VERSION ""

NS_ :

BS_:

BU_: Turbocharger OnBoardDataLogger OffBoardDiagnosticTool2 OffBoardDiagnosticTool1 FileServer ParkingBrakeController SeatControl2 FanDriveController SteeringColumnUnit CommunicationUnitRadio CommunicationUnitSatellite CommunicationUnitCellular PropulsionBatteryCharger ChassisController2 ChassisController1 EngineValveControl AuxiliaryHeater2 AuxiliaryHeater1 ClutchUnit RampControl InformationSystem1 SuspensionSystemController2 OilSensor VehicleDynamicStability ExhaustEmissionController TransmissionDisplay2 TransmissionDisplay1 ClimateControl2 WaterPumpController RearAxleSteeringController LightingOperatorControl SeatController1 IgnitionController2 IgnitionController1 TirePressureController CabController2 CabController1 PneumaticSystemController SuspensionSystemController1 HydraulicPumpController EnduranceBrakingSystem RetarderExhaustEngine2 OnBoardDiagnosticUnit HeadwayController RetarderExhaustEngine1 CabDisplay1 ManagementComputer VirtualTerminal OffVehicleGateway PowerTakeOffFront HitchControl AuxiliaryValveControl BodyController TractorTrailerBridge1 StarterSystem ElectricalSystem VehicleSecurity VehicleNavigation AerodynamicControl ElectricalChargingSystem ClimateControl1 TripRecorder InstrumentCluster SuspensionDriveAxle2 SuspensionDriveAxle1 SuspensionSteerAxle SteeringController FuelSystem CruiseControl RetarderDriveline RetarderEngine BrakesDriveAxle2 BrakesDriveAxle1 BrakesSystemController BrakesSteerAxle AxleDrive2 AxleDrive1 AxleSteering PowerTakeOff ShiftConsoleSecondary ShiftConsolePrimary Transmission2 Transmission1 Engine2 Engine1

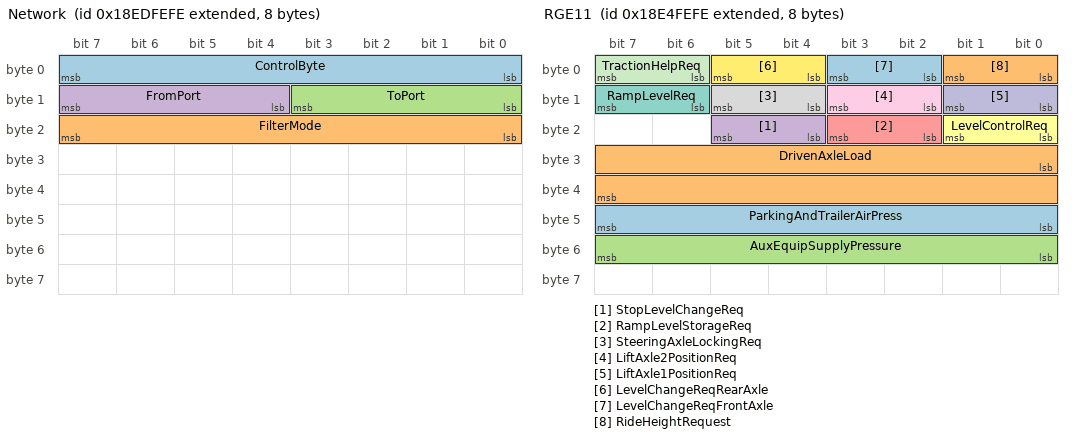
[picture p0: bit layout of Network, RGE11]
BO_ 2565734142 Network: 8 Vector__XXX
 SG_ ControlByte : 0|8@1+ (1,0) [0|255] "" Vector__XXX
 SG_ FilterMode : 16|8@1+ (1,0) [0|255] "" Vector__XXX
 SG_ ToPort : 8|4@1+ (1,0) [0|15] "" Vector__XXX
 SG_ FromPort : 12|4@1+ (1,0) [0|15] "" Vector__XXX

BO_ 2565144318 RGE11: 8 Vector__XXX
 SG_ ParkingAndTrailerAirPress : 40|8@1+ (8,0) [0|2000] "kPa" Vector__XXX
 SG_ DrivenAxleLoad : 24|16@1+ (2,0) [0|128510] "kg" Vector__XXX
 SG_ AuxEquipSupplyPressure : 48|8@1+ (8,0) [0|2000] "kPa" Vector__XXX
 SG_ StopLevelChangeReq : 20|2@1+ (1,0) [0|3] "" Vector__XXX
 SG_ RampLevelStorageReq : 18|2@1+ (1,0) [0|3] "" Vector__XXX
 SG_ LevelControlReq : 16|2@1+ (1,0) [0|3] "" Vector__XXX
 SG_ RampLevelReq : 14|2@1+ (1,0) [0|3] "" Vector__XXX
 SG_ SteeringAxleLockingReq : 12|2@1+ (1,0) [0|3] "" Vector__XXX
 SG_ LiftAxle2PositionReq : 10|2@1+ (1,0) [0|3] "" Vector__XXX
 SG_ LiftAxle1PositionReq : 8|2@1+ (1,0) [0|3] "" Vector__XXX
 SG_ TractionHelpReq : 6|2@1+ (1,0) [0|3] "" Vector__XXX
 SG_ LevelChangeReqRearAxle : 4|2@1+ (1,0) [0|3] "" Vector__XXX
 SG_ LevelChangeReqFrontAxle : 2|2@1+ (1,0) [0|3] "" Vector__XXX
 SG_ RideHeightRequest : 0|2@1+ (1,0) [0|3] "" Vector__XXX

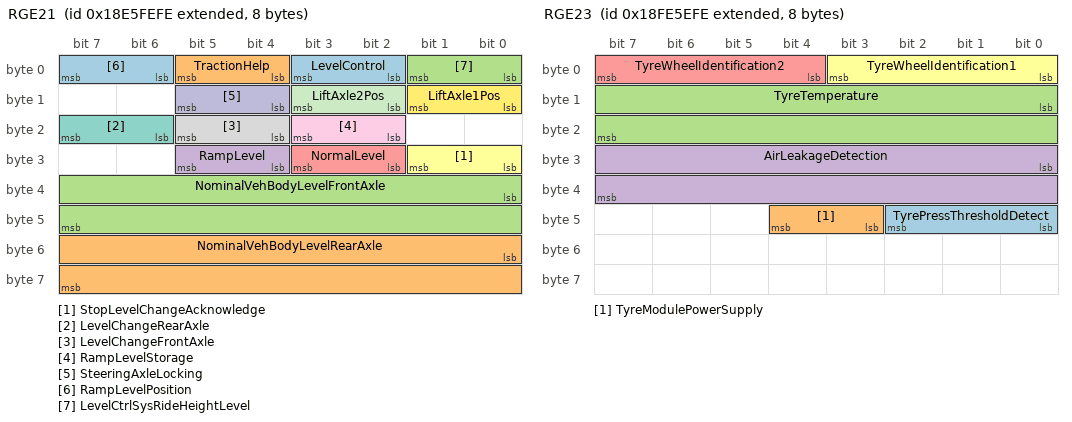
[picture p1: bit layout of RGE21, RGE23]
BO_ 2565209854 RGE21: 8 Vector__XXX
 SG_ LevelControl : 2|2@1+ (1,0) [0|1] "" Vector__XXX
 SG_ NominalVehBodyLevelRearAxle : 48|16@1+ (1,0) [0|64255] "mm" Vector__XXX
 SG_ NominalVehBodyLevelFrontAxle : 32|16@1+ (1,0) [0|64255] "mm" Vector__XXX
 SG_ RampLevel : 28|2@1+ (1,0) [0|1] "" Vector__XXX
 SG_ NormalLevel : 26|2@1+ (1,0) [0|3] "" Vector__XXX
 SG_ StopLevelChangeAcknowledge : 24|2@1+ (1,0) [0|1] "" Vector__XXX
 SG_ LevelChangeRearAxle : 22|2@1+ (1,0) [0|1] "" Vector__XXX
 SG_ LevelChangeFrontAxle : 20|2@1+ (1,0) [0|1] "" Vector__XXX
 SG_ RampLevelStorage : 18|2@1+ (1,0) [0|1] "" Vector__XXX
 SG_ SteeringAxleLocking : 12|2@1+ (1,0) [0|3] "" Vector__XXX
 SG_ LiftAxle2Pos : 10|2@1+ (1,0) [0|3] "" Vector__XXX
 SG_ LiftAxle1Pos : 8|2@1+ (1,0) [0|3] "" Vector__XXX
 SG_ RampLevelPosition : 6|2@1+ (1,0) [0|3] "" Vector__XXX
 SG_ TractionHelp : 4|2@1+ (1,0) [0|1] "" Vector__XXX
 SG_ LevelCtrlSysRideHeightLevel : 0|2@1+ (1,0) [0|1] "" Vector__XXX

BO_ 2566806782 RGE22: 8 Vector__XXX
 SG_ RelVehBodyLevelRearAxle : 16|16@1+ (1,0) [0|64255] "mm" Vector__XXX
 SG_ RelVehBodyLevelFrontAxle : 0|16@1+ (1,-32000) [-32000|32255] "mm" Vector__XXX

BO_ 2566807294 RGE23: 8 Vector__XXX
 SG_ TyrePressThresholdDetect : 40|3@1+ (1,0) [0|7] "" Vector__XXX
 SG_ TyreModulePowerSupply : 43|2@1+ (1,0) [0|1] "" Vector__XXX
 SG_ TyreTemperature : 8|16@1+ (0.03125,-273) [-273|1735] "°C" Vector__XXX
 SG_ AirLeakageDetection : 24|16@1+ (0.1,0) [0|6425.5] "Pa/s" Vector__XXX
 SG_ TyreWheelIdentification2 : 4|4@1+ (1,0) [0|15] "" Vector__XXX
 SG_ TyreWheelIdentification1 : 0|4@1+ (1,0) [0|15] "" Vector__XXX

BO_ 2566764798 DM26: 8 Vector__XXX
 SG_ NMHCConvertingCatalystCompleted : 60|1@1+ (1,0) [0|1] "" Vector__XXX
 SG_ NMHCConvertingCatalystEnabled : 44|1@1+ (1,0) [0|1] "" Vector__XXX
 SG_ NOxConvertingCatalystAdsorberCom : 59|1@1+ (1,0) [0|1] "" Vector__XXX
 SG_ NOxConvertingCatalystAdsorberEna : 43|1@1+ (1,0) [0|1] "" Vector__XXX
 SG_ DieselParticulateFilterCompleted : 58|1@1+ (1,0) [0|1] "" Vector__XXX
 SG_ DieselParticulateFilterEnabled : 42|1@1+ (1,0) [0|1] "" Vector__XXX
 SG_ BoostPressureControlSystemComple : 57|1@1+ (1,0) [0|1] "" Vector__XXX
 SG_ BoostPressureControlSystemEnable : 41|1@1- (1,0) [0|0] "" Vector__XXX
 SG_ MisfireMonitoringComplete : 28|1@1+ (1,0) [0|1] "" Vector__XXX
 SG_ MisfireMonitoringEnabled : 24|1@1+ (1,0) [0|0] "" Vector__XXX
 SG_ FuelSystemMonitoringEnabled : 25|1@1+ (1,0) [0|1] "" Vector__XXX
 SG_ ComprehensiveComptMonComplete : 30|1@1+ (1,0) [0|1] "" Vector__XXX
 SG_ ComprehensiveCompMonEnabled : 26|1@1+ (1,0) [0|1] "" Vector__XXX
 SG_ SecondAirSystemMonComplete : 51|1@1+ (1,0) [0|1] "" Vector__XXX
 SG_ SecondAirSystemMonEnabled : 35|1@1+ (1,0) [0|1] "" Vector__XXX
 SG_ OxygenSensorMonComplete : 53|1@1+ (1,0) [0|1] "" Vector__XXX
 SG_ OxygenSensorMonEnabled : 37|1@1+ (1,0) [0|1] "" Vector__XXX
 SG_ OxygenSensorHeaterMonComplete : 54|1@1+ (1,0) [0|1] "" Vector__XXX
 SG_ OxygenSensorHeaterMonEnabled : 38|1@1+ (1,0) [0|1] "" Vector__XXX
 SG_ HeatedCatalystMonComplete : 49|1@1+ (1,0) [0|1] "" Vector__XXX
 SG_ HeatedCatalystMonEnabled : 33|1@1+ (1,0) [0|1] "" Vector__XXX
 SG_ EvaporativeSystemMonComplete : 50|1@1+ (1,0) [0|1] "" Vector__XXX
 SG_ EvaporativeSystemMonEnabled : 34|1@1+ (1,0) [0|1] "" Vector__XXX
 SG_ EGRSystemMonitoringComplete : 55|1@1+ (1,0) [0|1] "" Vector__XXX
 SG_ EGRSystemMonitoringEnabled : 39|1@1+ (1,0) [0|1] "" Vector__XXX
 SG_ ColdStartAidSystemMonComplete : 56|1@1+ (1,0) [0|1] "" Vector__XXX
 SG_ ColdStartAidSystemMonEnabled : 40|1@1+ (1,0) [0|1] "" Vector__XXX
 SG_ CatalystMonComplete : 48|1@1+ (1,0) [0|1] "" Vector__XXX
 SG_ CatalystMonEnabled : 32|1@1+ (1,0) [0|1] "" Vector__XXX
 SG_ ACSystemRefrigerantMonComplete : 52|1@1+ (1,0) [0|1] "" Vector__XXX
 SG_ ACSystemRefrigerantMonEnabled : 36|1@1+ (1,0) [0|1] "" Vector__XXX
 SG_ FuelSystemMonitoringComplete : 29|1@1+ (1,0) [0|1] "" Vector__XXX
 SG_ NumOfWarmUpsSinceDTCsCleared : 16|8@1+ (1,0) [0|250] "" Vector__XXX
 SG_ TimeSinceEngineStart : 0|16@1+ (1,0) [0|64255] "sec" Vector__XXX

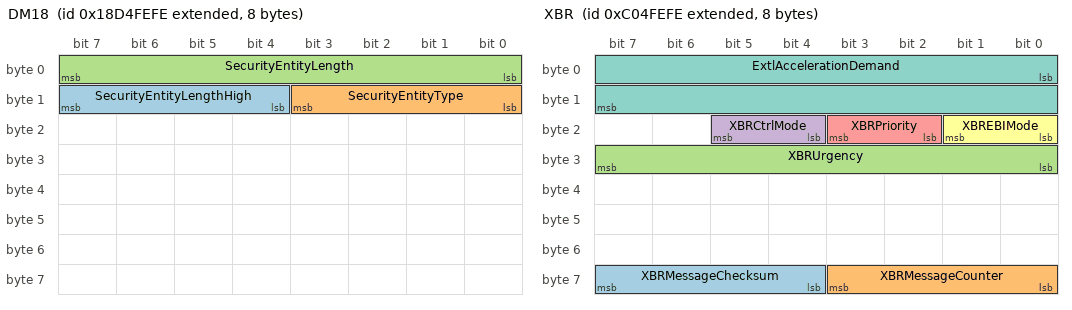
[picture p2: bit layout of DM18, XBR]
BO_ 2564095742 DM18: 8 Vector__XXX
 SG_ SecurityEntityLengthHigh : 12|4@1+ (1,0) [0|255] "Byte" Vector__XXX
 SG_ SecurityEntityType : 8|4@1+ (1,0) [0|15] "" Vector__XXX
 SG_ SecurityEntityLength : 0|8@1+ (1,0) [0|1785] "Byte" Vector__XXX

BO_ 2349137662 XBR: 8 Vector__XXX
 SG_ XBRMessageChecksum : 60|4@1+ (1,0) [0|15] "" Vector__XXX
 SG_ XBRMessageCounter : 56|4@1+ (1,0) [0|15] "" Vector__XXX
 SG_ XBRUrgency : 24|8@1+ (1,0) [0|100] "%" Vector__XXX
 SG_ XBRCtrlMode : 20|2@1+ (1,0) [0|3] "" Vector__XXX
 SG_ XBRPriority : 18|2@1+ (1,0) [0|3] "" Vector__XXX
 SG_ XBREBIMode : 16|2@1+ (1,0) [0|3] "" Vector__XXX
 SG_ ExtlAccelerationDemand : 0|16@1+ (1,-15.687) [-15.687|15.687] "m/s²" Vector__XXX

BO_ 2566848510 WFI: 8 Vector__XXX
 SG_ WaterInFuelIndicator : 0|2@1+ (1,0) [0|3] "" Vector__XXX

BO_ 2566843134 VW: 8 Vector__XXX
 SG_ AxleLocation M : 0|8@1+ (1,0) [0|255] "" Vector__XXX
 SG_ CargoWeight_30 m48 : 40|16@1+ (2,0) [0|128510] "kg" Vector__XXX
 SG_ CargoWeight_20 m32 : 40|16@1+ (2,0) [0|128510] "kg" Vector__XXX
 SG_ CargoWeight_10 m16 : 40|16@1+ (2,0) [0|128510] "kg" Vector__XXX
 SG_ CargoWeight_00 m0 : 40|16@1+ (2,0) [0|128510] "kg" Vector__XXX
 SG_ TrailerWeight_30 m48 : 24|16@1+ (2,0) [0|128510] "kg" Vector__XXX
 SG_ TrailerWeight_20 m32 : 24|16@1+ (2,0) [0|128510] "kg" Vector__XXX
 SG_ TrailerWeight_10 m16 : 24|16@1+ (2,0) [0|128510] "kg" Vector__XXX
 SG_ TrailerWeight_00 m0 : 24|16@1+ (2,0) [0|128510] "kg" Vector__XXX
 SG_ AxleWeight_30 m48 : 8|16@1+ (0.5,0) [0|32127.5] "kg" Vector__XXX
 SG_ AxleWeight_20 m32 : 8|16@1+ (0.5,0) [0|32127.5] "kg" Vector__XXX
 SG_ AxleWeight_10 m16 : 8|16@1+ (0.5,0) [0|32127.5] "kg" Vector__XXX
 SG_ AxleWeight_00 m0 : 8|16@1+ (0.5,0) [0|32127.5] "kg" Vector__XXX

BO_ 2566804222 VEP3: 8 Vector__XXX
 SG_ NetBatteryCurrent : 16|16@1+ (0.05,-1600) [-1600|1612.75] "A" Vector__XXX
 SG_ AltCurrent : 0|16@1+ (0.05,-1600) [-1600|1612.75] "A" Vector__XXX

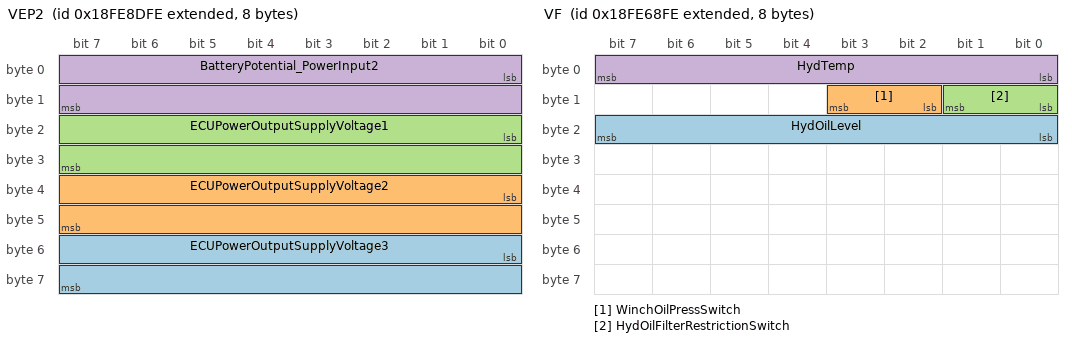
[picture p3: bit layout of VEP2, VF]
BO_ 2566819326 VEP2: 8 Vector__XXX
 SG_ ECUPowerOutputSupplyVoltage3 : 48|16@1+ (0.05,0) [0|3212.75] "V" Vector__XXX
 SG_ ECUPowerOutputSupplyVoltage2 : 32|16@1+ (0.05,0) [0|3212.75] "V" Vector__XXX
 SG_ ECUPowerOutputSupplyVoltage1 : 16|16@1+ (0.05,0) [0|3212.75] "V" Vector__XXX
 SG_ BatteryPotential_PowerInput2 : 0|16@1+ (0.05,0) [0|3212.75] "V" Vector__XXX

BO_ 2566845438 VP: 8 Vector__XXX
 SG_ Longitude : 32|32@1- (1E-007,0) [-180|180] "deg" Vector__XXX
 SG_ Latitude : 0|32@1- (1E-007,0) [-90|90] "deg" Vector__XXX

BO_ 2566843646 VI: 8 Vector__XXX
 SG_ VehicleIdentificationNumber : 0|8@1+ (1.02,0) [0|255] "per byte" Vector__XXX

BO_ 2566842366 VH: 8 Vector__XXX
 SG_ TotalPowerTakeoffHours : 32|32@1+ (0.05,0) [0|210554060.75] "hr" Vector__XXX
 SG_ TotalVehicleHours : 0|32@1+ (0.05,0) [0|210554060.75] "hr" Vector__XXX

BO_ 2566809854 VF: 8 Vector__XXX
 SG_ HydOilLevel : 16|8@1+ (0.4,0) [0|100] "%" Vector__XXX
 SG_ WinchOilPressSwitch : 10|2@1+ (1,0) [0|3] "" Vector__XXX
 SG_ HydOilFilterRestrictionSwitch : 8|2@1+ (1,0) [0|3] "" Vector__XXX
 SG_ HydTemp : 0|8@1+ (1,-40) [-40|210] "deg C" Vector__XXX

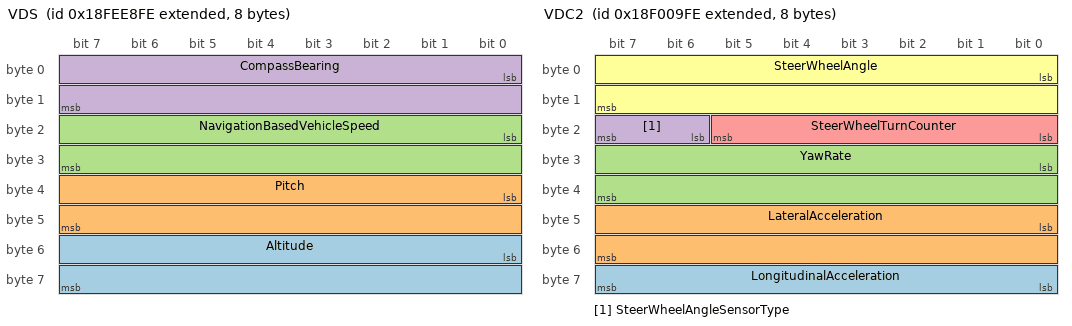
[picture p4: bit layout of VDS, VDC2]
BO_ 2566842622 VDS: 8 Vector__XXX
 SG_ Altitude : 48|16@1+ (0.125,-2500) [-2500|5531.875] "m" Vector__XXX
 SG_ Pitch : 32|16@1+ (0.0078124659559567,-200) [-200|301.99] "deg" Vector__XXX
 SG_ NavigationBasedVehicleSpeed : 16|16@1+ (0.0039062485409696,0) [0|250.996] "km/h" Vector__XXX
 SG_ CompassBearing : 0|16@1+ (0.0078124659559567,0) [0|501.99] "deg" Vector__XXX

BO_ 2566832638 VDHR: 8 Vector__XXX
 SG_ HighResolutionTripDistance : 32|32@1+ (0.0049999999821898,0) [0|21055406] "km" Vector__XXX
 SG_ HghRsolutionTotalVehicleDistance : 0|32@1+ (0.0049999999821898,0) [0|21055406] "km" Vector__XXX

BO_ 2565868030 VDC2: 8 Vector__XXX
 SG_ LongitudinalAcceleration : 56|8@1+ (0.1,-12.5) [-12.5|12.5] "m/s²" Vector__XXX
 SG_ LateralAcceleration : 40|16@1+ (0.00048827328612559,-15.687) [-15.687|15.687] "m/s²" Vector__XXX
 SG_ YawRate : 24|16@1+ (0.00012201385106217,-3.92) [-3.92|3.92] "rad/s" Vector__XXX
 SG_ SteerWheelAngleSensorType : 22|2@1+ (1,0) [0|3] "" Vector__XXX
 SG_ SteerWheelTurnCounter : 16|6@1+ (1,-32) [-32|29] "turns" Vector__XXX
 SG_ SteerWheelAngle : 0|16@1+ (0.00097654657225119,-31.374) [-31.374|31.374] "rad" Vector__XXX

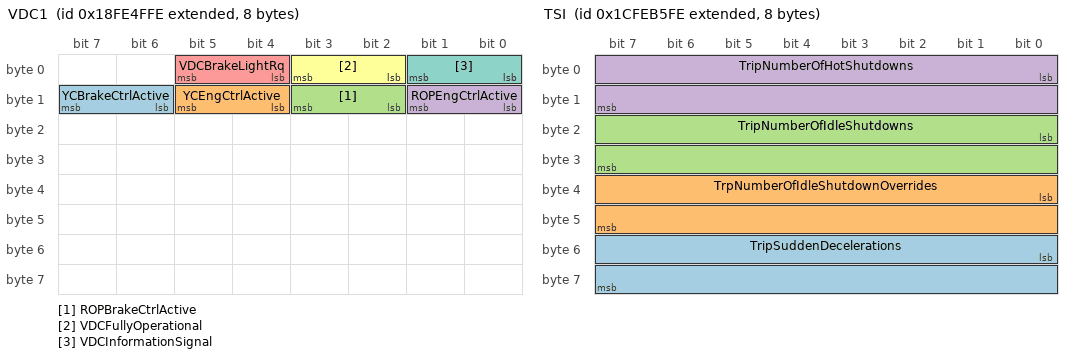
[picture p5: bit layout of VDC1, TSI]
BO_ 2566803454 VDC1: 8 Vector__XXX
 SG_ YCBrakeCtrlActive : 14|2@1+ (1,0) [0|3] "" Vector__XXX
 SG_ YCEngCtrlActive : 12|2@1+ (1,0) [0|3] "" Vector__XXX
 SG_ ROPBrakeCtrlActive : 10|2@1+ (1,0) [0|3] "" Vector__XXX
 SG_ ROPEngCtrlActive : 8|2@1+ (1,0) [0|3] "" Vector__XXX
 SG_ VDCBrakeLightRq : 4|2@1+ (1,0) [0|3] "" Vector__XXX
 SG_ VDCFullyOperational : 2|2@1+ (1,0) [0|3] "" Vector__XXX
 SG_ VDCInformationSignal : 0|2@1+ (1,0) [0|3] "" Vector__XXX

BO_ 2566840574 VD: 8 Vector__XXX
 SG_ TotalVehicleDistance : 32|32@1+ (0.12500000000594,0) [0|526385151.9] "km" Vector__XXX
 SG_ TripDistance : 0|32@1+ (0.12500000000594,0) [0|526385151.9] "km" Vector__XXX

BO_ 2633938686 TVI: 8 Vector__XXX
 SG_ TripCruiseDistance : 16|32@1+ (0.12500000000594,0) [0|526385151.9] "km" Vector__XXX
 SG_ TripMaxVehicleSpeed : 0|16@1+ (0.0039062485409696,0) [0|250.996] "km/h" Vector__XXX

BO_ 2633937150 TTI2: 20 Vector__XXX
 SG_ TripAirCompressorOnTime : 128|32@1+ (0.05,0) [0|210554060.75] "hr" Vector__XXX
 SG_ TripIdleTime : 96|32@1+ (0.05,0) [0|210554060.75] "hr" Vector__XXX
 SG_ TripEngRunningTime : 64|32@1+ (0.05,0) [0|210554060.75] "hr" Vector__XXX
 SG_ TripCruiseTime : 0|32@1+ (0.05,0) [0|210554060.75] "hr" Vector__XXX
 SG_ TripPTOGovernorTime : 32|32@1+ (0.05,0) [0|210554060.75] "hr" Vector__XXX

BO_ 2633938174 TTI1: 16 Vector__XXX
 SG_ TripTimeInDerateByEng : 96|32@1+ (0.05,0) [0|210554060.75] "hr" Vector__XXX
 SG_ TripTimeInGearDown : 64|32@1+ (0.05,0) [0|210554060.75] "hr" Vector__XXX
 SG_ TripTimeInTopGear : 32|32@1+ (0.05,0) [0|210554060.75] "hr" Vector__XXX
 SG_ TripTimeInVSL : 0|32@1+ (0.05,0) [0|210554060.75] "hr" Vector__XXX

BO_ 2633938430 TSI: 8 Vector__XXX
 SG_ TripSuddenDecelerations : 48|16@1+ (1,0) [0|64255] "counts" Vector__XXX
 SG_ TrpNumberOfIdleShutdownOverrides : 32|16@1+ (1,0) [0|64255] "counts" Vector__XXX
 SG_ TripNumberOfIdleShutdowns : 16|16@1+ (1,0) [0|64255] "counts" Vector__XXX
 SG_ TripNumberOfHotShutdowns : 0|16@1+ (1,0) [0|64255] "counts" Vector__XXX

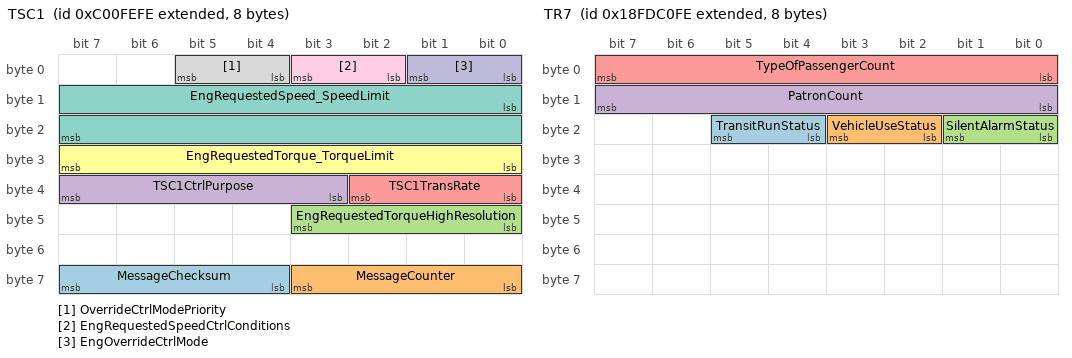
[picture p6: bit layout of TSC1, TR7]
BO_ 2348875518 TSC1: 8 Vector__XXX
 SG_ MessageChecksum : 60|4@1+ (1,0) [0|15] "" Vector__XXX
 SG_ MessageCounter : 56|4@1+ (1,0) [0|15] "" Vector__XXX
 SG_ EngRequestedTorqueHighResolution : 40|4@1+ (1,0) [0|0.875] "%" Vector__XXX
 SG_ TSC1CtrlPurpose : 35|5@1+ (1,0) [0|31] "" Vector__XXX
 SG_ TSC1TransRate : 32|3@1+ (1,0) [0|7] "" Vector__XXX
 SG_ EngRequestedTorque_TorqueLimit : 24|8@1+ (1,-125) [-125|125] "%" Vector__XXX
 SG_ EngRequestedSpeed_SpeedLimit : 8|16@1+ (0.125,0) [0|0] "rpm" Vector__XXX
 SG_ OverrideCtrlModePriority : 4|2@1+ (1,0) [0|3] "" Vector__XXX
 SG_ EngRequestedSpeedCtrlConditions : 2|2@1+ (1,0) [0|3] "" Vector__XXX
 SG_ EngOverrideCtrlMode : 0|2@1+ (1,0) [0|3] "" Vector__XXX

BO_ 2566766846 TR7: 8 Vector__XXX
 SG_ TransitRunStatus : 20|2@1+ (1,0) [0|3] "" Vector__XXX
 SG_ VehicleUseStatus : 18|2@1+ (1,0) [0|3] "" Vector__XXX
 SG_ SilentAlarmStatus : 16|2@1+ (1,0) [0|3] "" Vector__XXX
 SG_ PatronCount : 8|8@1+ (1,0) [0|250] "" Vector__XXX
 SG_ TypeOfPassengerCount : 0|8@1+ (1.02,0) [0|255] "" Vector__XXX

BO_ 2566765310 TR6: 8 Vector__XXX
 SG_ FareboxAlarmIdentifier : 8|7@1+ (1,0) [0|127] "" Vector__XXX
 SG_ FareboxEmergencyStatus : 0|2@1+ (1,0) [0|3] "" Vector__XXX

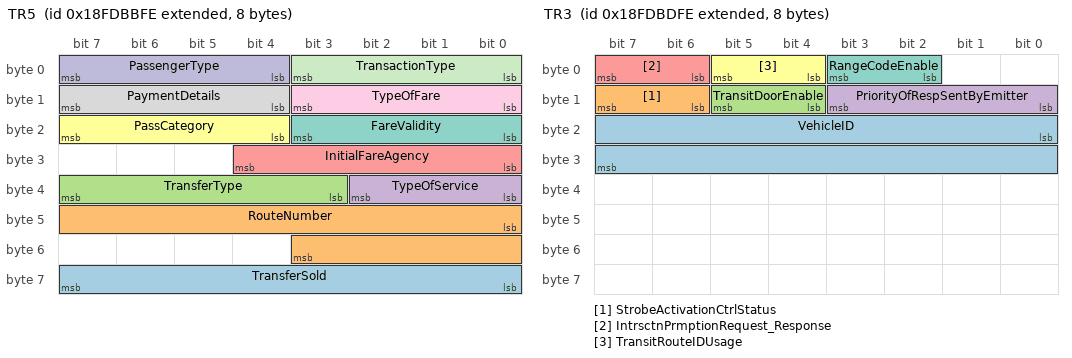
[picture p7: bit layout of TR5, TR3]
BO_ 2566765566 TR5: 8 Vector__XXX
 SG_ TransferSold : 56|8@1+ (1.02,0) [0|255] "" Vector__XXX
 SG_ RouteNumber : 40|12@1+ (1,0) [0|4095] "" Vector__XXX
 SG_ TransferType : 35|5@1+ (1,0) [0|31] "" Vector__XXX
 SG_ TypeOfService : 32|3@1+ (1,0) [0|7] "" Vector__XXX
 SG_ InitialFareAgency : 24|5@1+ (1,0) [0|31] "" Vector__XXX
 SG_ PassCategory : 20|4@1+ (1,0) [0|15] "" Vector__XXX
 SG_ FareValidity : 16|4@1+ (1,0) [0|15] "" Vector__XXX
 SG_ PaymentDetails : 12|4@1+ (1,0) [0|15] "" Vector__XXX
 SG_ TypeOfFare : 8|4@1+ (1,0) [0|15] "" Vector__XXX
 SG_ PassengerType : 4|4@1+ (1,0) [0|15] "" Vector__XXX
 SG_ TransactionType : 0|4@1+ (1,0) [0|15] "" Vector__XXX

BO_ 2566765822 TR4: 15 Vector__XXX
 SG_ DriversFareboxSecurityCode : 104|16@1+ (1.0199206287448,0) [0|65535] "counts" Vector__XXX
 SG_ AssignedBlock : 88|16@1+ (1.0199206287448,0) [0|65535] "counts" Vector__XXX
 SG_ AssignedRun : 72|16@1+ (1.0199206287448,0) [0|65535] "counts" Vector__XXX
 SG_ AssignedRoute : 56|16@1+ (1.0199206287448,0) [0|65535] "counts" Vector__XXX
 SG_ PatternNumber : 40|16@1+ (1.0199206287448,0) [0|65535] "counts" Vector__XXX
 SG_ TripNumber : 24|16@1+ (1.0199206287448,0) [0|65535] "counts" Vector__XXX
 SG_ FarePresets : 16|8@1+ (1.02,0) [0|255] "" Vector__XXX
 SG_ TripDirection : 8|4@1+ (1,0) [0|15] "" Vector__XXX
 SG_ TripStatus : 2|3@1+ (1,0) [0|0] "" Vector__XXX
 SG_ FareboxServiceStatus : 0|2@1+ (1,0) [0|3] "" Vector__XXX

BO_ 2566766078 TR3: 8 Vector__XXX
 SG_ VehicleID : 16|16@1+ (1.0199206287448,0) [0|65535] "counts" Vector__XXX
 SG_ StrobeActivationCtrlStatus : 14|2@1+ (1,0) [0|3] "" Vector__XXX
 SG_ TransitDoorEnable : 12|2@1+ (1,0) [0|3] "" Vector__XXX
 SG_ PriorityOfRespSentByEmitter : 8|4@1+ (1,0) [0|15] "" Vector__XXX
 SG_ IntrsctnPrmptionRequest_Response : 6|2@1+ (1,0) [0|3] "" Vector__XXX
 SG_ TransitRouteIDUsage : 4|2@1+ (1,0) [0|3] "" Vector__XXX
 SG_ RangeCodeEnable : 2|2@1+ (1,0) [0|3] "" Vector__XXX

BO_ 2566766590 TR2: 8 Vector__XXX
 SG_ NmbrOfBytsInThMlpstIdntification : 0|8@1+ (1,0) [0|250] "" Vector__XXX

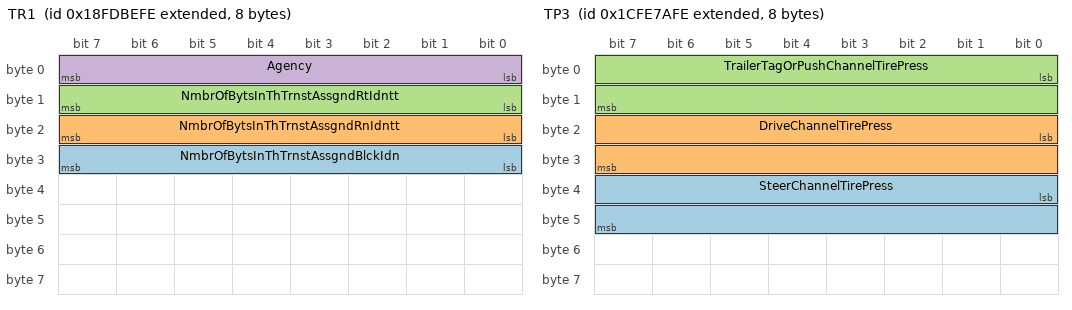
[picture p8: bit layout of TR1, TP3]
BO_ 2566766334 TR1: 8 Vector__XXX
 SG_ NmbrOfBytsInThTrnstAssgndBlckIdn : 24|8@1+ (1,0) [0|250] "" Vector__XXX
 SG_ NmbrOfBytsInThTrnstAssgndRnIdntt : 16|8@1+ (1,0) [0|250] "" Vector__XXX
 SG_ NmbrOfBytsInThTrnstAssgndRtIdntt : 8|8@1+ (1,0) [0|250] "" Vector__XXX
 SG_ Agency : 0|8@1+ (1.02,0) [0|255] "" Vector__XXX

BO_ 2561605374 TPRS: 8 Vector__XXX
 SG_ ReferenceTirePressSetting_33 m51 : 8|8@1+ (8,0) [0|2000] "kPa" Vector__XXX
 SG_ ReferenceTirePressSetting_32 m50 : 8|8@1+ (8,0) [0|2000] "kPa" Vector__XXX
 SG_ ReferenceTirePressSetting_31 m49 : 8|8@1+ (8,0) [0|2000] "kPa" Vector__XXX
 SG_ ReferenceTirePressSetting_30 m48 : 8|8@1+ (8,0) [0|2000] "kPa" Vector__XXX
 SG_ ReferenceTirePressSetting_23 m35 : 8|8@1+ (8,0) [0|2000] "kPa" Vector__XXX
 SG_ ReferenceTirePressSetting_22 m34 : 8|8@1+ (8,0) [0|2000] "kPa" Vector__XXX
 SG_ ReferenceTirePressSetting_21 m33 : 8|8@1+ (8,0) [0|2000] "kPa" Vector__XXX
 SG_ ReferenceTirePressSetting_20 m32 : 8|8@1+ (8,0) [0|2000] "kPa" Vector__XXX
 SG_ ReferenceTirePressSetting_13 m19 : 8|8@1+ (8,0) [0|2000] "kPa" Vector__XXX
 SG_ ReferenceTirePressSetting_12 m18 : 8|8@1+ (8,0) [0|2000] "kPa" Vector__XXX
 SG_ ReferenceTirePressSetting_11 m17 : 8|8@1+ (8,0) [0|2000] "kPa" Vector__XXX
 SG_ ReferenceTirePressSetting_10 m16 : 8|8@1+ (8,0) [0|2000] "kPa" Vector__XXX
 SG_ ReferenceTirePressSetting_01 m1 : 8|8@1+ (8,0) [0|2000] "kPa" Vector__XXX
 SG_ ReferenceTirePressSetting_00 m0 : 8|8@1+ (8,0) [0|2000] "kPa" Vector__XXX
 SG_ TireLocation M : 0|8@1+ (1,0) [0|255] "" Vector__XXX

BO_ 2566765054 TPRI: 8 Vector__XXX
 SG_ ReferenceTirePress_33 m51 : 8|8@1+ (8,0) [0|2000] "kPa" Vector__XXX
 SG_ ReferenceTirePress_32 m50 : 8|8@1+ (8,0) [0|2000] "kPa" Vector__XXX
 SG_ ReferenceTirePress_31 m49 : 8|8@1+ (8,0) [0|2000] "kPa" Vector__XXX
 SG_ ReferenceTirePress_30 m48 : 8|8@1+ (8,0) [0|2000] "kPa" Vector__XXX
 SG_ ReferenceTirePress_23 m35 : 8|8@1+ (8,0) [0|2000] "kPa" Vector__XXX
 SG_ ReferenceTirePress_22 m34 : 8|8@1+ (8,0) [0|2000] "kPa" Vector__XXX
 SG_ ReferenceTirePress_21 m33 : 8|8@1+ (8,0) [0|2000] "kPa" Vector__XXX
 SG_ ReferenceTirePress_20 m32 : 8|8@1+ (8,0) [0|2000] "kPa" Vector__XXX
 SG_ ReferenceTirePress_13 m19 : 8|8@1+ (8,0) [0|2000] "kPa" Vector__XXX
 SG_ ReferenceTirePress_12 m18 : 8|8@1+ (8,0) [0|2000] "kPa" Vector__XXX
 SG_ ReferenceTirePress_11 m17 : 8|8@1+ (8,0) [0|2000] "kPa" Vector__XXX
 SG_ ReferenceTirePress_10 m16 : 8|8@1+ (8,0) [0|2000] "kPa" Vector__XXX
 SG_ ReferenceTirePress_01 m1 : 8|8@1+ (8,0) [0|2000] "kPa" Vector__XXX
 SG_ ReferenceTirePress_00 m0 : 8|8@1+ (8,0) [0|2000] "kPa" Vector__XXX
 SG_ TireLocation M : 0|8@1+ (1,0) [0|255] "" Vector__XXX

BO_ 2633923326 TP3: 8 Vector__XXX
 SG_ SteerChannelTirePress : 32|16@1+ (0.5,0) [0|32127.5] "kPa" Vector__XXX
 SG_ DriveChannelTirePress : 16|16@1+ (0.5,0) [0|32127.5] "kPa" Vector__XXX
 SG_ TrailerTagOrPushChannelTirePress : 0|16@1+ (0.5,0) [0|32127.5] "kPa" Vector__XXX

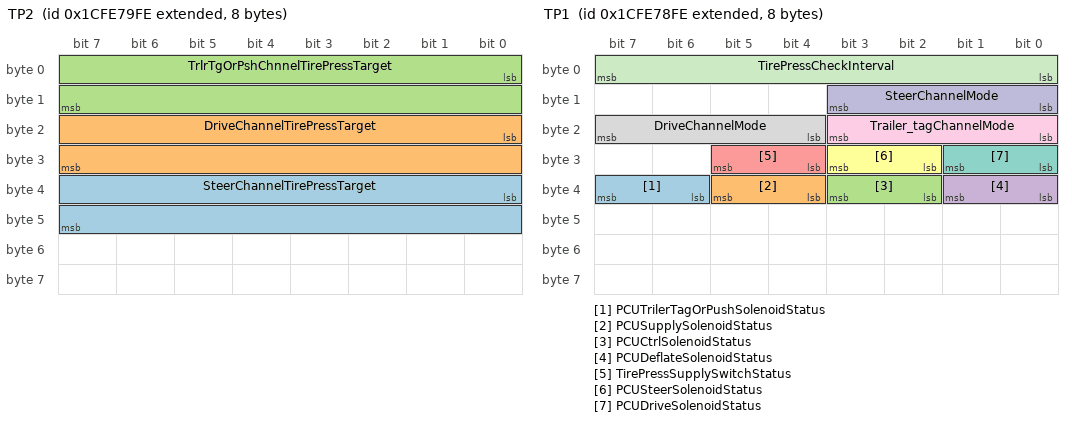
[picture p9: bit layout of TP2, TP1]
BO_ 2633923070 TP2: 8 Vector__XXX
 SG_ SteerChannelTirePressTarget : 32|16@1+ (0.5,0) [0|32127.5] "kPa" Vector__XXX
 SG_ DriveChannelTirePressTarget : 16|16@1+ (0.5,0) [0|32127.5] "kPa" Vector__XXX
 SG_ TrlrTgOrPshChnnelTirePressTarget : 0|16@1+ (0.5,0) [0|32127.5] "kPa" Vector__XXX

BO_ 2633922814 TP1: 8 Vector__XXX
 SG_ PCUTrilerTagOrPushSolenoidStatus : 38|2@1+ (1,0) [0|3] "" Vector__XXX
 SG_ PCUSupplySolenoidStatus : 36|2@1+ (1,0) [0|3] "" Vector__XXX
 SG_ PCUCtrlSolenoidStatus : 34|2@1+ (1,0) [0|3] "" Vector__XXX
 SG_ PCUDeflateSolenoidStatus : 32|2@1+ (1,0) [0|3] "" Vector__XXX
 SG_ TirePressSupplySwitchStatus : 28|2@1+ (1,0) [0|3] "" Vector__XXX
 SG_ PCUSteerSolenoidStatus : 26|2@1+ (1,0) [0|3] "" Vector__XXX
 SG_ PCUDriveSolenoidStatus : 24|2@1+ (1,0) [0|3] "" Vector__XXX
 SG_ DriveChannelMode : 20|4@1+ (1,0) [0|15] "" Vector__XXX
 SG_ Trailer_tagChannelMode : 16|4@1+ (1,0) [0|15] "" Vector__XXX
 SG_ SteerChannelMode : 8|4@1+ (1,0) [0|15] "" Vector__XXX
 SG_ TirePressCheckInterval : 0|8@1+ (1,0) [0|250] "mins" Vector__XXX

BO_ 2566845694 TIRE: 8 Vector__XXX
 SG_ TirePressThresholdDetection_13 m19 : 61|3@1+ (1,0) [0|7] "" Vector__XXX
 SG_ TirePressThresholdDetection_12 m18 : 61|3@1+ (1,0) [0|7] "" Vector__XXX
 SG_ TirePressThresholdDetection_11 m17 : 61|3@1+ (1,0) [0|7] "" Vector__XXX
 SG_ TirePressThresholdDetection_10 m16 : 61|3@1+ (1,0) [0|7] "" Vector__XXX
 SG_ TirePressThresholdDetection_01 m1 : 61|3@1+ (1,0) [0|7] "" Vector__XXX
 SG_ TirePress_33 m51 : 8|8@1+ (4,0) [0|1000] "kPa" Vector__XXX
 SG_ TirePress_32 m50 : 8|8@1+ (4,0) [0|1000] "kPa" Vector__XXX
 SG_ TirePress_31 m49 : 8|8@1+ (4,0) [0|1000] "kPa" Vector__XXX
 SG_ TirePress_30 m48 : 8|8@1+ (4,0) [0|1000] "kPa" Vector__XXX
 SG_ TirePress_23 m35 : 8|8@1+ (4,0) [0|1000] "kPa" Vector__XXX
 SG_ TirePress_22 m34 : 8|8@1+ (4,0) [0|1000] "kPa" Vector__XXX
 SG_ TirePress_21 m33 : 8|8@1+ (4,0) [0|1000] "kPa" Vector__XXX
 SG_ TirePress_20 m32 : 8|8@1+ (4,0) [0|1000] "kPa" Vector__XXX
 SG_ TirePress_13 m19 : 8|8@1+ (4,0) [0|1000] "kPa" Vector__XXX
 SG_ TirePress_12 m18 : 8|8@1+ (4,0) [0|1000] "kPa" Vector__XXX
 SG_ TirePress_11 m17 : 8|8@1+ (4,0) [0|1000] "kPa" Vector__XXX
 SG_ TirePress_10 m16 : 8|8@1+ (4,0) [0|1000] "kPa" Vector__XXX
 SG_ TireAirLeakageRate_33 m51 : 40|16@1+ (0.1,0) [0|6425.5] "Pa/s" Vector__XXX
 SG_ TireAirLeakageRate_32 m50 : 40|16@1+ (0.1,0) [0|6425.5] "Pa/s" Vector__XXX
 SG_ TireAirLeakageRate_31 m49 : 40|16@1+ (0.1,0) [0|6425.5] "Pa/s" Vector__XXX
 SG_ TireAirLeakageRate_30 m48 : 40|16@1+ (0.1,0) [0|6425.5] "Pa/s" Vector__XXX
 SG_ TireAirLeakageRate_23 m35 : 40|16@1+ (0.1,0) [0|6425.5] "Pa/s" Vector__XXX
 SG_ TireAirLeakageRate_22 m34 : 40|16@1+ (0.1,0) [0|6425.5] "Pa/s" Vector__XXX
 SG_ TireAirLeakageRate_21 m33 : 40|16@1+ (0.1,0) [0|6425.5] "Pa/s" Vector__XXX
 SG_ TireAirLeakageRate_20 m32 : 40|16@1+ (0.1,0) [0|6425.5] "Pa/s" Vector__XXX
 SG_ TireAirLeakageRate_13 m19 : 40|16@1+ (0.1,0) [0|6425.5] "Pa/s" Vector__XXX
 SG_ TireAirLeakageRate_12 m18 : 40|16@1+ (0.1,0) [0|6425.5] "Pa/s" Vector__XXX
 SG_ TireAirLeakageRate_11 m17 : 40|16@1+ (0.1,0) [0|6425.5] "Pa/s" Vector__XXX
 SG_ TireAirLeakageRate_10 m16 : 40|16@1+ (0.1,0) [0|6425.5] "Pa/s" Vector__XXX
 SG_ TireAirLeakageRate_01 m1 : 40|16@1+ (0.1,0) [0|6425.5] "Pa/s" Vector__XXX
 SG_ TireAirLeakageRate_00 m0 : 40|16@1+ (0.1,0) [0|6425.5] "Pa/s" Vector__XXX
 SG_ CTIWheelSensorStatus_33 m51 : 32|2@1+ (1,0) [0|3] "" Vector__XXX
 SG_ CTIWheelSensorStatus_32 m50 : 32|2@1+ (1,0) [0|3] "" Vector__XXX
 SG_ CTIWheelSensorStatus_31 m49 : 32|2@1+ (1,0) [0|3] "" Vector__XXX
 SG_ CTIWheelSensorStatus_30 m48 : 32|2@1+ (1,0) [0|3] "" Vector__XXX
 SG_ CTIWheelSensorStatus_23 m35 : 32|2@1+ (1,0) [0|3] "" Vector__XXX
 SG_ CTIWheelSensorStatus_22 m34 : 32|2@1+ (1,0) [0|3] "" Vector__XXX
 SG_ CTIWheelSensorStatus_21 m33 : 32|2@1+ (1,0) [0|3] "" Vector__XXX
 SG_ CTIWheelSensorStatus_20 m32 : 32|2@1+ (1,0) [0|3] "" Vector__XXX
 SG_ CTIWheelSensorStatus_13 m19 : 32|2@1+ (1,0) [0|3] "" Vector__XXX
 SG_ CTIWheelSensorStatus_12 m18 : 32|2@1+ (1,0) [0|3] "" Vector__XXX
 SG_ CTIWheelSensorStatus_11 m17 : 32|2@1+ (1,0) [0|3] "" Vector__XXX
 SG_ CTIWheelSensorStatus_10 m16 : 32|2@1+ (1,0) [0|3] "" Vector__XXX
 SG_ CTIWheelSensorStatus_01 m1 : 32|2@1+ (1,0) [0|3] "" Vector__XXX
 SG_ CTIWheelEndElectricalFault_33 m51 : 36|2@1+ (1,0) [0|3] "" Vector__XXX
 SG_ CTIWheelEndElectricalFault_32 m50 : 36|2@1+ (1,0) [0|3] "" Vector__XXX
 SG_ CTIWheelEndElectricalFault_31 m49 : 36|2@1+ (1,0) [0|3] "" Vector__XXX
 SG_ CTIWheelEndElectricalFault_30 m48 : 36|2@1+ (1,0) [0|3] "" Vector__XXX
 SG_ CTIWheelEndElectricalFault_23 m35 : 36|2@1+ (1,0) [0|3] "" Vector__XXX
 SG_ CTIWheelEndElectricalFault_22 m34 : 36|2@1+ (1,0) [0|3] "" Vector__XXX
 SG_ CTIWheelEndElectricalFault_21 m33 : 36|2@1+ (1,0) [0|3] "" Vector__XXX
 SG_ CTIWheelEndElectricalFault_20 m32 : 36|2@1+ (1,0) [0|3] "" Vector__XXX
 SG_ CTIWheelEndElectricalFault_13 m19 : 36|2@1+ (1,0) [0|3] "" Vector__XXX
 SG_ CTIWheelEndElectricalFault_12 m18 : 36|2@1+ (1,0) [0|3] "" Vector__XXX
 SG_ CTIWheelEndElectricalFault_11 m17 : 36|2@1+ (1,0) [0|3] "" Vector__XXX
 SG_ CTIWheelEndElectricalFault_10 m16 : 36|2@1+ (1,0) [0|3] "" Vector__XXX
 SG_ CTIWheelEndElectricalFault_01 m1 : 36|2@1+ (1,0) [0|3] "" Vector__XXX
 SG_ CTITireStatus_33 m51 : 34|2@1+ (1,0) [0|3] "" Vector__XXX
 SG_ CTITireStatus_32 m50 : 34|2@1+ (1,0) [0|3] "" Vector__XXX
 SG_ CTITireStatus_31 m49 : 34|2@1+ (1,0) [0|3] "" Vector__XXX
 SG_ CTITireStatus_30 m48 : 34|2@1+ (1,0) [0|3] "" Vector__XXX
 SG_ CTITireStatus_23 m35 : 34|2@1+ (1,0) [0|3] "" Vector__XXX
 SG_ CTITireStatus_22 m34 : 34|2@1+ (1,0) [0|3] "" Vector__XXX
 SG_ CTITireStatus_21 m33 : 34|2@1+ (1,0) [0|3] "" Vector__XXX
 SG_ CTITireStatus_20 m32 : 34|2@1+ (1,0) [0|3] "" Vector__XXX
 SG_ CTITireStatus_13 m19 : 34|2@1+ (1,0) [0|3] "" Vector__XXX
 SG_ CTITireStatus_12 m18 : 34|2@1+ (1,0) [0|3] "" Vector__XXX
 SG_ CTITireStatus_11 m17 : 34|2@1+ (1,0) [0|3] "" Vector__XXX
 SG_ CTITireStatus_10 m16 : 34|2@1+ (1,0) [0|3] "" Vector__XXX
 SG_ CTITireStatus_01 m1 : 34|2@1+ (1,0) [0|3] "" Vector__XXX
 SG_ TireTemp_11 m17 : 16|16@1+ (0.03125,-273) [-273|1735] "°C" Vector__XXX
 SG_ TireTemp_33 m51 : 16|16@1+ (0.03125,-273) [-273|1735] "°C" Vector__XXX
 SG_ TireTemp_32 m50 : 16|16@1+ (0.03125,-273) [-273|1735] "°C" Vector__XXX
 SG_ TireTemp_31 m49 : 16|16@1+ (0.03125,-273) [-273|1735] "°C" Vector__XXX
 SG_ TireTemp_30 m48 : 16|16@1+ (0.03125,-273) [-273|1735] "°C" Vector__XXX
 SG_ TireTemp_23 m35 : 16|16@1+ (0.03125,-273) [-273|1735] "°C" Vector__XXX
 SG_ TireTemp_22 m34 : 16|16@1+ (0.03125,-273) [-273|1735] "°C" Vector__XXX
 SG_ TireTemp_21 m33 : 16|16@1+ (0.03125,-273) [-273|1735] "°C" Vector__XXX
 SG_ TireTemp_20 m32 : 16|16@1+ (0.03125,-273) [-273|1735] "°C" Vector__XXX
 SG_ TireTemp_13 m19 : 16|16@1+ (0.03125,-273) [-273|1735] "°C" Vector__XXX
 SG_ TireTemp_12 m18 : 16|16@1+ (0.03125,-273) [-273|1735] "°C" Vector__XXX
 SG_ TireTemp_10 m16 : 16|16@1+ (0.03125,-273) [-273|1735] "°C" Vector__XXX
 SG_ TireTemp_01 m1 : 16|16@1+ (0.03125,-273) [-273|1735] "°C" Vector__XXX
 SG_ TireTemp_00 m0 : 16|16@1+ (0.03125,-273) [-273|1735] "°C" Vector__XXX
 SG_ TirePressThresholdDetection_33 m51 : 61|3@1+ (1,0) [0|7] "" Vector__XXX
 SG_ TirePressThresholdDetection_32 m50 : 61|3@1+ (1,0) [0|7] "" Vector__XXX
 SG_ TirePressThresholdDetection_31 m49 : 61|3@1+ (1,0) [0|7] "" Vector__XXX
 SG_ TirePressThresholdDetection_30 m48 : 61|3@1+ (1,0) [0|7] "" Vector__XXX
 SG_ TirePressThresholdDetection_23 m35 : 61|3@1+ (1,0) [0|7] "" Vector__XXX
 SG_ TirePressThresholdDetection_22 m34 : 61|3@1+ (1,0) [0|7] "" Vector__XXX
 SG_ TirePressThresholdDetection_21 m33 : 61|3@1+ (1,0) [0|7] "" Vector__XXX
 SG_ TirePressThresholdDetection_20 m32 : 61|3@1+ (1,0) [0|7] "" Vector__XXX
 SG_ TirePressThresholdDetection_00 m0 : 61|3@1+ (1,0) [0|7] "" Vector__XXX
 SG_ TirePress_01 m1 : 8|8@1+ (4,0) [0|1000] "kPa" Vector__XXX
 SG_ TirePress_00 m0 : 8|8@1+ (4,0) [0|1000] "kPa" Vector__XXX
 SG_ CTIWheelSensorStatus_00 m0 : 32|2@1+ (1,0) [0|3] "" Vector__XXX
 SG_ CTIWheelEndElectricalFault_00 m0 : 36|2@1+ (1,0) [0|3] "" Vector__XXX
 SG_ CTITireStatus_00 m0 : 34|2@1+ (1,0) [0|3] "" Vector__XXX
 SG_ TireLocation M : 0|8@1+ (1,0) [0|255] "" Vector__XXX

BO_ 2633939966 TFI: 16 Vector__XXX
 SG_ TripFanOnTimeDueToAManualSwitch : 64|32@1+ (0.05,0) [0|210554060.75] "hr" Vector__XXX
 SG_ TripFanOnTime : 0|32@1+ (0.05,0) [0|210554060.75] "hr" Vector__XXX
 SG_ TripFanOnTimeDueToTheA_CSystem : 96|32@1+ (0.05,0) [0|210554060.75] "hr" Vector__XXX
 SG_ TripFanOnTimeDueToTheEngSystem : 32|32@1+ (0.05,0) [0|210554060.75] "hr" Vector__XXX

BO_ 2633939710 TDI: 12 Vector__XXX
 SG_ TripDistanceInTopGear : 64|32@1+ (0.12500000000594,0) [0|526385151.9] "km" Vector__XXX
 SG_ TripGearDownDistance : 32|32@1+ (0.12500000000594,0) [0|526385151.9] "km" Vector__XXX
 SG_ TripDistanceOnVSL : 0|32@1+ (0.12500000000594,0) [0|526385151.9] "km" Vector__XXX

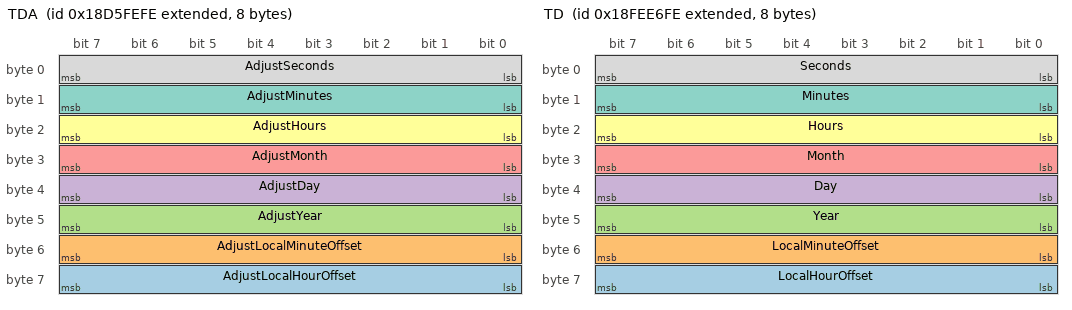
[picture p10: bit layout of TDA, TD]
BO_ 2564161278 TDA: 8 Vector__XXX
 SG_ AdjustLocalHourOffset : 56|8@1+ (1,-125) [-125|125] "hr" Vector__XXX
 SG_ AdjustLocalMinuteOffset : 48|8@1+ (1,-125) [-125|125] "mins" Vector__XXX
 SG_ AdjustYear : 40|8@1+ (1,1985) [1985|2235] "years" Vector__XXX
 SG_ AdjustDay : 32|8@1+ (0.25,0) [0|62.5] "days" Vector__XXX
 SG_ AdjustMonth : 24|8@1+ (1,0) [0|250] "months" Vector__XXX
 SG_ AdjustHours : 16|8@1+ (1,0) [0|250] "hr" Vector__XXX
 SG_ AdjustMinutes : 8|8@1+ (1,0) [0|250] "mins" Vector__XXX
 SG_ AdjustSeconds : 0|8@1+ (0.25,0) [0|62.5] "s" Vector__XXX

BO_ 2566842110 TD: 8 Vector__XXX
 SG_ LocalHourOffset : 56|8@1+ (1,-125) [-125|125] "hr" Vector__XXX
 SG_ LocalMinuteOffset : 48|8@1+ (1,-125) [-125|125] "mins" Vector__XXX
 SG_ Year : 40|8@1+ (1,1985) [1985|2235] "years" Vector__XXX
 SG_ Day : 32|8@1+ (0.25,0) [0|62.5] "days" Vector__XXX
 SG_ Month : 24|8@1+ (1,0) [0|250] "months" Vector__XXX
 SG_ Hours : 16|8@1+ (1,0) [0|250] "hr" Vector__XXX
 SG_ Minutes : 8|8@1+ (1,0) [0|250] "mins" Vector__XXX
 SG_ Seconds : 0|8@1+ (0.25,0) [0|62.5] "s" Vector__XXX

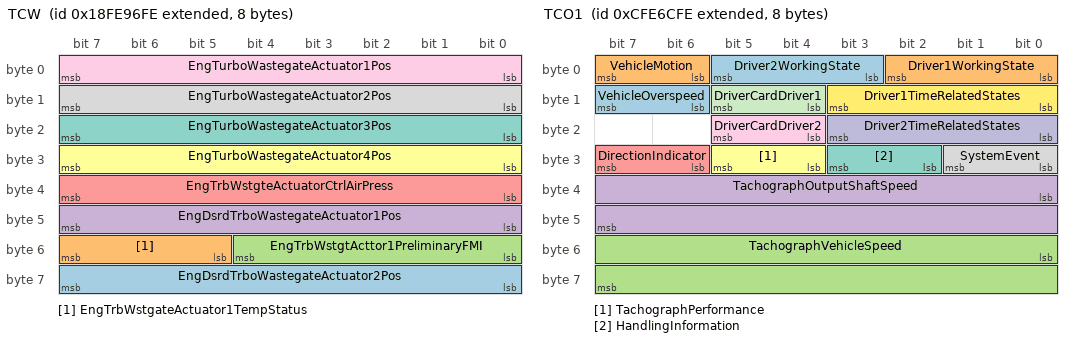
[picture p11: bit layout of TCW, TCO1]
BO_ 2566821630 TCW: 8 Vector__XXX
 SG_ EngDsrdTrboWastegateActuator2Pos : 56|8@1+ (1,0) [0|100] "%" Vector__XXX
 SG_ EngTrbWstgateActuator1TempStatus : 53|3@1+ (1,0) [0|7] "" Vector__XXX
 SG_ EngTrbWstgtActtor1PreliminaryFMI : 48|5@1+ (1,0) [0|31] "" Vector__XXX
 SG_ EngDsrdTrboWastegateActuator1Pos : 40|8@1+ (1,0) [0|100] "%" Vector__XXX
 SG_ EngTrbWstgteActuatorCtrlAirPress : 32|8@1+ (4,0) [0|1000] "kPa" Vector__XXX
 SG_ EngTurboWastegateActuator4Pos : 24|8@1+ (0.4,0) [0|100] "%" Vector__XXX
 SG_ EngTurboWastegateActuator3Pos : 16|8@1+ (0.4,0) [0|100] "%" Vector__XXX
 SG_ EngTurboWastegateActuator2Pos : 8|8@1+ (0.4,0) [0|100] "%" Vector__XXX
 SG_ EngTurboWastegateActuator1Pos : 0|8@1+ (0.4,0) [0|100] "%" Vector__XXX

BO_ 2365484286 TCO1: 8 Vector__XXX
 SG_ VehicleOverspeed : 14|2@1+ (1,0) [0|3] "" Vector__XXX
 SG_ VehicleMotion : 6|2@1+ (1,0) [0|3] "" Vector__XXX
 SG_ TachographVehicleSpeed : 48|16@1+ (0.0039062485409696,0) [0|250.996] "km/h" Vector__XXX
 SG_ TachographOutputShaftSpeed : 32|16@1+ (0.125,0) [0|8031.875] "rpm" Vector__XXX
 SG_ DirectionIndicator : 30|2@1+ (1,0) [0|3] "" Vector__XXX
 SG_ TachographPerformance : 28|2@1+ (1,0) [0|3] "" Vector__XXX
 SG_ HandlingInformation : 26|2@1+ (1,0) [0|3] "" Vector__XXX
 SG_ SystemEvent : 24|2@1+ (1,0) [0|3] "" Vector__XXX
 SG_ DriverCardDriver2 : 20|2@1+ (1,0) [0|3] "" Vector__XXX
 SG_ Driver2TimeRelatedStates : 16|4@1+ (1,0) [0|15] "" Vector__XXX
 SG_ DriverCardDriver1 : 12|2@1+ (1,0) [0|3] "" Vector__XXX
 SG_ Driver1TimeRelatedStates : 8|4@1+ (1,0) [0|15] "" Vector__XXX
 SG_ Driver2WorkingState : 3|3@1+ (1,0) [0|7] "" Vector__XXX
 SG_ Driver1WorkingState : 0|3@1+ (1,0) [0|7] "" Vector__XXX

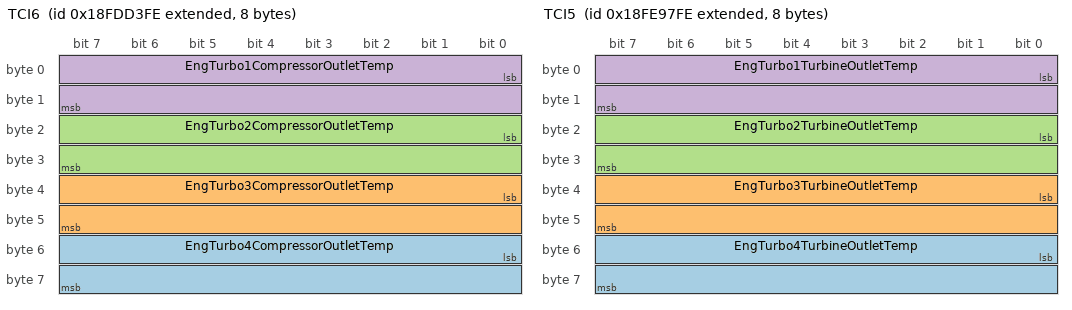
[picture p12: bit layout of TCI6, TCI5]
BO_ 2566771710 TCI6: 8 Vector__XXX
 SG_ EngTurbo4CompressorOutletTemp : 48|16@1+ (0.03125,-273) [-273|1734.96875] "deg C" Vector__XXX
 SG_ EngTurbo3CompressorOutletTemp : 32|16@1+ (0.03125,-273) [-273|1734.96875] "deg C" Vector__XXX
 SG_ EngTurbo2CompressorOutletTemp : 16|16@1+ (0.03125,-273) [-273|1734.96875] "deg C" Vector__XXX
 SG_ EngTurbo1CompressorOutletTemp : 0|16@1+ (0.03125,-273) [-273|1734.96875] "deg C" Vector__XXX

BO_ 2566821886 TCI5: 8 Vector__XXX
 SG_ EngTurbo4TurbineOutletTemp : 48|16@1+ (0.03125,-273) [-273|1734.96875] "deg C" Vector__XXX
 SG_ EngTurbo3TurbineOutletTemp : 32|16@1+ (0.03125,-273) [-273|1734.96875] "deg C" Vector__XXX
 SG_ EngTurbo2TurbineOutletTemp : 16|16@1+ (0.03125,-273) [-273|1734.96875] "deg C" Vector__XXX
 SG_ EngTurbo1TurbineOutletTemp : 0|16@1+ (0.03125,-273) [-273|1734.96875] "deg C" Vector__XXX

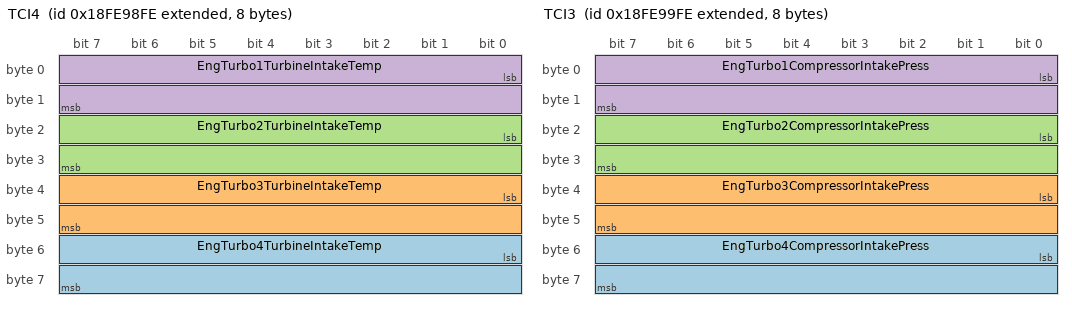
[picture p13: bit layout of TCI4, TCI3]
BO_ 2566822142 TCI4: 8 Vector__XXX
 SG_ EngTurbo4TurbineIntakeTemp : 48|16@1+ (0.03125,-273) [-273|1734.96875] "deg C" Vector__XXX
 SG_ EngTurbo3TurbineIntakeTemp : 32|16@1+ (0.03125,-273) [-273|1734.96875] "deg C" Vector__XXX
 SG_ EngTurbo2TurbineIntakeTemp : 16|16@1+ (0.03125,-273) [-273|1734.96875] "deg C" Vector__XXX
 SG_ EngTurbo1TurbineIntakeTemp : 0|16@1+ (0.03125,-273) [-273|1734.96875] "deg C" Vector__XXX

BO_ 2566822398 TCI3: 8 Vector__XXX
 SG_ EngTurbo4CompressorIntakePress : 48|16@1+ (0.0078124659559567,-250) [-250|251.99] "kPa" Vector__XXX
 SG_ EngTurbo3CompressorIntakePress : 32|16@1+ (0.0078124659559567,-250) [-250|251.99] "kPa" Vector__XXX
 SG_ EngTurbo2CompressorIntakePress : 16|16@1+ (0.0078124659559567,-250) [-250|251.99] "kPa" Vector__XXX
 SG_ EngTurbo1CompressorIntakePress : 0|16@1+ (0.0078124659559567,-250) [-250|251.99] "kPa" Vector__XXX

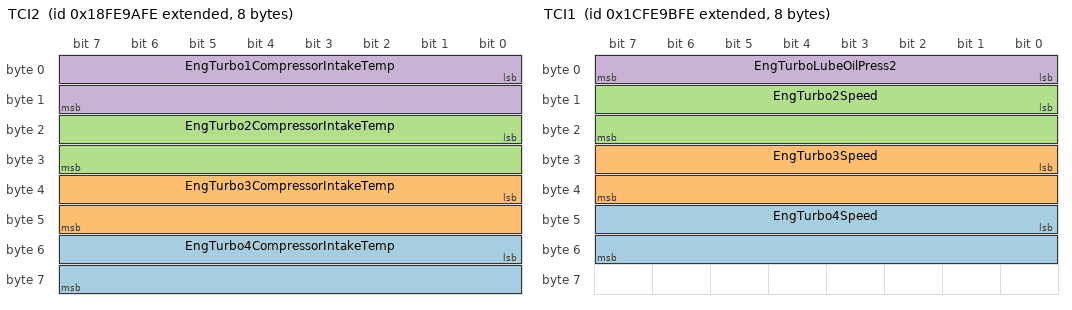
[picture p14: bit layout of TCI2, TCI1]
BO_ 2566822654 TCI2: 8 Vector__XXX
 SG_ EngTurbo4CompressorIntakeTemp : 48|16@1+ (0.03125,-273) [-273|1734.96875] "deg C" Vector__XXX
 SG_ EngTurbo3CompressorIntakeTemp : 32|16@1+ (0.03125,-273) [-273|1734.96875] "deg C" Vector__XXX
 SG_ EngTurbo2CompressorIntakeTemp : 16|16@1+ (0.03125,-273) [-273|1734.96875] "deg C" Vector__XXX
 SG_ EngTurbo1CompressorIntakeTemp : 0|16@1+ (0.03125,-273) [-273|1734.96875] "deg C" Vector__XXX

BO_ 2633931774 TCI1: 8 Vector__XXX
 SG_ EngTurbo4Speed : 40|16@1+ (4,0) [0|257020] "rpm" Vector__XXX
 SG_ EngTurbo3Speed : 24|16@1+ (4,0) [0|257020] "rpm" Vector__XXX
 SG_ EngTurbo2Speed : 8|16@1+ (4,0) [0|257020] "rpm" Vector__XXX
 SG_ EngTurboLubeOilPress2 : 0|8@1+ (4,0) [0|1000] "kPa" Vector__XXX

BO_ 2566802430 TCFG2: 8 Vector__XXX
 SG_ TransTorqueLimit : 0|16@1+ (1,0) [0|64255] "Nm" Vector__XXX

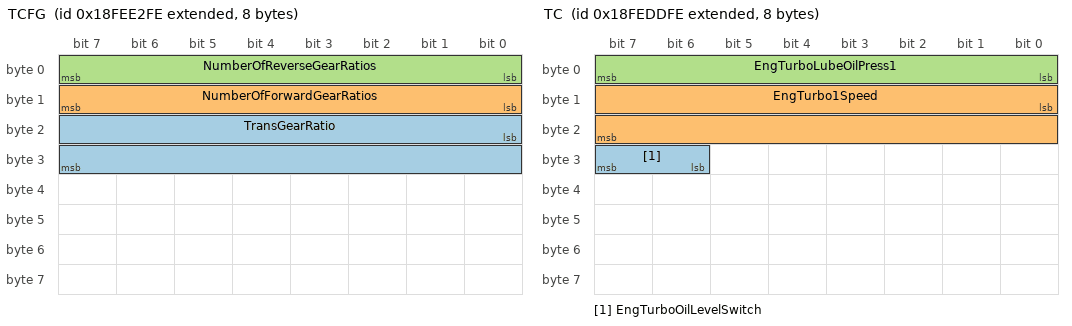
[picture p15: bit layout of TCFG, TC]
BO_ 2566841086 TCFG: 8 Vector__XXX
 SG_ TransGearRatio : 16|16@1+ (0.001,0) [0|64.255] "" Vector__XXX
 SG_ NumberOfForwardGearRatios : 8|8@1+ (1,0) [0|250] "" Vector__XXX
 SG_ NumberOfReverseGearRatios : 0|8@1+ (1,0) [0|250] "" Vector__XXX

BO_ 2348941054 TC1: 8 Vector__XXX
 SG_ TransMode8 : 62|2@1+ (1,0) [0|3] "" Vector__XXX
 SG_ TransMode7 : 60|2@1+ (1,0) [0|3] "" Vector__XXX
 SG_ TransMode6 : 58|2@1+ (1,0) [0|3] "" Vector__XXX
 SG_ TransMode5 : 56|2@1+ (1,0) [0|3] "" Vector__XXX
 SG_ TrnsShftSlectorDisplayModeSwitch : 54|2@1+ (1,0) [0|3] "" Vector__XXX
 SG_ TransRequestedLaunchGear : 50|4@1+ (1,0) [0|15] "" Vector__XXX
 SG_ TransMode4 : 46|2@1+ (1,0) [0|3] "" Vector__XXX
 SG_ TransMode3 : 44|2@1+ (1,0) [0|3] "" Vector__XXX
 SG_ TransMode2 : 42|2@1+ (1,0) [0|3] "" Vector__XXX
 SG_ TransMode1 : 40|2@1+ (1,0) [0|3] "" Vector__XXX
 SG_ DisengageDiffLockRqCentralRear : 36|2@1+ (1,0) [0|3] "" Vector__XXX
 SG_ DisengageDiffLockRqCentralFront : 34|2@1+ (1,0) [0|3] "" Vector__XXX
 SG_ DisengageDiffLockRqCentral : 32|2@1+ (1,0) [0|3] "" Vector__XXX
 SG_ DisengageDiffLockRqRearAxle2 : 30|2@1+ (1,0) [0|3] "" Vector__XXX
 SG_ DisengageDiffLockRqRearAxle1 : 28|2@1+ (1,0) [0|3] "" Vector__XXX
 SG_ DisengageDiffLockRqFrontAxle2 : 26|2@1+ (1,0) [0|3] "" Vector__XXX
 SG_ DisengageDiffLockRqFrontAxle1 : 24|2@1+ (1,0) [0|3] "" Vector__XXX
 SG_ TransRequestedGear : 16|8@1+ (1,-125) [-125|125] "" Vector__XXX
 SG_ RequestedPercentClutchSlip : 8|8@1+ (1,0) [0|100] "%" Vector__XXX
 SG_ TransReverseGearShiftInhibitRq : 6|2@1+ (1,0) [0|3] "" Vector__XXX
 SG_ DisengageDrivelineRq : 4|2@1+ (1,0) [0|3] "" Vector__XXX
 SG_ TrnsTrqeConverterLockupDisableRq : 2|2@1+ (1,0) [0|3] "" Vector__XXX
 SG_ TransGearShiftInhibitRq : 0|2@1+ (1,0) [0|3] "" Vector__XXX

BO_ 2566839806 TC: 8 Vector__XXX
 SG_ EngTurboOilLevelSwitch : 30|2@1+ (1,0) [0|3] "" Vector__XXX
 SG_ EngTurbo1Speed : 8|16@1+ (4,0) [0|257020] "rpm" Vector__XXX
 SG_ EngTurboLubeOilPress1 : 0|8@1+ (4,0) [0|1000] "kPa" Vector__XXX

BO_ 2633911806 TAVG: 8 Vector__XXX
 SG_ EngTotalAverageFuelEconomy : 16|16@1+ (0.0019531553964672,0) [0|125.5] "km/L" Vector__XXX
 SG_ EngTotalAverageFuelRate : 0|16@1+ (0.05,0) [0|3212.75] "L/h" Vector__XXX

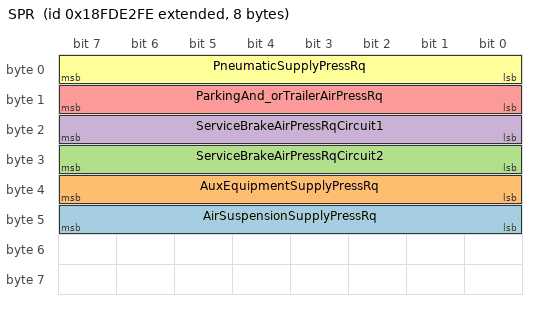
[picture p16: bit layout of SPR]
BO_ 2566775550 SPR: 8 Vector__XXX
 SG_ AirSuspensionSupplyPressRq : 40|8@1+ (1,0) [0|2000] "kPa" Vector__XXX
 SG_ AuxEquipmentSupplyPressRq : 32|8@1+ (1,0) [0|2000] "kPa" Vector__XXX
 SG_ ServiceBrakeAirPressRqCircuit2 : 24|8@1+ (1,0) [0|2000] "kPa" Vector__XXX
 SG_ ServiceBrakeAirPressRqCircuit1 : 16|8@1+ (1,0) [0|2000] "kPa" Vector__XXX
 SG_ ParkingAnd_orTrailerAirPressRq : 8|8@1+ (1,0) [0|2000] "kPa" Vector__XXX
 SG_ PneumaticSupplyPressRq : 0|8@1+ (1,0) [0|2000] "kPa" Vector__XXX

BO_ 2566819838 SP2: 8 Vector__XXX
 SG_ EngExtlShutdownAirSupplyPress : 0|16@1+ (0.5,0) [0|32127.5] "kPa" Vector__XXX

BO_ 2566839038 SOFT: 8 Vector__XXX
 SG_ NmbrOfSftwreIdentificationFields : 0|8@1+ (1,0) [0|250] "steps" Vector__XXX
 SG_ SoftwareIdentification : 8|8@1+ (1.02,0) [0|255] "per byte" Vector__XXX

BO_ 2566841598 SHUTDN: 8 Vector__XXX
 SG_ PTOShutdownHasShutdownEng : 58|2@1+ (1,0) [0|3] "" Vector__XXX
 SG_ EngAirShutoffStatus : 56|2@1+ (1,0) [0|3] "" Vector__XXX
 SG_ EngOverspeedTest : 54|2@1+ (1,0) [0|3] "" Vector__XXX
 SG_ EngAirShutoffCmdStatus : 52|2@1+ (1,0) [0|3] "" Vector__XXX
 SG_ EngAlarmOutputCmdStatus : 50|2@1+ (1,0) [0|3] "" Vector__XXX
 SG_ EngAlarmAcknowledge : 48|2@1+ (1,0) [0|3] "" Vector__XXX
 SG_ EngProtectionSystemConfig : 46|2@1+ (1,0) [0|3] "" Vector__XXX
 SG_ EngProtectionSystemTimerState : 38|2@1+ (1,0) [0|3] "" Vector__XXX
 SG_ EngProtectionSystemTimerOverride : 36|2@1+ (1,0) [0|3] "" Vector__XXX
 SG_ EngPrtctnSystmApprachingShutdown : 34|2@1+ (1,0) [0|3] "" Vector__XXX
 SG_ EngPrtectionSystemHasShutdownEng : 32|2@1+ (1,0) [0|3] "" Vector__XXX
 SG_ EngWaitToStartLamp : 24|2@1+ (1,0) [0|3] "" Vector__XXX
 SG_ RefrigerantHighPressSwitch : 20|2@1+ (1,0) [0|3] "" Vector__XXX
 SG_ RefrigerantLowPressSwitch : 18|2@1+ (1,0) [0|3] "" Vector__XXX
 SG_ A_CHighPressFanSwitch : 16|2@1+ (1,0) [0|3] "" Vector__XXX
 SG_ EngIdleShutdownTimerFunction : 14|2@1+ (1,0) [0|3] "" Vector__XXX
 SG_ EngIdleShutdownTimerState : 6|2@1+ (1,0) [0|3] "" Vector__XXX
 SG_ EngIdleShutdownTimerOverride : 4|2@1+ (1,0) [0|3] "" Vector__XXX
 SG_ EngIdleShutdownDriverAlertMode : 2|2@1+ (1,0) [0|3] "" Vector__XXX
 SG_ EngIdleShutdownHasShutdownEng : 0|2@1+ (1,0) [0|3] "" Vector__XXX

CM_ BO_ 2565734142 "Used to access network interconnection ECU parametrics and database";
CM_ SG_ 2565734142 FilterMode "Filter mode for Network PG";
CM_ SG_ 2565734142 ToPort "Destination port for network PG";
CM_ SG_ 2565734142 FromPort "Source port for Network PG";
CM_ BO_ 2565144318 "ISO 11992: Towing vehicle message, running gear equipment #1/1

RGE11 replaces GFM 12 in ISO 11992:1998 part 3";
CM_ SG_ 2565144318 ParkingAndTrailerAirPress "The pneumatic pressure in the circuit or reservoir for the parking brake and the trailer supply.";
CM_ SG_ 2565144318 DrivenAxleLoad "Actual static vertical load on driven axle of the commercial vehicle. In case of more than one driven axle the value of the axle with the highest vertical load is transmitted.";
CM_ SG_ 2565144318 AuxEquipSupplyPressure "The pneumatic pressure in the auxiliary circuit.";
CM_ SG_ 2565144318 StopLevelChangeReq "Command signal to stop immediately any change of the actual body height level.";
CM_ SG_ 2565144318 RampLevelStorageReq "Command signal to store the actual body height level as new programmed and memorised ramp levels 1 or 2 in the ECU";
CM_ SG_ 2565144318 LevelControlReq "Command signal to enable or disable the automatic level control.";
CM_ SG_ 2565144318 RampLevelReq "Command signal to control the body height to a level programmed and memorised in the ECU.";
CM_ SG_ 2565144318 SteeringAxleLockingReq "Command signal to lock the steering axle.";
CM_ SG_ 2565144318 LiftAxle2PositionReq "Command signal to control the lift axle position / tag axle load condition.";
CM_ SG_ 2565144318 LiftAxle1PositionReq "Command signal to control the lift axle position / tag axle load condition.";
CM_ SG_ 2565144318 TractionHelpReq "Command signal to control the lift axle position / tag axle load condition to transfer more load on the driven axle of the commercial vehicle.";
CM_ SG_ 2565144318 LevelChangeReqRearAxle "Command signal to control the body height [up (lifting)/down (lowering)] for the rear axle.";
CM_ SG_ 2565144318 LevelChangeReqFrontAxle "Command signal to control the body height [up (lifting)/down (lowering)] for the front axle.";
CM_ SG_ 2565144318 RideHeightRequest "Command signal to activate a normal ride body height. The normal levels 1 and 2 are trailer specific body heights.";
CM_ BO_ 2565209854 "ISO 11992: Towed vehicle message, running gear equipment #2/1

RGE21 replaces GFM 22 in ISO 11992:1998 part 3";
CM_ SG_ 2565209854 LevelControl "Signal which indicates that the automatic level control is enabled or disabled.";
CM_ SG_ 2565209854 NominalVehBodyLevelRearAxle "Actual nominal vehicle body height.";
CM_ SG_ 2565209854 NominalVehBodyLevelFrontAxle "Actual nominal vehicle body height.";
CM_ SG_ 2565209854 RampLevel "Signal which indicates the level of the body height as an anser to 'ramp level request'.";
CM_ SG_ 2565209854 NormalLevel "Signal which indicates the normal levels of the vehicle independently of a specific request.";
CM_ SG_ 2565209854 StopLevelChangeAcknowledge "Signal which indicates the stop of any level change due to a 'stop request'.";
CM_ SG_ 2565209854 LevelChangeRearAxle "Signal which indicates the level change of the body height at the rear axle due to any external requests.";
CM_ SG_ 2565209854 LevelChangeFrontAxle "Signal which indicates the level change of the body height at the front axle due to any external requests.";
CM_ SG_ 2565209854 RampLevelStorage "Signal which indicates the storage of a new ramp level in the ECU.";
CM_ SG_ 2565209854 SteeringAxleLocking "Signal which indicates the actual steering axle locking status.";
CM_ SG_ 2565209854 LiftAxle2Pos "Signal which indicates the position / load condition of lift axle / tag axle #2. Numbering of lift/tag axles starts at front axle.";
CM_ SG_ 2565209854 LiftAxle1Pos "Signal which indicates the position / load condition of lift axle / tag axle #1. Numbering of lift/tag axles starts at front axle.";
CM_ SG_ 2565209854 RampLevelPosition "Signal which indicates the ramp level positions of the vehicle independently of a specific request.";
CM_ SG_ 2565209854 TractionHelp "Signal which indicates that a load transfer is active.";
CM_ SG_ 2565209854 LevelCtrlSysRideHeightLevel "Signal which indicates the body height position of the vehicle as an answer to 'ride height request'.";
CM_ BO_ 2566806782 "ISO 11992: Towed vehicle message, running gear equipment #2/2";
CM_ SG_ 2566806782 RelVehBodyLevelRearAxle "Actual relative vehicle body height.";
CM_ SG_ 2566806782 RelVehBodyLevelFrontAxle "Actual relative vehicle body height.";
CM_ BO_ 2566807294 "ISO 11992: Towed vehicle message, running gear equipment #2/3";
CM_ SG_ 2566807294 TyrePressThresholdDetect "Signal indicating the pressure level of the tyre.";
CM_ SG_ 2566807294 TyreModulePowerSupply "Signal indicating the power supply of the tyre module is sufficient to achieve the specified performance of the module.";
CM_ SG_ 2566807294 TyreTemperature "The temperature measured by the tyre module.";
CM_ SG_ 2566807294 AirLeakageDetection "The pressure loss of a tyre.";
CM_ SG_ 2566807294 TyreWheelIdentification2 "First part of the identification number of the tyre or whee (number of axles).";
CM_ SG_ 2566807294 TyreWheelIdentification1 "First part of the identification number of the tyre or whee (position on each axle).";
CM_ BO_ 2566764798 "Diagnostic readiness 3";
CM_ BO_ 2564095742 "Data security";
CM_ BO_ 2349137662 "Used for brake control by an external device. The receiver is the brake system controlling the axle and/or wheel brakes.";
CM_ SG_ 2349137662 XBRMessageChecksum "The XBR message checksum is used to verify the signal path from the demanding device to the brake controller on";
CM_ SG_ 2349137662 XBRMessageCounter "The XBR message counter is to verify the signal path from the demanding device to the brake controller on electronic";
CM_ SG_ 2349137662 XBRUrgency "The idea of the urgency value is to adjust the endurance brake integration behavior in the EBS system according to the";
CM_ SG_ 2349137662 XBRCtrlMode "The XBR Control Mode is used as an input to the brake system and defines how the external acceleration demand has to";
CM_ SG_ 2349137662 XBRPriority "The XBR Priority is used as an input to the brake system to manage the priority of overlapping external and internal";
CM_ SG_ 2349137662 XBREBIMode "The XBR EBI (Endurance Brake Integration) Mode is used as an input for the brake system to prescribe the use of";
CM_ SG_ 2349137662 ExtlAccelerationDemand "Parameter provided to the brake system from external sources. This is the acceleration which the brake system is";
CM_ BO_ 2566848510 "Water in Fuel Indicator";
CM_ SG_ 2566848510 WaterInFuelIndicator "Signal which indicates the presence of water in the fuel.";
CM_ BO_ 2566843134 "Vehicle Weight";
CM_ SG_ 2566843134 AxleLocation "To identify to which of several similar devices (such as tires or fuel tanks) the information applies.";
CM_ SG_ 2566843134 CargoWeight_30 "The mass of freight carried.";
CM_ SG_ 2566843134 CargoWeight_20 "The mass of freight carried.";
CM_ SG_ 2566843134 CargoWeight_10 "The mass of freight carried.";
CM_ SG_ 2566843134 CargoWeight_00 "The mass of freight carried.";
CM_ SG_ 2566843134 TrailerWeight_30 "Total mass of freight-carrying vehicle designed to be pulled by truck, including the weight of the contents.";
CM_ SG_ 2566843134 TrailerWeight_20 "Total mass of freight-carrying vehicle designed to be pulled by truck, including the weight of the contents.";
CM_ SG_ 2566843134 TrailerWeight_10 "Total mass of freight-carrying vehicle designed to be pulled by truck, including the weight of the contents.";
CM_ SG_ 2566843134 TrailerWeight_00 "Total mass of freight-carrying vehicle designed to be pulled by truck, including the weight of the contents.";
CM_ SG_ 2566843134 AxleWeight_30 "Total mass imposed by the tires on the road surface at the specified axle.";
CM_ SG_ 2566843134 AxleWeight_20 "Total mass imposed by the tires on the road surface at the specified axle.";
CM_ SG_ 2566843134 AxleWeight_10 "Total mass imposed by the tires on the road surface at the specified axle.";
CM_ SG_ 2566843134 AxleWeight_00 "Total mass imposed by the tires on the road surface at the specified axle.";
CM_ BO_ 2566804222 "This contains high resolution/range parameters reported from the alternator or power generation components.";
CM_ SG_ 2566804222 NetBatteryCurrent "Net flow of electrical current into/out-of the battery or batteries. This parameter is the high range and resolution of SPN";
CM_ SG_ 2566804222 AltCurrent "This parameter indicates the amount of electrical current output from the alternator of the main vehicle. Alternator Current";
CM_ BO_ 2566819326 "Voltage data for the main vehicle Power Distribution system.";
CM_ SG_ 2566819326 ECUPowerOutputSupplyVoltage3 "The third power output from an ECM.";
CM_ SG_ 2566819326 ECUPowerOutputSupplyVoltage2 "The second power output from an ECM.";
CM_ SG_ 2566819326 ECUPowerOutputSupplyVoltage1 "The first power output from an ECM";
CM_ SG_ 2566819326 BatteryPotential_PowerInput2 "This parameter measures the second source of battery potential as measured at the input of the ECM/actuator etc.";
CM_ BO_ 2566843646 "Vehicle Identification";
CM_ SG_ 2566843646 VehicleIdentificationNumber "Vehicle Identification Number (VIN) as assigned by the vehicle manufacturer.";
CM_ SG_ 2566842366 TotalPowerTakeoffHours "Accumulated time of operation of power takeoff device.";
CM_ SG_ 2566842366 TotalVehicleHours "Accumulated time of operation of vehicle.";
CM_ BO_ 2566809854 "Tr";
CM_ SG_ 2566809854 HydOilLevel "This parameter indicates the level of the hydraulic fluid in tank as a ratio of current volume to total tank volume. This";
CM_ SG_ 2566809854 WinchOilPressSwitch "State of switch used to determine if Winch Oil Pressure is above desired minimum";
CM_ SG_ 2566809854 HydOilFilterRestrictionSwitch "This switch indicates whether hydraulic oil filter is clogged. This is not the transmission oil filter restriction switch, which is";
CM_ SG_ 2566809854 HydTemp "Temperature of hydraulic fluid.";
CM_ SG_ 2566842622 Altitude "Altitude of the vehicle referenced to sea level at standard atmospheric pressure and temperature.";
CM_ SG_ 2566842622 Pitch "Pitch of the vehicle as calculated by the navigation device(s).";
CM_ SG_ 2566842622 NavigationBasedVehicleSpeed "Speed of the vehicle as calculated from a device such as a Global Positioning System (GPS).";
CM_ SG_ 2566842622 CompassBearing "Present compass bearing of vehicle.";
CM_ BO_ 2566832638 "High Resolution Vehicle Distance";
CM_ SG_ 2566832638 HighResolutionTripDistance "Distance traveled during all or part of a journey.";
CM_ SG_ 2566832638 HghRsolutionTotalVehicleDistance "Accumulated distance traveled by the vehicle during its operation.";
CM_ BO_ 2565868030 "Contains information which relates to the vehicle's movement.";
CM_ SG_ 2565868030 LongitudinalAcceleration "Indicates the longitudinal acceleration of the vehicle. A positive longitudinal acceleration signal results when the vehicle";
CM_ SG_ 2565868030 LateralAcceleration "Indicates a lateral acceleration of the vehicle. A positive lateral acceleration signal results when the vehicle is accelerated";
CM_ SG_ 2565868030 YawRate "Indicates the rotation about the vertical axis. A positive yaw rate signal results when the vehicle turns counter-clockwise.";
CM_ SG_ 2565868030 SteerWheelAngleSensorType "Indicates whether the steering wheel angle sensor is capable of absolute measuring of the number of steering wheel";
CM_ SG_ 2565868030 SteerWheelTurnCounter "Indicates number of steering wheel turns, absolute position or relative position at ignition on. Positive values indicate left";
CM_ SG_ 2565868030 SteerWheelAngle "The main operator`s steering wheel angle (on the steering column, not the actual wheel angle). The vehicle being steered";
CM_ BO_ 2566803454 "Contains information which relates to the VDC system status.";
CM_ SG_ 2566803454 YCBrakeCtrlActive "State signal which indicates that Yaw Control (YC) has activated brake control. Active means that YC actually controls";
CM_ SG_ 2566803454 YCEngCtrlActive "State Signal which indicates that the Yaw Control (YC) has commanded engine control to be active. Within the physical";
CM_ SG_ 2566803454 ROPBrakeCtrlActive "State signal which indicates that Roll over Prevention (ROP) has activated brake control. Active means that ROP actually";
CM_ SG_ 2566803454 ROPEngCtrlActive "State Signal which indicates that the Roll Over Prevention (ROP) has commanded engine control to be active. Within the";
CM_ SG_ 2566803454 VDCBrakeLightRq "Indicates whether VDC requests to turn the vehicle brake lights on";
CM_ SG_ 2566803454 VDCFullyOperational "Signal that indicates whether VDC is fully operational or whether its functionality is reduced by a permanent or temporary";
CM_ SG_ 2566803454 VDCInformationSignal "This parameter commands the VDC information signal, for example a dash lamp.";
CM_ SG_ 2566840574 TotalVehicleDistance "Accumulated distance traveled by vehicle during its operation.";
CM_ SG_ 2566840574 TripDistance "Distance traveled during all or part of a journey.";
CM_ SG_ 2633938686 TripCruiseDistance "Total distance that the engine has operated in the cruise hold state, excluding time in accelerator override, since the last";
CM_ SG_ 2633938686 TripMaxVehicleSpeed "Maximum vehicle speed achieved while the engine speed is greater than zero and the accelerator pedal position (APS) is";
CM_ SG_ 2633937150 TripAirCompressorOnTime "Total time that the air compressor is on and compressing air since the last trip reset.";
CM_ SG_ 2633937150 TripIdleTime "Total time accumulated while the engine speed is greater than zero, both the PTO and remote PTO governors are";
CM_ SG_ 2633937150 TripEngRunningTime "Total time accumulated while the engine speed is greater than zero since the last trip reset. Note that time with the";
CM_ SG_ 2633937150 TripCruiseTime "Total time accumulated while the engine is in the cruise hold state, excluding time in accelerator override, since the last";
CM_ SG_ 2633937150 TripPTOGovernorTime "Total time accumulated while the engine is in the PTO or remote PTO governor hold state since the last trip reset.";
CM_ SG_ 2633938174 TripTimeInDerateByEng "Total time accumulated when the engine final fueling has been derated due to an engine protection algorithm, since the";
CM_ SG_ 2633938174 TripTimeInGearDown "Total time accumulated when the vehicle has operated in one gear down from the top gear for a calibrated minimum time,";
CM_ SG_ 2633938174 TripTimeInTopGear "Total time accumulated when the vehicle has operated in top gear for a calibrated minimum time, since the last trip reset.";
CM_ SG_ 2633938174 TripTimeInVSL "Total time accumulated when the engine has operated on the vehicle speed limiter (VSL) while not in the cruise hold";
CM_ SG_ 2633938430 TripSuddenDecelerations "Total number of decelerations whenever the vehicle deceleration is more than XYZ km/h/sec (where XYZ is a calibratible";
CM_ SG_ 2633938430 TrpNumberOfIdleShutdownOverrides "Total number of times an operator disables idle shutdown to prevent an engine shutdown, since the last trip reset.";
CM_ SG_ 2633938430 TripNumberOfIdleShutdowns "Total number of times the engine has been shutdown due to idling too long (at normal idle or fast idle) since the last trip";
CM_ SG_ 2633938430 TripNumberOfHotShutdowns "Total number of hot shutdowns since the last trip reset. A hot shutdown is based on operation at high load or high engine";
CM_ BO_ 2348875518 "NOTE - Retarder may be disabled by commanding a torque limit of 0%. Use of the limit mode allows the use of the";
CM_ SG_ 2348875518 MessageChecksum "The message checksum is used to verify the signal path from the transmitting device to the receiving device.";
CM_ SG_ 2348875518 MessageCounter "The message counter is used to detect situations where the transmitting ECU malfunction repeats the same frame all the";
CM_ SG_ 2348875518 EngRequestedTorqueHighResolution "This parameter displays an additional torque in percent of the reference engine torque.";
CM_ SG_ 2348875518 TSC1CtrlPurpose "State signal which indicates which control mode the sending device is using to generate the TSC1 command. Note that";
CM_ SG_ 2348875518 TSC1TransRate "This parameter indicates the transmission rate at which the sending device will transmit the TSC1 message. The engine";
CM_ SG_ 2348875518 EngRequestedTorque_TorqueLimit "Parameter provided to the engine or retarder in the torque/speed control message for controlling or limiting the output";
CM_ SG_ 2348875518 EngRequestedSpeed_SpeedLimit "Parameter provided to the engine from external sources in the torque/speed control message. This is the engine speed";
CM_ SG_ 2348875518 OverrideCtrlModePriority "This field is used as an input to the engine or retarder to determine the priority of the Override Control Mode received in";
CM_ SG_ 2348875518 EngRequestedSpeedCtrlConditions "This mode tells the engine control system the governor characteristics that are desired during speed control. The four";
CM_ SG_ 2348875518 EngOverrideCtrlMode "The override control mode defines which sort of command is used:";
CM_ BO_ 2566766846 "Used to notify the transit link devices of real-time boarding and exiting passengers or to indicate the total number of";
CM_ SG_ 2566766846 TransitRunStatus "Status of the run switch for the vehicle.";
CM_ SG_ 2566766846 VehicleUseStatus "Used to indicate the proper or unauthorized use of the vehicle. The administrative control device or any device issuing the";
CM_ SG_ 2566766846 SilentAlarmStatus "Used to report silent alarm push button status.";
CM_ SG_ 2566766846 PatronCount "Count of the number of passengers on a transit vehicle. If the type of passenger count (SPN 3043) is 0, the patron count";
CM_ SG_ 2566766846 TypeOfPassengerCount "Used to notify transit link devices of the type of passenger counting system used in the vehicle. Some passenger";
CM_ BO_ 2566765310 "Used to report alarms of the fare collection unit.";
CM_ SG_ 2566765310 FareboxAlarmIdentifier "Indicates the nature of the farebox alarm condition.";
CM_ SG_ 2566765310 FareboxEmergencyStatus "Indicates if a farebox emergency condition exists.";
CM_ BO_ 2566765566 "Used to report stop level point of sale detail.";
CM_ SG_ 2566765566 TransferSold "Indicates that a transfer was sold or issued on this transaction including its type and/or restrictions. The final definitions of";
CM_ SG_ 2566765566 RouteNumber "The route number issuing the transfer.";
CM_ SG_ 2566765566 TransferType "The kind of transfer used";
CM_ SG_ 2566765566 TypeOfService "The type of service provided";
CM_ SG_ 2566765566 InitialFareAgency "Identifies where the initial fare is paid";
CM_ SG_ 2566765566 PassCategory "Agency defined value indicating the category of the passenger associated with this fare";
CM_ SG_ 2566765566 FareValidity "Agency defined value indicating validity of this fare";
CM_ SG_ 2566765566 PaymentDetails "Payment details.";
CM_ SG_ 2566765566 TypeOfFare "Type of Fare";
CM_ SG_ 2566765566 PassengerType "Enumerated value representing the type/class of passenger, as defined by the agency.";
CM_ SG_ 2566765566 TransactionType "Enumerated value representing the type of transaction completed";
CM_ BO_ 2566765822 "Used to identify service, assignments, and fare preset detail of the fare collection unit.";
CM_ SG_ 2566765822 DriversFareboxSecurityCode "Security code for the farebox, numerical only.";
CM_ SG_ 2566765822 AssignedBlock "The agency defined block number for this trip";
CM_ SG_ 2566765822 AssignedRun "The agency defined run number for this trip";
CM_ SG_ 2566765822 AssignedRoute "The identity number assigned to this route.";
CM_ SG_ 2566765822 PatternNumber "The agency defined pattern number for this trip";
CM_ SG_ 2566765822 TripNumber "The identity number assigned to this trip.";
CM_ SG_ 2566765822 FarePresets "Fare Presets";
CM_ SG_ 2566765822 TripDirection "The general direction of travel for this trip.";
CM_ SG_ 2566765822 TripStatus "Trip Status";
CM_ SG_ 2566765822 FareboxServiceStatus "Indicates if the farebox is in or out of service.";
CM_ BO_ 2566766078 "Status and configuration of the device used for intersection preemption.";
CM_ SG_ 2566766078 VehicleID "Numerical designation of the vehicle. 65535 is used to represent the vehicle ID is not available.";
CM_ SG_ 2566766078 StrobeActivationCtrlStatus "Strobe activation control status";
CM_ SG_ 2566766078 TransitDoorEnable "Transit door enable";
CM_ SG_ 2566766078 PriorityOfRespSentByEmitter "Priority of response sent by emitter";
CM_ SG_ 2566766078 IntrsctnPrmptionRequest_Response "Status of the intersection signal preemption";
CM_ SG_ 2566766078 TransitRouteIDUsage "Transit route ID usage";
CM_ SG_ 2566766078 RangeCodeEnable "Range code enable";
CM_ BO_ 2566766590 "Identification of a transit route milepost";
CM_ SG_ 2566766590 NmbrOfBytsInThMlpstIdntification "Number of bytes in the Milepost Identification. This parameter identifies the length, in bytes, of the data in SPN 590";
CM_ BO_ 2566766334 "The current route assigned to this transit vehicle. The transit route information may be entered into different devices by";
CM_ SG_ 2566766334 NmbrOfBytsInThTrnstAssgndBlckIdn "Number of bytes in the Transit Assigned Block Identity. This parameter identifies the length, in bytes, of the data in SPN";
CM_ SG_ 2566766334 NmbrOfBytsInThTrnstAssgndRnIdntt "Number of bytes in the Transit Assigned Run Identity. This parameter identifies the length, in bytes, of the data in SPN";
CM_ SG_ 2566766334 NmbrOfBytsInThTrnstAssgndRtIdntt "Number of bytes in the Transit Assigned Route Identity. This parameter identifies the length, in bytes, of the data in SPN";
CM_ SG_ 2566766334 Agency "The identity of the agency involved in this transaction";
CM_ BO_ 2561605374 "Tire Pressure Reference Setting";
CM_ SG_ 2561605374 TireLocation "Identifies which tire is associated with the parametric data in this PGN.";
CM_ BO_ 2566765054 "Tire Pressure Reference Information";
CM_ SG_ 2566765054 TireLocation "Identifies which tire is associated with the parametric data in this PGN.";
CM_ SG_ 2633923326 SteerChannelTirePress "The latest gage pressure reading of the steer group of tires, as opposed to the pressure in each tire.";
CM_ SG_ 2633923326 DriveChannelTirePress "The latest gage pressure reading of the drive group of tires, as opposed to the pressure in each tire.";
CM_ SG_ 2633923326 TrailerTagOrPushChannelTirePress "The latest gage pressure reading of the trailer, tag, or push group of tires, as opposed to the pressure in each tire.";
CM_ SG_ 2633923070 SteerChannelTirePressTarget "The tire pressure control system’s target gage pressure for the steer group of tires.";
CM_ SG_ 2633923070 DriveChannelTirePressTarget "The tire pressure control system’s target gage pressure for the drive group of tires.";
CM_ SG_ 2633923070 TrlrTgOrPshChnnelTirePressTarget "The tire pressure control system’s target gage pressure for the trailer, tag, or push group of tires.";
CM_ SG_ 2633922814 PCUTrilerTagOrPushSolenoidStatus "Current state of the trailer, tag, or push solenoid used to implement a tire pressure control system in its pneumatic control";
CM_ SG_ 2633922814 PCUSupplySolenoidStatus "Current state of the supply solenoid used to implement a tire pressure control system in its pneumatic control unit (PCU).";
CM_ SG_ 2633922814 PCUCtrlSolenoidStatus "Current state of the control solenoid used to implement a tire pressure control system in its pneumatic control unit (PCU).";
CM_ SG_ 2633922814 PCUDeflateSolenoidStatus "Current state of the deflate solenoid used to implement a tire pressure control system in its pneumatic control unit (PCU).";
CM_ SG_ 2633922814 TirePressSupplySwitchStatus "Current state of an open/closed type switch used to determine if adequate pressure exists for system implementation.";
CM_ SG_ 2633922814 PCUSteerSolenoidStatus "Current state of the steer solenoid used to implement a tire pressure control system in its pneumatic control unit (PCU).";
CM_ SG_ 2633922814 PCUDriveSolenoidStatus "Current state of the drive solenoid used to implement a tire pressure control system in its pneumatic control unit (PCU).";
CM_ SG_ 2633922814 DriveChannelMode "Indicates the functional mode of trailer/tag channel of the tire pressure control system.";
CM_ SG_ 2633922814 Trailer_tagChannelMode "Indicates the functional mode of trailer/tag channel of the tire pressure control system.";
CM_ SG_ 2633922814 SteerChannelMode "Indicates the functional mode of steer channel of the tire pressure control system.";
CM_ SG_ 2633922814 TirePressCheckInterval "The interval at which the system will check the tire pressures (e.g., 5, 10, 15 min.).";
CM_ BO_ 2566845694 "Tire Condition";
CM_ SG_ 2566845694 TirePressThresholdDetection_13 "Signal indicating the pressure level of the tire.";
CM_ SG_ 2566845694 TirePressThresholdDetection_12 "Signal indicating the pressure level of the tire.";
CM_ SG_ 2566845694 TirePressThresholdDetection_11 "Signal indicating the pressure level of the tire.";
CM_ SG_ 2566845694 TirePressThresholdDetection_10 "Signal indicating the pressure level of the tire.";
CM_ SG_ 2566845694 TirePressThresholdDetection_01 "Signal indicating the pressure level of the tire.";
CM_ SG_ 2566845694 TirePress_33 "Pressure at which air is contained in cavity formed by tire and rim.";
CM_ SG_ 2566845694 TirePress_32 "Pressure at which air is contained in cavity formed by tire and rim.";
CM_ SG_ 2566845694 TirePress_31 "Pressure at which air is contained in cavity formed by tire and rim.";
CM_ SG_ 2566845694 TirePress_30 "Pressure at which air is contained in cavity formed by tire and rim.";
CM_ SG_ 2566845694 TirePress_23 "Pressure at which air is contained in cavity formed by tire and rim.";
CM_ SG_ 2566845694 TirePress_22 "Pressure at which air is contained in cavity formed by tire and rim.";
CM_ SG_ 2566845694 TirePress_21 "Pressure at which air is contained in cavity formed by tire and rim.";
CM_ SG_ 2566845694 TirePress_20 "Pressure at which air is contained in cavity formed by tire and rim.";
CM_ SG_ 2566845694 TirePress_13 "Pressure at which air is contained in cavity formed by tire and rim.";
CM_ SG_ 2566845694 TirePress_12 "Pressure at which air is contained in cavity formed by tire and rim.";
CM_ SG_ 2566845694 TirePress_11 "Pressure at which air is contained in cavity formed by tire and rim.";
CM_ SG_ 2566845694 TirePress_10 "Pressure at which air is contained in cavity formed by tire and rim.";
CM_ SG_ 2566845694 TireAirLeakageRate_33 "The pressure loss rate of a tire.";
CM_ SG_ 2566845694 TireAirLeakageRate_32 "The pressure loss rate of a tire.";
CM_ SG_ 2566845694 TireAirLeakageRate_31 "The pressure loss rate of a tire.";
CM_ SG_ 2566845694 TireAirLeakageRate_30 "The pressure loss rate of a tire.";
CM_ SG_ 2566845694 TireAirLeakageRate_23 "The pressure loss rate of a tire.";
CM_ SG_ 2566845694 TireAirLeakageRate_22 "The pressure loss rate of a tire.";
CM_ SG_ 2566845694 TireAirLeakageRate_21 "The pressure loss rate of a tire.";
CM_ SG_ 2566845694 TireAirLeakageRate_20 "The pressure loss rate of a tire.";
CM_ SG_ 2566845694 TireAirLeakageRate_13 "The pressure loss rate of a tire.";
CM_ SG_ 2566845694 TireAirLeakageRate_12 "The pressure loss rate of a tire.";
CM_ SG_ 2566845694 TireAirLeakageRate_11 "The pressure loss rate of a tire.";
CM_ SG_ 2566845694 TireAirLeakageRate_10 "The pressure loss rate of a tire.";
CM_ SG_ 2566845694 TireAirLeakageRate_01 "The pressure loss rate of a tire.";
CM_ SG_ 2566845694 TireAirLeakageRate_00 "The pressure loss rate of a tire.";
CM_ SG_ 2566845694 CTIWheelSensorStatus_33 "Indicates whether the wheel is being monitored by the CTI controller.";
CM_ SG_ 2566845694 CTIWheelSensorStatus_32 "Indicates whether the wheel is being monitored by the CTI controller.";
CM_ SG_ 2566845694 CTIWheelSensorStatus_31 "Indicates whether the wheel is being monitored by the CTI controller.";
CM_ SG_ 2566845694 CTIWheelSensorStatus_30 "Indicates whether the wheel is being monitored by the CTI controller.";
CM_ SG_ 2566845694 CTIWheelSensorStatus_23 "Indicates whether the wheel is being monitored by the CTI controller.";
CM_ SG_ 2566845694 CTIWheelSensorStatus_22 "Indicates whether the wheel is being monitored by the CTI controller.";
CM_ SG_ 2566845694 CTIWheelSensorStatus_21 "Indicates whether the wheel is being monitored by the CTI controller.";
CM_ SG_ 2566845694 CTIWheelSensorStatus_20 "Indicates whether the wheel is being monitored by the CTI controller.";
CM_ SG_ 2566845694 CTIWheelSensorStatus_13 "Indicates whether the wheel is being monitored by the CTI controller.";
CM_ SG_ 2566845694 CTIWheelSensorStatus_12 "Indicates whether the wheel is being monitored by the CTI controller.";
CM_ SG_ 2566845694 CTIWheelSensorStatus_11 "Indicates whether the wheel is being monitored by the CTI controller.";
CM_ SG_ 2566845694 CTIWheelSensorStatus_10 "Indicates whether the wheel is being monitored by the CTI controller.";
CM_ SG_ 2566845694 CTIWheelSensorStatus_01 "Indicates whether the wheel is being monitored by the CTI controller.";
CM_ SG_ 2566845694 CTIWheelEndElectricalFault_33 "Indicates the status of electrical fault on CTI wheel interface.";
CM_ SG_ 2566845694 CTIWheelEndElectricalFault_32 "Indicates the status of electrical fault on CTI wheel interface.";
CM_ SG_ 2566845694 CTIWheelEndElectricalFault_31 "Indicates the status of electrical fault on CTI wheel interface.";
CM_ SG_ 2566845694 CTIWheelEndElectricalFault_30 "Indicates the status of electrical fault on CTI wheel interface.";
CM_ SG_ 2566845694 CTIWheelEndElectricalFault_23 "Indicates the status of electrical fault on CTI wheel interface.";
CM_ SG_ 2566845694 CTIWheelEndElectricalFault_22 "Indicates the status of electrical fault on CTI wheel interface.";
CM_ SG_ 2566845694 CTIWheelEndElectricalFault_21 "Indicates the status of electrical fault on CTI wheel interface.";
CM_ SG_ 2566845694 CTIWheelEndElectricalFault_20 "Indicates the status of electrical fault on CTI wheel interface.";
CM_ SG_ 2566845694 CTIWheelEndElectricalFault_13 "Indicates the status of electrical fault on CTI wheel interface.";
CM_ SG_ 2566845694 CTIWheelEndElectricalFault_12 "Indicates the status of electrical fault on CTI wheel interface.";
CM_ SG_ 2566845694 CTIWheelEndElectricalFault_11 "Indicates the status of electrical fault on CTI wheel interface.";
CM_ SG_ 2566845694 CTIWheelEndElectricalFault_10 "Indicates the status of electrical fault on CTI wheel interface.";
CM_ SG_ 2566845694 CTIWheelEndElectricalFault_01 "Indicates the status of electrical fault on CTI wheel interface.";
CM_ SG_ 2566845694 CTITireStatus_33 "Indicates the status of the tire.";
CM_ SG_ 2566845694 CTITireStatus_32 "Indicates the status of the tire.";
CM_ SG_ 2566845694 CTITireStatus_31 "Indicates the status of the tire.";
CM_ SG_ 2566845694 CTITireStatus_30 "Indicates the status of the tire.";
CM_ SG_ 2566845694 CTITireStatus_23 "Indicates the status of the tire.";
CM_ SG_ 2566845694 CTITireStatus_22 "Indicates the status of the tire.";
CM_ SG_ 2566845694 CTITireStatus_21 "Indicates the status of the tire.";
CM_ SG_ 2566845694 CTITireStatus_20 "Indicates the status of the tire.";
CM_ SG_ 2566845694 CTITireStatus_13 "Indicates the status of the tire.";
CM_ SG_ 2566845694 CTITireStatus_12 "Indicates the status of the tire.";
CM_ SG_ 2566845694 CTITireStatus_11 "Indicates the status of the tire.";
CM_ SG_ 2566845694 CTITireStatus_10 "Indicates the status of the tire.";
CM_ SG_ 2566845694 CTITireStatus_01 "Indicates the status of the tire.";
CM_ SG_ 2566845694 TireTemp_11 "Temperature at the surface of the tire sidewall.";
CM_ SG_ 2566845694 TireTemp_33 "Temperature at the surface of the tire sidewall.";
CM_ SG_ 2566845694 TireTemp_32 "Temperature at the surface of the tire sidewall.";
CM_ SG_ 2566845694 TireTemp_31 "Temperature at the surface of the tire sidewall.";
CM_ SG_ 2566845694 TireTemp_30 "Temperature at the surface of the tire sidewall.";
CM_ SG_ 2566845694 TireTemp_23 "Temperature at the surface of the tire sidewall.";
CM_ SG_ 2566845694 TireTemp_22 "Temperature at the surface of the tire sidewall.";
CM_ SG_ 2566845694 TireTemp_21 "Temperature at the surface of the tire sidewall.";
CM_ SG_ 2566845694 TireTemp_20 "Temperature at the surface of the tire sidewall.";
CM_ SG_ 2566845694 TireTemp_13 "Temperature at the surface of the tire sidewall.";
CM_ SG_ 2566845694 TireTemp_12 "Temperature at the surface of the tire sidewall.";
CM_ SG_ 2566845694 TireTemp_10 "Temperature at the surface of the tire sidewall.";
CM_ SG_ 2566845694 TireTemp_01 "Temperature at the surface of the tire sidewall.";
CM_ SG_ 2566845694 TireTemp_00 "Temperature at the surface of the tire sidewall.";
CM_ SG_ 2566845694 TirePressThresholdDetection_33 "Signal indicating the pressure level of the tire.";
CM_ SG_ 2566845694 TirePressThresholdDetection_32 "Signal indicating the pressure level of the tire.";
CM_ SG_ 2566845694 TirePressThresholdDetection_31 "Signal indicating the pressure level of the tire.";
CM_ SG_ 2566845694 TirePressThresholdDetection_30 "Signal indicating the pressure level of the tire.";
CM_ SG_ 2566845694 TirePressThresholdDetection_23 "Signal indicating the pressure level of the tire.";
CM_ SG_ 2566845694 TirePressThresholdDetection_22 "Signal indicating the pressure level of the tire.";
CM_ SG_ 2566845694 TirePressThresholdDetection_21 "Signal indicating the pressure level of the tire.";
CM_ SG_ 2566845694 TirePressThresholdDetection_20 "Signal indicating the pressure level of the tire.";
CM_ SG_ 2566845694 TirePressThresholdDetection_00 "Signal indicating the pressure level of the tire.";
CM_ SG_ 2566845694 TirePress_01 "Pressure at which air is contained in cavity formed by tire and rim.";
CM_ SG_ 2566845694 TirePress_00 "Pressure at which air is contained in cavity formed by tire and rim.";
CM_ SG_ 2566845694 CTIWheelSensorStatus_00 "Indicates whether the wheel is being monitored by the CTI controller.";
CM_ SG_ 2566845694 CTIWheelEndElectricalFault_00 "Indicates the status of electrical fault on CTI wheel interface.";
CM_ SG_ 2566845694 CTITireStatus_00 "Indicates the status of the tire.";
CM_ SG_ 2566845694 TireLocation "Identifies which tire is associated with the parametric data in this PGN.";
CM_ BO_ 2633939966 "Trip Fan Information";
CM_ SG_ 2633939966 TripFanOnTimeDueToAManualSwitch "Total time the fan has been on due to manual activation by the operator (i.e., excluding time on due to automatic triggers)";
CM_ SG_ 2633939966 TripFanOnTime "Total time the fan has been on (due to an automatic trigger or manual trigger) since the last trip reset. The fan could be";
CM_ SG_ 2633939966 TripFanOnTimeDueToTheA_CSystem "Total time the fan has been on due to the A/C system since the last trip reset. For the time to be accumulated against the";
CM_ SG_ 2633939966 TripFanOnTimeDueToTheEngSystem "Total time the fan has been on due to engine triggers (i.e., excluding time on due to an operator manual switch or A/C";
CM_ BO_ 2633939710 "Trip Distance Information";
CM_ SG_ 2633939710 TripDistanceInTopGear "Total distance accumulated while the vehicle has operated in top gear for a calibrated minimum time since the last trip";
CM_ SG_ 2633939710 TripGearDownDistance "Total distance accumulated while the vehicle has operated in the gear which is one gear down from top gear and exceeds";
CM_ SG_ 2633939710 TripDistanceOnVSL "Total distance accumulated while the engine torque mode is road speed governing since the last trip reset.";
CM_ SG_ 2564161278 AdjustLocalHourOffset "The hour component for setting the offset between the UTC (Universal Time Coordinate) time and date and a the local";
CM_ SG_ 2564161278 AdjustLocalMinuteOffset "The minute component for setting the offset between the UTC (Universal Time Coordinate) time and date and a the local";
CM_ SG_ 2564161278 AdjustYear "The year component for setting the current calendar date. This should be reported as the year component of the current";
CM_ SG_ 2564161278 AdjustDay "The day component for setting the current calendar date. This should be reported as the day component of the current";
CM_ SG_ 2564161278 AdjustMonth "The month component for setting the current calendar date. This should be reported as the month component of the";
CM_ SG_ 2564161278 AdjustHours "The hours component for setting the current time of day. This should be reported as the hours component of the current";
CM_ SG_ 2564161278 AdjustMinutes "The minutes component for setting the current time of day. This should be reported as the minutes component of the";
CM_ SG_ 2564161278 AdjustSeconds "The seconds component for setting the current time of day. This should be reported as the seconds component of the";
CM_ SG_ 2566842110 LocalHourOffset "The hour component of the offset between the UTC (Universal Time Coordinate) time and date and a local time zone time";
CM_ SG_ 2566842110 LocalMinuteOffset "The minute component of the offset between the UTC time and date and a local time zone time and date. This is the";
CM_ SG_ 2566842110 Year "The year component of the current calendar date. This should be reported as the year component of the current date at";
CM_ SG_ 2566842110 Day "The day component of the current calendar date. This should be reported as the day component of the current date at";
CM_ SG_ 2566842110 Month "The month component of the current calendar date. This should be reported as the month component of the current date";
CM_ SG_ 2566842110 Hours "The hour component of the current time of day. This should be reported as the hour component of the current time at";
CM_ SG_ 2566842110 Minutes "The minutes component of the current time of day. This should be reported as the minutes component of the current time";
CM_ SG_ 2566842110 Seconds "The seconds component of the current time of day. This should be reported as the seconds component of the current";
CM_ SG_ 2566821630 EngDsrdTrboWastegateActuator2Pos "The Requested Valve position of the Turbocharger Wastegate Valve 2, commanded by the engine ECM. A value of 0%";
CM_ SG_ 2566821630 EngTrbWstgateActuator1TempStatus "Used to identify the status of the Engine Turbocharger Wastegate Actuator 1 drive circuitry temperature. Temperature";
CM_ SG_ 2566821630 EngTrbWstgtActtor1PreliminaryFMI "Used to identify the applicable J1939-73 FMI detected in the Engine Turbocharger Wastegate Actuator 1 by the";
CM_ SG_ 2566821630 EngDsrdTrboWastegateActuator1Pos "The Requested Valve position of the Turbocharger Wastegate Valve 1, commanded by the engine ECM. A value of 0%";
CM_ SG_ 2566821630 EngTrbWstgteActuatorCtrlAirPress "Gage pressure of the air used to control the actuator which opens and closes the wastegate valve.";
CM_ SG_ 2566821630 EngTurboWastegateActuator4Pos "Position of the wastegate drive. A value of 0% represents fully closed and a value of 100% represents fully open.";
CM_ SG_ 2566821630 EngTurboWastegateActuator3Pos "Position of the wastegate drive. A value of 0% represents fully closed and a value of 100% represents fully open.";
CM_ SG_ 2566821630 EngTurboWastegateActuator2Pos "Position of the wastegate drive. A value of 0% represents fully closed and a value of 100% represents fully open.";
CM_ SG_ 2566821630 EngTurboWastegateActuator1Pos "Position of the wastegate drive. A value of 0% represents fully closed and a value of 100% represents fully open.";
CM_ BO_ 2365484286 "Tachograph";
CM_ SG_ 2365484286 VehicleOverspeed "Indicates whether the vehicle is exceeding the legal speed limit set in the tachograph.";
CM_ SG_ 2365484286 VehicleMotion "Indicates whether motion of the vehicle is detected or not.";
CM_ SG_ 2365484286 TachographVehicleSpeed "Speed of the vehicle registered by the tachograph.";
CM_ SG_ 2365484286 TachographOutputShaftSpeed "Calculated speed of the transmission output shaft.";
CM_ SG_ 2365484286 DirectionIndicator "Indicates the direction of the vehicle.";
CM_ SG_ 2365484286 TachographPerformance "Indicates the tachograph performance; including electronic or mechanical analysis, instrument analysis, speed sensor";
CM_ SG_ 2365484286 HandlingInformation "Indicates that handling information is present. Information could include “no printer paper”, “no driver card”, etc.";
CM_ SG_ 2365484286 SystemEvent "Indicates that a tachograph event has occurred. This may include power supply interruption, interruption of the speed";
CM_ SG_ 2365484286 DriverCardDriver2 "Indicates the presence of a driver card";
CM_ SG_ 2365484286 Driver2TimeRelatedStates "Indicates if the driver approaches or exceeds working time limits (or other limits).";
CM_ SG_ 2365484286 DriverCardDriver1 "Indicates the presence of a driver card";
CM_ SG_ 2365484286 Driver1TimeRelatedStates "Indicates if the driver approaches or exceeds working time limits (or other limits).";
CM_ SG_ 2365484286 Driver2WorkingState "State of work of the driver.";
CM_ SG_ 2365484286 Driver1WorkingState "State of work of the driver.";
CM_ SG_ 2566771710 EngTurbo4CompressorOutletTemp "Temperature of the air exiting the turbocharger 4 compressor outlet";
CM_ SG_ 2566771710 EngTurbo3CompressorOutletTemp "Temperature of the air exiting the turbocharger 3 compressor outlet";
CM_ SG_ 2566771710 EngTurbo2CompressorOutletTemp "Temperature of the air exiting the turbocharger 2 compressor outlet";
CM_ SG_ 2566771710 EngTurbo1CompressorOutletTemp "Temperature of the air exiting the turbocharger 1 compressor outlet";
CM_ SG_ 2566821886 EngTurbo4TurbineOutletTemp "Temperature of the combustion by-products exiting the turbine side of the turbocharger.";
CM_ SG_ 2566821886 EngTurbo3TurbineOutletTemp "Temperature of the combustion by-products exiting the turbine side of the turbocharger.";
CM_ SG_ 2566821886 EngTurbo2TurbineOutletTemp "Temperature of the combustion by-products exiting the turbine side of the turbocharger.";
CM_ SG_ 2566821886 EngTurbo1TurbineOutletTemp "Temperature of the combustion by-products exiting the turbine side of the turbocharger.";
CM_ SG_ 2566822142 EngTurbo4TurbineIntakeTemp "Temperature of the combustion by-products entering the turbine side of the turbocharger.";
CM_ SG_ 2566822142 EngTurbo3TurbineIntakeTemp "Temperature of the combustion by-products entering the turbine side of the turbocharger.";
CM_ SG_ 2566822142 EngTurbo2TurbineIntakeTemp "Temperature of the combustion by-products entering the turbine side of the turbocharger.";
CM_ SG_ 2566822142 EngTurbo1TurbineIntakeTemp "Temperature of the combustion by-products entering the turbine side of the turbocharger.";
CM_ SG_ 2566822398 EngTurbo4CompressorIntakePress "Gage pressure of the air entering the compressor side of the turbocharger.";
CM_ SG_ 2566822398 EngTurbo3CompressorIntakePress "Gage pressure of the air entering the compressor side of the turbocharger.";
CM_ SG_ 2566822398 EngTurbo2CompressorIntakePress "Gage pressure of the air entering the compressor side of the turbocharger.";
CM_ SG_ 2566822398 EngTurbo1CompressorIntakePress "Gage pressure of the air entering the compressor side of the turbocharger.";
CM_ SG_ 2566822654 EngTurbo4CompressorIntakeTemp "Temperature of the air entering the compressor side of the turbocharger.";
CM_ SG_ 2566822654 EngTurbo3CompressorIntakeTemp "Temperature of the air entering the compressor side of the turbocharger.";
CM_ SG_ 2566822654 EngTurbo2CompressorIntakeTemp "Temperature of the air entering the compressor side of the turbocharger.";
CM_ SG_ 2566822654 EngTurbo1CompressorIntakeTemp "Temperature of the air entering the compressor side of the turbocharger.";
CM_ SG_ 2633931774 EngTurbo4Speed "Rotational velocity of rotor in the turbocharger.";
CM_ SG_ 2633931774 EngTurbo3Speed "Rotational velocity of rotor in the turbocharger.";
CM_ SG_ 2633931774 EngTurbo2Speed "Rotational velocity of rotor in the turbocharger.";
CM_ SG_ 2633931774 EngTurboLubeOilPress2 "Gage pressure of oil in turbocharger lubrication system.";
CM_ BO_ 2566802430 "Transmission Configuration 2";
CM_ SG_ 2566802430 TransTorqueLimit "Parameter provided to the engine from the transmission as a torque limit to be invoked by the engine in the event that";
CM_ BO_ 2566841086 "Total message length depends on total number of forward and reverse gear ratios.";
CM_ SG_ 2566841086 TransGearRatio "The transmission configuration describes the number of forward gears, the number of reverse gears, and the ratio of each";
CM_ SG_ 2566841086 NumberOfForwardGearRatios "Number of forward gear ratios in the transmission, provided as part of the configuration.";
CM_ SG_ 2566841086 NumberOfReverseGearRatios "Number of reverse gear ratios in the transmission, provided as part of the transmission configuration.";
CM_ SG_ 2348941054 TransMode8 "Indicates whether transmission mode 8 is enabled. Modes are manufacturer specific and are not necessarily mutually";
CM_ SG_ 2348941054 TransMode7 "Indicates whether transmission mode 7 is enabled. Modes are manufacturer specific and are not necessarily mutually";
CM_ SG_ 2348941054 TransMode6 "Indicates whether transmission mode 6 is enabled. Modes are manufacturer specific and are not necessarily mutually";
CM_ SG_ 2348941054 TransMode5 "Indicates whether transmission mode 5 is enabled. Modes are manufacturer specific and are not necessarily mutually";
CM_ SG_ 2348941054 TrnsShftSlectorDisplayModeSwitch "Status of the operator’s switch used to ‘toggle’ through multiple display modes of a shift selector display.";
CM_ SG_ 2348941054 TransRequestedLaunchGear "Initial gear for the transmission to start out in when the vehicle is launched from a standing stop, as specified by the";
CM_ SG_ 2348941054 TransMode4 "Indicates whether transmission mode 4 is enabled. Modes are manufacturer specific and are not necessarily mutually";
CM_ SG_ 2348941054 TransMode3 "Indicates whether transmission mode 3 is enabled. Modes are manufacturer specific and are not necessarily mutually";
CM_ SG_ 2348941054 TransMode2 "Indicates whether transmission mode 2 is enabled. Modes are manufacturer specific and are not necessarily mutually";
CM_ SG_ 2348941054 TransMode1 "Indicates whether transmission mode 1 is enabled. Modes are manufacturer specific and are not necessarily mutually";
CM_ SG_ 2348941054 DisengageDiffLockRqCentralRear "Command signal used to disengage the various differential locks, e.g., to allow an undistributed individual wheel control";
CM_ SG_ 2348941054 DisengageDiffLockRqCentralFront "Command signal used to disengage the various differential locks, e.g., to allow an undistributed individual wheel control";
CM_ SG_ 2348941054 DisengageDiffLockRqCentral "Command signal used to disengage the various differential locks, e.g., to allow an undistributed individual wheel control";
CM_ SG_ 2348941054 DisengageDiffLockRqRearAxle2 "Command signal used to disengage the various differential locks, e.g., to allow an undistributed individual wheel control";
CM_ SG_ 2348941054 DisengageDiffLockRqRearAxle1 "Command signal used to disengage the various differential locks, e.g., to allow an undistributed individual wheel control";
CM_ SG_ 2348941054 DisengageDiffLockRqFrontAxle2 "Command signal used to disengage the various differential locks, e.g., to allow an undistributed individual wheel control";
CM_ SG_ 2348941054 DisengageDiffLockRqFrontAxle1 "Command signal used to disengage the various differential locks, e.g., to allow an undistributed individual wheel control";
CM_ SG_ 2348941054 TransRequestedGear "Gear requested by the operator, ABS, or engine.";
CM_ SG_ 2348941054 RequestedPercentClutchSlip "Parameter which represents the percent clutch slip requested by a device.";
CM_ SG_ 2348941054 TransReverseGearShiftInhibitRq "Allows devices external to the normal transmission shift selector system to request the transmission to inhibit shifts into";
CM_ SG_ 2348941054 DisengageDrivelineRq "Command signal used to simply disengage the driveline, e.g., to prevent engine drag torque from causing high wheel slip";
CM_ SG_ 2348941054 TrnsTrqeConverterLockupDisableRq "Command signal to prevent torque converter lockup, which may cause problems in certain circumstances for ASR.";
CM_ SG_ 2348941054 TransGearShiftInhibitRq "Command signal to inhibit gear shifts.";
CM_ BO_ 2566839806 "Turbocharger";
CM_ SG_ 2566839806 EngTurboOilLevelSwitch "Switch signal which indicates the presence of oil at the turbocharger";
CM_ SG_ 2566839806 EngTurbo1Speed "Rotational velocity of rotor in the turbocharger.";
CM_ SG_ 2566839806 EngTurboLubeOilPress1 "Gage pressure of oil in turbocharger lubrication system.";
CM_ BO_ 2633911806 "Averages of information accumulated over the life of the engine";
CM_ SG_ 2633911806 EngTotalAverageFuelEconomy "Average fuel economy, equal to total vehicle distance divided by total fuel used, over the life of the engine";
CM_ SG_ 2633911806 EngTotalAverageFuelRate "Average fuel rate, equal to total fuel used divided by total engine hours, over the life of the engine";
CM_ BO_ 2566775550 "Used for controlling the supply pressure. Often used to raise the pressure of a supply pressure circuit in situations where";
CM_ SG_ 2566775550 AirSuspensionSupplyPressRq "Command signal to influence the pneumatic pressure in the circuit for the electronically controlled air suspension system.";
CM_ SG_ 2566775550 AuxEquipmentSupplyPressRq "Command signal to influence the pneumatic pressure in the auxiliary circuit. This parameter is the setpoint for the";
CM_ SG_ 2566775550 ServiceBrakeAirPressRqCircuit2 "Command signal to influence the pneumatic pressure in the service brake circuit or reservoir #2. This parameter is the";
CM_ SG_ 2566775550 ServiceBrakeAirPressRqCircuit1 "Command signal to influence the pneumatic pressure in the service brake circuit or reservoir #1. This parameter is the";
CM_ SG_ 2566775550 ParkingAnd_orTrailerAirPressRq "Command signal to influence the pneumatic pressure in the circuit or reservoir for the parking brake and/or the trailer";
CM_ SG_ 2566775550 PneumaticSupplyPressRq "Command signal to influence the pneumatic pressure in the main reservoir. This parameter is the setpoint for the";
CM_ SG_ 2566819838 EngExtlShutdownAirSupplyPress "Pressure of the air used to shut off the fuel supply to the engine.";
CM_ BO_ 2566839038 "Byte: 1 Number of software identification fields";
CM_ SG_ 2566839038 NmbrOfSftwreIdentificationFields "Number of software identification designators represented in the software identification parameter group.";
CM_ SG_ 2566839038 SoftwareIdentification "Software identification of an electronic module. As an example, this parameter may be represented with ASCII characters";
CM_ SG_ 2566841598 PTOShutdownHasShutdownEng "Status signal which identifies whether or not the engine has been shutdown by the PTO shutdown system.";
CM_ SG_ 2566841598 EngAirShutoffStatus "State signal which indicates the actual measured position of the Air Shutoff.";
CM_ SG_ 2566841598 EngOverspeedTest "The engine overspeed test signal as measured by the reporting ECM. Engine Overspeed Test is a mechanism to";
CM_ SG_ 2566841598 EngAirShutoffCmdStatus "State signal which indicates when the Air Shutoff driver output is being driven. Disabled means controller wants air";
CM_ SG_ 2566841598 EngAlarmOutputCmdStatus "State signal which indicates when the Alarm driver output is being driven. Not active means the Controller has no alarm";
CM_ SG_ 2566841598 EngAlarmAcknowledge "The Engine Alarm Acknowledge Input signal as measured by the reporting ECM. The Engine Alarm Acknowledge is a";
CM_ SG_ 2566841598 EngProtectionSystemConfig "Parameter which indicates the configuration of the engine shutdown system.";
CM_ SG_ 2566841598 EngProtectionSystemTimerState "Status signal which indicates the current mode of the engine protection system timer system. See Figure SPN1107_A.";
CM_ SG_ 2566841598 EngProtectionSystemTimerOverride "Status signal which indicates the status of the override feature of the engine protection system timer. See Figure";
CM_ SG_ 2566841598 EngPrtctnSystmApprachingShutdown "Status signal which indicates that engine shutdown is imminent. This engine protection signal can be a result of different";
CM_ SG_ 2566841598 EngPrtectionSystemHasShutdownEng "Status signal which indicates whether or not the engine protection system has shutdown the engine. See Figure";
CM_ SG_ 2566841598 EngWaitToStartLamp "Lamp signal which indicates that the engine is too cold to start and the operator should wait until the signal becomes";
CM_ SG_ 2566841598 RefrigerantHighPressSwitch "Switch signal which indicates the position of the high pressure switch in the coolant circuit of an air conditioning system.";
CM_ SG_ 2566841598 RefrigerantLowPressSwitch "Switch signal which indicates the position of the low pressure switch in the coolant circuit of an air conditioning system.";
CM_ SG_ 2566841598 A_CHighPressFanSwitch "Switch signal which indicates that the pressure in the coolant circuit of an air conditioning system is high and the fan may";
CM_ SG_ 2566841598 EngIdleShutdownTimerFunction "Parameter which indicates the configuration of the idle shutdown timer system.";
CM_ SG_ 2566841598 EngIdleShutdownTimerState "Status signal which indicates the current mode of operation of the idle shutdown timer system. See Figure SPN590_A.";
CM_ SG_ 2566841598 EngIdleShutdownTimerOverride "Status signal which indicates the status of the override feature of the idle shutdown timer system. See Figure SPN590_A.";
CM_ SG_ 2566841598 EngIdleShutdownDriverAlertMode "Status signal which indicates the status of the driver alert mode of the idle shutdown timer system. While the driver alert";
CM_ SG_ 2566841598 EngIdleShutdownHasShutdownEng "Status signal which identifies whether or not the engine has been shutdown by the idle shutdown timer system. See";
BA_DEF_ BO_  "GenMsgCycleTimeFast" INT 0 3600000;
BA_DEF_ SG_  "SigType" ENUM  "Default","Range","RangeSigned","ASCII","Discrete","Control","ReferencePGN","DTC","StringDelimiter","StringLength","StringLengthControl";
BA_DEF_ SG_  "GenSigStartValue" INT 0 10000;
BA_DEF_ SG_  "GenSigSendType" ENUM  "Cyclic","OnWrite","reserved","OnChange","reserved","reserved","reserved","NoSigSendType";
BA_DEF_ SG_  "GenSigILSupport" ENUM  "Yes","No";
BA_DEF_ SG_  "GenSigEVName" STRING ;
BA_DEF_ SG_  "SPN" INT 0 524287;
BA_DEF_ SG_  "DDI" INT 0 65535;
BA_DEF_ SG_  "SAEDocument" STRING ;
BA_DEF_ BO_  "GenMsgStartDelayTime" INT 0 100000;
BA_DEF_ BO_  "GenMsgILSupport" ENUM  "Yes","No";
BA_DEF_ BO_  "GenMsgRequestable" INT 0 1;
BA_DEF_ BO_  "GenMsgSendType" ENUM  "cyclic","reserved","cyclicIfActive","reserved","reserved","reserved","reserved","reserved","noMsgSendType";
BA_DEF_ BO_  "VFrameFormat" ENUM  "StandardCAN","ExtendedCAN","reserved","J1939PG";
BA_DEF_ BO_  "SingleFrame" INT 0 1;
BA_DEF_ BO_  "GenMsgCycleTime" INT 0 3600000;
BA_DEF_ BO_  "SAE_Document" STRING ;
BA_DEF_ SG_  "SystemSignalLongSymbol" STRING ;
BA_DEF_DEF_  "GenMsgCycleTimeFast" 0;
BA_DEF_DEF_  "SigType" "Default";
BA_DEF_DEF_  "GenSigStartValue" 0;
BA_DEF_DEF_  "GenSigSendType" "NoSigSendType";
BA_DEF_DEF_  "GenSigILSupport" "Yes";
BA_DEF_DEF_  "GenSigEVName" "Env@Nodename_@Signame";
BA_DEF_DEF_  "SPN" 0;
BA_DEF_DEF_  "DDI" 0;
BA_DEF_DEF_  "SAEDocument" "";
BA_DEF_DEF_  "GenMsgStartDelayTime" 0;
BA_DEF_DEF_  "GenMsgILSupport" "Yes";
BA_DEF_DEF_  "GenMsgRequestable" 1;
BA_DEF_DEF_  "GenMsgSendType" "noMsgSendType";
BA_DEF_DEF_  "VFrameFormat" "J1939PG";
BA_DEF_DEF_  "SingleFrame" 1;
BA_DEF_DEF_  "GenMsgCycleTime" 0;
BA_DEF_DEF_  "SAE_Document" "";
BA_DEF_DEF_  "SystemSignalLongSymbol" "";
BA_ "SAE_Document" BO_ 2565734142 "J1939-71";
BA_ "GenMsgSendType" BO_ 2565144318 0;
BA_ "GenMsgCycleTime" BO_ 2565144318 100;
BA_ "SAE_Document" BO_ 2565144318 "ISO15765";
BA_ "GenMsgSendType" BO_ 2565209854 0;
BA_ "GenMsgCycleTime" BO_ 2565209854 100;
BA_ "SAE_Document" BO_ 2565209854 "ISO11992";
BA_ "GenMsgSendType" BO_ 2566806782 0;
BA_ "GenMsgCycleTime" BO_ 2566806782 100;
BA_ "SAE_Document" BO_ 2566806782 "ISO11992";
BA_ "GenMsgSendType" BO_ 2566807294 0;
BA_ "GenMsgCycleTime" BO_ 2566807294 1000;
BA_ "SAE_Document" BO_ 2566807294 "ISO11992";
BA_ "SAE_Document" BO_ 2566764798 "J1939-73";
BA_ "SAE_Document" BO_ 2564095742 "J1939-73";
BA_ "GenMsgSendType" BO_ 2349137662 2;
BA_ "GenMsgCycleTime" BO_ 2349137662 20;
BA_ "SAE_Document" BO_ 2349137662 "J1939-71";
BA_ "GenMsgSendType" BO_ 2566848510 0;
BA_ "GenMsgCycleTime" BO_ 2566848510 10000;
BA_ "SAE_Document" BO_ 2566848510 "J1939-71";
BA_ "SAE_Document" BO_ 2566843134 "J1939-71";
BA_ "GenMsgSendType" BO_ 2566804222 0;
BA_ "GenMsgCycleTime" BO_ 2566804222 1000;
BA_ "SAE_Document" BO_ 2566804222 "J1939-71";
BA_ "SAE_Document" BO_ 2566819326 "J1939-71";
BA_ "GenMsgSendType" BO_ 2566845438 0;
BA_ "GenMsgCycleTime" BO_ 2566845438 5000;
BA_ "SAE_Document" BO_ 2566845438 "J1939-71";
BA_ "SAE_Document" BO_ 2566843646 "J1939-71";
BA_ "SAE_Document" BO_ 2566842366 "J1939-71";
BA_ "GenMsgSendType" BO_ 2566809854 0;
BA_ "GenMsgCycleTime" BO_ 2566809854 1000;
BA_ "SAE_Document" BO_ 2566809854 "J1939-71";
BA_ "SAE_Document" BO_ 2566842622 "J1939-71";
BA_ "GenMsgSendType" BO_ 2566832638 0;
BA_ "GenMsgCycleTime" BO_ 2566832638 1000;
BA_ "SAE_Document" BO_ 2566832638 "J1939-71";
BA_ "GenMsgSendType" BO_ 2565868030 0;
BA_ "GenMsgCycleTime" BO_ 2565868030 10;
BA_ "SAE_Document" BO_ 2565868030 "J1939-71";
BA_ "SAE_Document" BO_ 2566803454 "J1939-71";
BA_ "GenMsgSendType" BO_ 2566840574 0;
BA_ "GenMsgCycleTime" BO_ 2566840574 100;
BA_ "SAE_Document" BO_ 2566840574 "J1939-71";
BA_ "SAE_Document" BO_ 2633938686 "J1939-71";
BA_ "SAE_Document" BO_ 2633937150 "J1939-71";
BA_ "SAE_Document" BO_ 2633938174 "J1939-71";
BA_ "SAE_Document" BO_ 2633938430 "J1939-71";
BA_ "GenMsgSendType" BO_ 2348875518 0;
BA_ "GenMsgCycleTime" BO_ 2348875518 10;
BA_ "SAE_Document" BO_ 2348875518 "J1939-71";
BA_ "SAE_Document" BO_ 2566766846 "J1939-71";
BA_ "SAE_Document" BO_ 2566765310 "J1939-71";
BA_ "SAE_Document" BO_ 2566765566 "J1939-71";
BA_ "SAE_Document" BO_ 2566765822 "J1939-71";
BA_ "SAE_Document" BO_ 2566766078 "J1939-71";
BA_ "SAE_Document" BO_ 2566766590 "J1939-71";
BA_ "SAE_Document" BO_ 2566766334 "J1939-71";
BA_ "SAE_Document" BO_ 2561605374 "J1939-71";
BA_ "SAE_Document" BO_ 2566765054 "J1939-71";
BA_ "SAE_Document" BO_ 2633923326 "J1939-71";
BA_ "SAE_Document" BO_ 2633923070 "J1939-71";
BA_ "SAE_Document" BO_ 2633922814 "J1939-71";
BA_ "GenMsgSendType" BO_ 2566845694 0;
BA_ "GenMsgCycleTime" BO_ 2566845694 10000;
BA_ "SAE_Document" BO_ 2566845694 "J1939-71";
BA_ "SAE_Document" BO_ 2633939966 "J1939-71";
BA_ "SAE_Document" BO_ 2633939710 "J1939-71";
BA_ "SAE_Document" BO_ 2564161278 "J1939-71";
BA_ "SAE_Document" BO_ 2566842110 "J1939-71";
BA_ "GenMsgSendType" BO_ 2566821630 0;
BA_ "GenMsgCycleTime" BO_ 2566821630 100;
BA_ "SAE_Document" BO_ 2566821630 "J1939-71";
BA_ "GenMsgSendType" BO_ 2365484286 0;
BA_ "GenMsgCycleTime" BO_ 2365484286 50;
BA_ "SAE_Document" BO_ 2365484286 "J1939-71";
BA_ "GenMsgSendType" BO_ 2566771710 0;
BA_ "GenMsgCycleTime" BO_ 2566771710 1000;
BA_ "SAE_Document" BO_ 2566771710 "J1939-71";
BA_ "GenMsgSendType" BO_ 2566821886 0;
BA_ "GenMsgCycleTime" BO_ 2566821886 1000;
BA_ "SAE_Document" BO_ 2566821886 "J1939-71";
BA_ "GenMsgSendType" BO_ 2566822142 0;
BA_ "GenMsgCycleTime" BO_ 2566822142 1000;
BA_ "SAE_Document" BO_ 2566822142 "J1939-71";
BA_ "GenMsgSendType" BO_ 2566822398 0;
BA_ "GenMsgCycleTime" BO_ 2566822398 1000;
BA_ "SAE_Document" BO_ 2566822398 "J1939-71";
BA_ "GenMsgSendType" BO_ 2566822654 0;
BA_ "GenMsgCycleTime" BO_ 2566822654 1000;
BA_ "SAE_Document" BO_ 2566822654 "J1939-71";
BA_ "GenMsgSendType" BO_ 2633931774 0;
BA_ "GenMsgCycleTime" BO_ 2633931774 1000;
BA_ "SAE_Document" BO_ 2633931774 "J1939-71";
BA_ "SAE_Document" BO_ 2566802430 "J1939-71";
BA_ "SAE_Document" BO_ 2566841086 "J1939-71";
BA_ "GenMsgSendType" BO_ 2348941054 2;
BA_ "GenMsgCycleTime" BO_ 2348941054 50;
BA_ "SAE_Document" BO_ 2348941054 "J1939-71";
BA_ "GenMsgSendType" BO_ 2566839806 0;
BA_ "GenMsgCycleTime" BO_ 2566839806 1000;
BA_ "SAE_Document" BO_ 2566839806 "J1939-71";
BA_ "SAE_Document" BO_ 2633911806 "J1939-71";
BA_ "GenMsgSendType" BO_ 2566775550 2;
BA_ "GenMsgCycleTime" BO_ 2566775550 1000;
BA_ "SAE_Document" BO_ 2566775550 "J1939-71";
BA_ "GenMsgSendType" BO_ 2566819838 0;
BA_ "GenMsgCycleTime" BO_ 2566819838 1000;
BA_ "SAE_Document" BO_ 2566819838 "J1939-71";
BA_ "SAE_Document" BO_ 2566839038 "J1939-71";
BA_ "GenMsgSendType" BO_ 2566841598 0;
BA_ "GenMsgCycleTime" BO_ 2566841598 1000;
BA_ "SAE_Document" BO_ 2566841598 "J1939-71";
BA_ "SigType" SG_ 2565734142 ControlByte 1;
BA_ "SAEDocument" SG_ 2565734142 ControlByte "J1939-21";
BA_ "SigType" SG_ 2565734142 FilterMode 1;
BA_ "SAEDocument" SG_ 2565734142 FilterMode "J1939-71";
BA_ "SAEDocument" SG_ 2565734142 ToPort "J1939-71";
BA_ "SAEDocument" SG_ 2565734142 FromPort "J1939-71";
BA_ "SigType" SG_ 2565144318 ParkingAndTrailerAirPress 1;
BA_ "SAEDocument" SG_ 2565144318 ParkingAndTrailerAirPress "ISO15765";
BA_ "SAEDocument" SG_ 2565144318 DrivenAxleLoad "ISO15765";
BA_ "SigType" SG_ 2565144318 AuxEquipSupplyPressure 1;
BA_ "SAEDocument" SG_ 2565144318 AuxEquipSupplyPressure "ISO15765";
BA_ "SigType" SG_ 2565144318 StopLevelChangeReq 4;
BA_ "SAEDocument" SG_ 2565144318 StopLevelChangeReq "ISO15765";
BA_ "SigType" SG_ 2565144318 RampLevelStorageReq 4;
BA_ "SAEDocument" SG_ 2565144318 RampLevelStorageReq "ISO15765";
BA_ "SigType" SG_ 2565144318 LevelControlReq 4;
BA_ "SAEDocument" SG_ 2565144318 LevelControlReq "ISO15765";
BA_ "SigType" SG_ 2565144318 RampLevelReq 4;
BA_ "SAEDocument" SG_ 2565144318 RampLevelReq "ISO15765";
BA_ "SigType" SG_ 2565144318 SteeringAxleLockingReq 4;
BA_ "SAEDocument" SG_ 2565144318 SteeringAxleLockingReq "ISO15765";
BA_ "SigType" SG_ 2565144318 LiftAxle2PositionReq 4;
BA_ "SAEDocument" SG_ 2565144318 LiftAxle2PositionReq "ISO15765";
BA_ "SigType" SG_ 2565144318 LiftAxle1PositionReq 4;
BA_ "SAEDocument" SG_ 2565144318 LiftAxle1PositionReq "ISO15765";
BA_ "SigType" SG_ 2565144318 TractionHelpReq 4;
BA_ "SAEDocument" SG_ 2565144318 TractionHelpReq "ISO15765";
BA_ "SigType" SG_ 2565144318 LevelChangeReqRearAxle 4;
BA_ "SAEDocument" SG_ 2565144318 LevelChangeReqRearAxle "ISO15765";
BA_ "SigType" SG_ 2565144318 LevelChangeReqFrontAxle 4;
BA_ "SAEDocument" SG_ 2565144318 LevelChangeReqFrontAxle "ISO15765";
BA_ "SigType" SG_ 2565144318 RideHeightRequest 4;
BA_ "SAEDocument" SG_ 2565144318 RideHeightRequest "ISO15765";
BA_ "SigType" SG_ 2565209854 LevelControl 4;
BA_ "SAEDocument" SG_ 2565209854 LevelControl "ISO15765";
BA_ "SAEDocument" SG_ 2565209854 NominalVehBodyLevelRearAxle "ISO15765";
BA_ "SAEDocument" SG_ 2565209854 NominalVehBodyLevelFrontAxle "ISO15765";
BA_ "SigType" SG_ 2565209854 RampLevel 4;
BA_ "SAEDocument" SG_ 2565209854 RampLevel "ISO15765";
BA_ "SigType" SG_ 2565209854 NormalLevel 4;
BA_ "SAEDocument" SG_ 2565209854 NormalLevel "ISO15765";
BA_ "SigType" SG_ 2565209854 StopLevelChangeAcknowledge 4;
BA_ "SAEDocument" SG_ 2565209854 StopLevelChangeAcknowledge "ISO15765";
BA_ "SigType" SG_ 2565209854 LevelChangeRearAxle 4;
BA_ "SAEDocument" SG_ 2565209854 LevelChangeRearAxle "ISO15765";
BA_ "SigType" SG_ 2565209854 LevelChangeFrontAxle 4;
BA_ "SAEDocument" SG_ 2565209854 LevelChangeFrontAxle "ISO15765";
BA_ "SigType" SG_ 2565209854 RampLevelStorage 4;
BA_ "SAEDocument" SG_ 2565209854 RampLevelStorage "ISO15765";
BA_ "SigType" SG_ 2565209854 SteeringAxleLocking 4;
BA_ "SAEDocument" SG_ 2565209854 SteeringAxleLocking "ISO15765";
BA_ "SigType" SG_ 2565209854 LiftAxle2Pos 4;
BA_ "SPN" SG_ 2565209854 LiftAxle2Pos 1822;
BA_ "SAEDocument" SG_ 2565209854 LiftAxle2Pos "J1939-71";
BA_ "SigType" SG_ 2565209854 LiftAxle1Pos 4;
BA_ "SPN" SG_ 2565209854 LiftAxle1Pos 1743;
BA_ "SAEDocument" SG_ 2565209854 LiftAxle1Pos "J1939-71";
BA_ "SigType" SG_ 2565209854 RampLevelPosition 4;
BA_ "SAEDocument" SG_ 2565209854 RampLevelPosition "ISO15765";
BA_ "SigType" SG_ 2565209854 TractionHelp 4;
BA_ "SAEDocument" SG_ 2565209854 TractionHelp "ISO15765";
BA_ "SigType" SG_ 2565209854 LevelCtrlSysRideHeightLevel 4;
BA_ "SAEDocument" SG_ 2565209854 LevelCtrlSysRideHeightLevel "ISO15765";
BA_ "SAEDocument" SG_ 2566806782 RelVehBodyLevelRearAxle "ISO11992";
BA_ "SAEDocument" SG_ 2566806782 RelVehBodyLevelFrontAxle "ISO11992";
BA_ "SAEDocument" SG_ 2566807294 TyrePressThresholdDetect "ISO11992";
BA_ "SigType" SG_ 2566807294 TyreModulePowerSupply 4;
BA_ "SAEDocument" SG_ 2566807294 TyreModulePowerSupply "ISO11992";
BA_ "SAEDocument" SG_ 2566807294 TyreTemperature "ISO11992";
BA_ "SAEDocument" SG_ 2566807294 AirLeakageDetection "ISO11992";
BA_ "SAEDocument" SG_ 2566807294 TyreWheelIdentification2 "ISO11992";
BA_ "SAEDocument" SG_ 2566807294 TyreWheelIdentification1 "ISO11992";
BA_ "SystemSignalLongSymbol" SG_ 2566764798 NOxConvertingCatalystAdsorberCom "NOxConvertingCatalystAdsorberCompleted";
BA_ "SystemSignalLongSymbol" SG_ 2566764798 NOxConvertingCatalystAdsorberEna "NOxConvertingCatalystAdsorberEnabled";
BA_ "SystemSignalLongSymbol" SG_ 2566764798 BoostPressureControlSystemComple "BoostPressureControlSystemCompleted";
BA_ "SystemSignalLongSymbol" SG_ 2566764798 BoostPressureControlSystemEnable "BoostPressureControlSystemEnabled";
BA_ "SAEDocument" SG_ 2566764798 MisfireMonitoringComplete "J1939-73";
BA_ "SAEDocument" SG_ 2566764798 MisfireMonitoringEnabled "J1939-73";
BA_ "SAEDocument" SG_ 2566764798 FuelSystemMonitoringEnabled "J1939-73";
BA_ "SAEDocument" SG_ 2566764798 ComprehensiveComptMonComplete "J1939-73";
BA_ "SAEDocument" SG_ 2566764798 ComprehensiveCompMonEnabled "J1939-73";
BA_ "SAEDocument" SG_ 2566764798 SecondAirSystemMonComplete "J1939-73";
BA_ "SAEDocument" SG_ 2566764798 SecondAirSystemMonEnabled "J1939-73";
BA_ "SAEDocument" SG_ 2566764798 OxygenSensorMonComplete "J1939-73";
BA_ "SAEDocument" SG_ 2566764798 OxygenSensorMonEnabled "J1939-73";
BA_ "SAEDocument" SG_ 2566764798 OxygenSensorHeaterMonComplete "J1939-73";
BA_ "SAEDocument" SG_ 2566764798 OxygenSensorHeaterMonEnabled "J1939-73";
BA_ "SAEDocument" SG_ 2566764798 HeatedCatalystMonComplete "J1939-73";
BA_ "SAEDocument" SG_ 2566764798 HeatedCatalystMonEnabled "J1939-73";
BA_ "SAEDocument" SG_ 2566764798 EvaporativeSystemMonComplete "J1939-73";
BA_ "SAEDocument" SG_ 2566764798 EvaporativeSystemMonEnabled "J1939-73";
BA_ "SAEDocument" SG_ 2566764798 EGRSystemMonitoringComplete "J1939-73";
BA_ "SAEDocument" SG_ 2566764798 EGRSystemMonitoringEnabled "J1939-73";
BA_ "SAEDocument" SG_ 2566764798 ColdStartAidSystemMonComplete "J1939-73";
BA_ "SAEDocument" SG_ 2566764798 ColdStartAidSystemMonEnabled "J1939-73";
BA_ "SAEDocument" SG_ 2566764798 CatalystMonComplete "J1939-73";
BA_ "SAEDocument" SG_ 2566764798 CatalystMonEnabled "J1939-73";
BA_ "SAEDocument" SG_ 2566764798 ACSystemRefrigerantMonComplete "J1939-73";
BA_ "SAEDocument" SG_ 2566764798 ACSystemRefrigerantMonEnabled "J1939-73";
BA_ "SAEDocument" SG_ 2566764798 FuelSystemMonitoringComplete "J1939-73";
BA_ "SPN" SG_ 2566764798 NumOfWarmUpsSinceDTCsCleared 3302;
BA_ "SAEDocument" SG_ 2566764798 NumOfWarmUpsSinceDTCsCleared "J1939-73";
BA_ "SPN" SG_ 2566764798 TimeSinceEngineStart 3301;
BA_ "SAEDocument" SG_ 2566764798 TimeSinceEngineStart "J1939-73";
BA_ "SAEDocument" SG_ 2564095742 SecurityEntityLengthHigh "J1939-73";
BA_ "SPN" SG_ 2564095742 SecurityEntityType 1479;
BA_ "SAEDocument" SG_ 2564095742 SecurityEntityType "J1939-73";
BA_ "SPN" SG_ 2564095742 SecurityEntityLength 1596;
BA_ "SAEDocument" SG_ 2564095742 SecurityEntityLength "J1939-73";
BA_ "SPN" SG_ 2349137662 XBRMessageChecksum 3188;
BA_ "SAEDocument" SG_ 2349137662 XBRMessageChecksum "J1939-71";
BA_ "SPN" SG_ 2349137662 XBRMessageCounter 3189;
BA_ "SAEDocument" SG_ 2349137662 XBRMessageCounter "J1939-71";
BA_ "SPN" SG_ 2349137662 XBRUrgency 4099;
BA_ "SAEDocument" SG_ 2349137662 XBRUrgency "J1939-71";
BA_ "SigType" SG_ 2349137662 XBRCtrlMode 5;
BA_ "SPN" SG_ 2349137662 XBRCtrlMode 2916;
BA_ "SAEDocument" SG_ 2349137662 XBRCtrlMode "J1939-71";
BA_ "SigType" SG_ 2349137662 XBRPriority 5;
BA_ "SPN" SG_ 2349137662 XBRPriority 2915;
BA_ "SAEDocument" SG_ 2349137662 XBRPriority "J1939-71";
BA_ "SigType" SG_ 2349137662 XBREBIMode 5;
BA_ "SPN" SG_ 2349137662 XBREBIMode 2914;
BA_ "SAEDocument" SG_ 2349137662 XBREBIMode "J1939-71";
BA_ "SPN" SG_ 2349137662 ExtlAccelerationDemand 2920;
BA_ "SAEDocument" SG_ 2349137662 ExtlAccelerationDemand "J1939-71";
BA_ "SigType" SG_ 2566848510 WaterInFuelIndicator 4;
BA_ "SPN" SG_ 2566848510 WaterInFuelIndicator 97;
BA_ "SAEDocument" SG_ 2566848510 WaterInFuelIndicator "J1939-71";
BA_ "SigType" SG_ 2566843134 AxleLocation 1;
BA_ "SPN" SG_ 2566843134 AxleLocation 928;
BA_ "SAEDocument" SG_ 2566843134 AxleLocation "J1939-71";
BA_ "SigType" SG_ 2566843134 CargoWeight_30 1;
BA_ "SPN" SG_ 2566843134 CargoWeight_30 522230;
BA_ "SigType" SG_ 2566843134 CargoWeight_20 1;
BA_ "SPN" SG_ 2566843134 CargoWeight_20 522220;
BA_ "SigType" SG_ 2566843134 CargoWeight_10 1;
BA_ "SPN" SG_ 2566843134 CargoWeight_10 522210;
BA_ "SigType" SG_ 2566843134 CargoWeight_00 1;
BA_ "SPN" SG_ 2566843134 CargoWeight_00 522200;
BA_ "SigType" SG_ 2566843134 TrailerWeight_30 1;
BA_ "SPN" SG_ 2566843134 TrailerWeight_30 522130;
BA_ "SigType" SG_ 2566843134 TrailerWeight_20 1;
BA_ "SPN" SG_ 2566843134 TrailerWeight_20 522120;
BA_ "SigType" SG_ 2566843134 TrailerWeight_10 1;
BA_ "SPN" SG_ 2566843134 TrailerWeight_10 522110;
BA_ "SigType" SG_ 2566843134 TrailerWeight_00 1;
BA_ "SPN" SG_ 2566843134 TrailerWeight_00 522100;
BA_ "SigType" SG_ 2566843134 AxleWeight_30 1;
BA_ "SPN" SG_ 2566843134 AxleWeight_30 522030;
BA_ "SigType" SG_ 2566843134 AxleWeight_20 1;
BA_ "SPN" SG_ 2566843134 AxleWeight_20 522020;
BA_ "SigType" SG_ 2566843134 AxleWeight_10 1;
BA_ "SPN" SG_ 2566843134 AxleWeight_10 522010;
BA_ "SigType" SG_ 2566843134 AxleWeight_00 1;
BA_ "SPN" SG_ 2566843134 AxleWeight_00 522000;
BA_ "SigType" SG_ 2566804222 NetBatteryCurrent 1;
BA_ "SPN" SG_ 2566804222 NetBatteryCurrent 2579;
BA_ "SAEDocument" SG_ 2566804222 NetBatteryCurrent "J1939-71";
BA_ "SigType" SG_ 2566804222 AltCurrent 1;
BA_ "SPN" SG_ 2566804222 AltCurrent 1795;
BA_ "SAEDocument" SG_ 2566804222 AltCurrent "J1939-71";
BA_ "SigType" SG_ 2566819326 ECUPowerOutputSupplyVoltage3 1;
BA_ "SPN" SG_ 2566819326 ECUPowerOutputSupplyVoltage3 3599;
BA_ "SAEDocument" SG_ 2566819326 ECUPowerOutputSupplyVoltage3 "J1939-71";
BA_ "SigType" SG_ 2566819326 ECUPowerOutputSupplyVoltage2 1;
BA_ "SPN" SG_ 2566819326 ECUPowerOutputSupplyVoltage2 3598;
BA_ "SAEDocument" SG_ 2566819326 ECUPowerOutputSupplyVoltage2 "J1939-71";
BA_ "SigType" SG_ 2566819326 ECUPowerOutputSupplyVoltage1 1;
BA_ "SPN" SG_ 2566819326 ECUPowerOutputSupplyVoltage1 3597;
BA_ "SAEDocument" SG_ 2566819326 ECUPowerOutputSupplyVoltage1 "J1939-71";
BA_ "SigType" SG_ 2566819326 BatteryPotential_PowerInput2 1;
BA_ "SPN" SG_ 2566819326 BatteryPotential_PowerInput2 444;
BA_ "SAEDocument" SG_ 2566819326 BatteryPotential_PowerInput2 "J1939-71";
BA_ "SigType" SG_ 2566845438 Longitude 1;
BA_ "SPN" SG_ 2566845438 Longitude 585;
BA_ "SAEDocument" SG_ 2566845438 Longitude "J1939-71";
BA_ "SigType" SG_ 2566845438 Latitude 1;
BA_ "SPN" SG_ 2566845438 Latitude 584;
BA_ "SAEDocument" SG_ 2566845438 Latitude "J1939-71";
BA_ "SigType" SG_ 2566843646 VehicleIdentificationNumber 1;
BA_ "SPN" SG_ 2566843646 VehicleIdentificationNumber 237;
BA_ "SAEDocument" SG_ 2566843646 VehicleIdentificationNumber "J1939-71";
BA_ "SigType" SG_ 2566842366 TotalPowerTakeoffHours 1;
BA_ "SPN" SG_ 2566842366 TotalPowerTakeoffHours 248;
BA_ "SAEDocument" SG_ 2566842366 TotalPowerTakeoffHours "J1939-71";
BA_ "SigType" SG_ 2566842366 TotalVehicleHours 1;
BA_ "SPN" SG_ 2566842366 TotalVehicleHours 246;
BA_ "SAEDocument" SG_ 2566842366 TotalVehicleHours "J1939-71";
BA_ "SigType" SG_ 2566809854 HydOilLevel 1;
BA_ "SPN" SG_ 2566809854 HydOilLevel 2602;
BA_ "SAEDocument" SG_ 2566809854 HydOilLevel "J1939-71";
BA_ "SigType" SG_ 2566809854 WinchOilPressSwitch 4;
BA_ "SPN" SG_ 2566809854 WinchOilPressSwitch 1857;
BA_ "SAEDocument" SG_ 2566809854 WinchOilPressSwitch "J1939-71";
BA_ "SigType" SG_ 2566809854 HydOilFilterRestrictionSwitch 4;
BA_ "SPN" SG_ 2566809854 HydOilFilterRestrictionSwitch 1713;
BA_ "SAEDocument" SG_ 2566809854 HydOilFilterRestrictionSwitch "J1939-71";
BA_ "SigType" SG_ 2566809854 HydTemp 1;
BA_ "SPN" SG_ 2566809854 HydTemp 1638;
BA_ "SAEDocument" SG_ 2566809854 HydTemp "J1939-71";
BA_ "SigType" SG_ 2566842622 Altitude 1;
BA_ "SPN" SG_ 2566842622 Altitude 580;
BA_ "SAEDocument" SG_ 2566842622 Altitude "J1939-71";
BA_ "SigType" SG_ 2566842622 Pitch 1;
BA_ "SPN" SG_ 2566842622 Pitch 583;
BA_ "SAEDocument" SG_ 2566842622 Pitch "J1939-71";
BA_ "SigType" SG_ 2566842622 NavigationBasedVehicleSpeed 1;
BA_ "SPN" SG_ 2566842622 NavigationBasedVehicleSpeed 517;
BA_ "SAEDocument" SG_ 2566842622 NavigationBasedVehicleSpeed "J1939-71";
BA_ "SigType" SG_ 2566842622 CompassBearing 1;
BA_ "SPN" SG_ 2566842622 CompassBearing 165;
BA_ "SAEDocument" SG_ 2566842622 CompassBearing "J1939-71";
BA_ "SigType" SG_ 2566832638 HighResolutionTripDistance 1;
BA_ "SPN" SG_ 2566832638 HighResolutionTripDistance 918;
BA_ "SAEDocument" SG_ 2566832638 HighResolutionTripDistance "J1939-71";
BA_ "SigType" SG_ 2566832638 HghRsolutionTotalVehicleDistance 1;
BA_ "SPN" SG_ 2566832638 HghRsolutionTotalVehicleDistance 917;
BA_ "SAEDocument" SG_ 2566832638 HghRsolutionTotalVehicleDistance "J1939-71";
BA_ "SigType" SG_ 2565868030 LongitudinalAcceleration 1;
BA_ "SPN" SG_ 2565868030 LongitudinalAcceleration 1810;
BA_ "SAEDocument" SG_ 2565868030 LongitudinalAcceleration "J1939-71";
BA_ "SigType" SG_ 2565868030 LateralAcceleration 1;
BA_ "SPN" SG_ 2565868030 LateralAcceleration 1809;
BA_ "SAEDocument" SG_ 2565868030 LateralAcceleration "J1939-71";
BA_ "SigType" SG_ 2565868030 YawRate 1;
BA_ "SPN" SG_ 2565868030 YawRate 1808;
BA_ "SAEDocument" SG_ 2565868030 YawRate "J1939-71";
BA_ "SigType" SG_ 2565868030 SteerWheelAngleSensorType 5;
BA_ "SPN" SG_ 2565868030 SteerWheelAngleSensorType 1812;
BA_ "SAEDocument" SG_ 2565868030 SteerWheelAngleSensorType "J1939-71";
BA_ "SPN" SG_ 2565868030 SteerWheelTurnCounter 1811;
BA_ "SAEDocument" SG_ 2565868030 SteerWheelTurnCounter "J1939-71";
BA_ "SigType" SG_ 2565868030 SteerWheelAngle 1;
BA_ "SPN" SG_ 2565868030 SteerWheelAngle 1807;
BA_ "SAEDocument" SG_ 2565868030 SteerWheelAngle "J1939-71";
BA_ "SigType" SG_ 2566803454 YCBrakeCtrlActive 5;
BA_ "SPN" SG_ 2566803454 YCBrakeCtrlActive 1819;
BA_ "SAEDocument" SG_ 2566803454 YCBrakeCtrlActive "J1939-71";
BA_ "SigType" SG_ 2566803454 YCEngCtrlActive 5;
BA_ "SPN" SG_ 2566803454 YCEngCtrlActive 1817;
BA_ "SAEDocument" SG_ 2566803454 YCEngCtrlActive "J1939-71";
BA_ "SigType" SG_ 2566803454 ROPBrakeCtrlActive 5;
BA_ "SPN" SG_ 2566803454 ROPBrakeCtrlActive 1818;
BA_ "SAEDocument" SG_ 2566803454 ROPBrakeCtrlActive "J1939-71";
BA_ "SigType" SG_ 2566803454 ROPEngCtrlActive 5;
BA_ "SPN" SG_ 2566803454 ROPEngCtrlActive 1816;
BA_ "SAEDocument" SG_ 2566803454 ROPEngCtrlActive "J1939-71";
BA_ "SigType" SG_ 2566803454 VDCBrakeLightRq 5;
BA_ "SPN" SG_ 2566803454 VDCBrakeLightRq 1815;
BA_ "SAEDocument" SG_ 2566803454 VDCBrakeLightRq "J1939-71";
BA_ "SigType" SG_ 2566803454 VDCFullyOperational 5;
BA_ "SPN" SG_ 2566803454 VDCFullyOperational 1814;
BA_ "SAEDocument" SG_ 2566803454 VDCFullyOperational "J1939-71";
BA_ "SigType" SG_ 2566803454 VDCInformationSignal 5;
BA_ "SPN" SG_ 2566803454 VDCInformationSignal 1813;
BA_ "SAEDocument" SG_ 2566803454 VDCInformationSignal "J1939-71";
BA_ "SigType" SG_ 2566840574 TotalVehicleDistance 1;
BA_ "SPN" SG_ 2566840574 TotalVehicleDistance 245;
BA_ "SAEDocument" SG_ 2566840574 TotalVehicleDistance "J1939-71";
BA_ "SigType" SG_ 2566840574 TripDistance 1;
BA_ "SPN" SG_ 2566840574 TripDistance 244;
BA_ "SAEDocument" SG_ 2566840574 TripDistance "J1939-71";
BA_ "SigType" SG_ 2633938686 TripCruiseDistance 1;
BA_ "SPN" SG_ 2633938686 TripCruiseDistance 1019;
BA_ "SAEDocument" SG_ 2633938686 TripCruiseDistance "J1939-71";
BA_ "SigType" SG_ 2633938686 TripMaxVehicleSpeed 1;
BA_ "SPN" SG_ 2633938686 TripMaxVehicleSpeed 1018;
BA_ "SAEDocument" SG_ 2633938686 TripMaxVehicleSpeed "J1939-71";
BA_ "SigType" SG_ 2633937150 TripAirCompressorOnTime 1;
BA_ "SPN" SG_ 2633937150 TripAirCompressorOnTime 1038;
BA_ "SAEDocument" SG_ 2633937150 TripAirCompressorOnTime "J1939-71";
BA_ "SigType" SG_ 2633937150 TripIdleTime 1;
BA_ "SPN" SG_ 2633937150 TripIdleTime 1037;
BA_ "SAEDocument" SG_ 2633937150 TripIdleTime "J1939-71";
BA_ "SigType" SG_ 2633937150 TripEngRunningTime 1;
BA_ "SPN" SG_ 2633937150 TripEngRunningTime 1036;
BA_ "SAEDocument" SG_ 2633937150 TripEngRunningTime "J1939-71";
BA_ "SigType" SG_ 2633937150 TripCruiseTime 1;
BA_ "SPN" SG_ 2633937150 TripCruiseTime 1034;
BA_ "SAEDocument" SG_ 2633937150 TripCruiseTime "J1939-71";
BA_ "SigType" SG_ 2633937150 TripPTOGovernorTime 1;
BA_ "SPN" SG_ 2633937150 TripPTOGovernorTime 1035;
BA_ "SAEDocument" SG_ 2633937150 TripPTOGovernorTime "J1939-71";
BA_ "SigType" SG_ 2633938174 TripTimeInDerateByEng 1;
BA_ "SPN" SG_ 2633938174 TripTimeInDerateByEng 1027;
BA_ "SAEDocument" SG_ 2633938174 TripTimeInDerateByEng "J1939-71";
BA_ "SigType" SG_ 2633938174 TripTimeInGearDown 1;
BA_ "SPN" SG_ 2633938174 TripTimeInGearDown 1026;
BA_ "SAEDocument" SG_ 2633938174 TripTimeInGearDown "J1939-71";
BA_ "SigType" SG_ 2633938174 TripTimeInTopGear 1;
BA_ "SPN" SG_ 2633938174 TripTimeInTopGear 1025;
BA_ "SAEDocument" SG_ 2633938174 TripTimeInTopGear "J1939-71";
BA_ "SigType" SG_ 2633938174 TripTimeInVSL 1;
BA_ "SPN" SG_ 2633938174 TripTimeInVSL 1024;
BA_ "SAEDocument" SG_ 2633938174 TripTimeInVSL "J1939-71";
BA_ "SigType" SG_ 2633938430 TripSuddenDecelerations 1;
BA_ "SPN" SG_ 2633938430 TripSuddenDecelerations 1023;
BA_ "SAEDocument" SG_ 2633938430 TripSuddenDecelerations "J1939-71";
BA_ "SigType" SG_ 2633938430 TrpNumberOfIdleShutdownOverrides 1;
BA_ "SPN" SG_ 2633938430 TrpNumberOfIdleShutdownOverrides 1022;
BA_ "SAEDocument" SG_ 2633938430 TrpNumberOfIdleShutdownOverrides "J1939-71";
BA_ "SigType" SG_ 2633938430 TripNumberOfIdleShutdowns 1;
BA_ "SPN" SG_ 2633938430 TripNumberOfIdleShutdowns 1021;
BA_ "SAEDocument" SG_ 2633938430 TripNumberOfIdleShutdowns "J1939-71";
BA_ "SigType" SG_ 2633938430 TripNumberOfHotShutdowns 1;
BA_ "SPN" SG_ 2633938430 TripNumberOfHotShutdowns 1020;
BA_ "SAEDocument" SG_ 2633938430 TripNumberOfHotShutdowns "J1939-71";
BA_ "SPN" SG_ 2348875518 MessageChecksum 4207;
BA_ "SAEDocument" SG_ 2348875518 MessageChecksum "J1939-71";
BA_ "SPN" SG_ 2348875518 MessageCounter 4206;
BA_ "SAEDocument" SG_ 2348875518 MessageCounter "J1939-71";
BA_ "SPN" SG_ 2348875518 EngRequestedTorqueHighResolution 4191;
BA_ "SAEDocument" SG_ 2348875518 EngRequestedTorqueHighResolution "J1939-71";
BA_ "SPN" SG_ 2348875518 TSC1CtrlPurpose 3350;
BA_ "SAEDocument" SG_ 2348875518 TSC1CtrlPurpose "J1939-71";
BA_ "SPN" SG_ 2348875518 TSC1TransRate 3349;
BA_ "SAEDocument" SG_ 2348875518 TSC1TransRate "J1939-71";
BA_ "SPN" SG_ 2348875518 EngRequestedTorque_TorqueLimit 518;
BA_ "SAEDocument" SG_ 2348875518 EngRequestedTorque_TorqueLimit "J1939-71";
BA_ "SPN" SG_ 2348875518 EngRequestedSpeed_SpeedLimit 898;
BA_ "SAEDocument" SG_ 2348875518 EngRequestedSpeed_SpeedLimit "J1939-71";
BA_ "SigType" SG_ 2348875518 OverrideCtrlModePriority 5;
BA_ "SPN" SG_ 2348875518 OverrideCtrlModePriority 897;
BA_ "SAEDocument" SG_ 2348875518 OverrideCtrlModePriority "J1939-71";
BA_ "SigType" SG_ 2348875518 EngRequestedSpeedCtrlConditions 5;
BA_ "SPN" SG_ 2348875518 EngRequestedSpeedCtrlConditions 696;
BA_ "SAEDocument" SG_ 2348875518 EngRequestedSpeedCtrlConditions "J1939-71";
BA_ "SigType" SG_ 2348875518 EngOverrideCtrlMode 5;
BA_ "SPN" SG_ 2348875518 EngOverrideCtrlMode 695;
BA_ "SAEDocument" SG_ 2348875518 EngOverrideCtrlMode "J1939-71";
BA_ "SigType" SG_ 2566766846 TransitRunStatus 5;
BA_ "SPN" SG_ 2566766846 TransitRunStatus 3046;
BA_ "SAEDocument" SG_ 2566766846 TransitRunStatus "J1939-71";
BA_ "SigType" SG_ 2566766846 VehicleUseStatus 5;
BA_ "SPN" SG_ 2566766846 VehicleUseStatus 3045;
BA_ "SAEDocument" SG_ 2566766846 VehicleUseStatus "J1939-71";
BA_ "SigType" SG_ 2566766846 SilentAlarmStatus 5;
BA_ "SPN" SG_ 2566766846 SilentAlarmStatus 3044;
BA_ "SAEDocument" SG_ 2566766846 SilentAlarmStatus "J1939-71";
BA_ "SigType" SG_ 2566766846 PatronCount 1;
BA_ "SPN" SG_ 2566766846 PatronCount 3047;
BA_ "SAEDocument" SG_ 2566766846 PatronCount "J1939-71";
BA_ "SigType" SG_ 2566766846 TypeOfPassengerCount 1;
BA_ "SPN" SG_ 2566766846 TypeOfPassengerCount 3043;
BA_ "SAEDocument" SG_ 2566766846 TypeOfPassengerCount "J1939-71";
BA_ "SPN" SG_ 2566765310 FareboxAlarmIdentifier 3181;
BA_ "SAEDocument" SG_ 2566765310 FareboxAlarmIdentifier "J1939-71";
BA_ "SigType" SG_ 2566765310 FareboxEmergencyStatus 4;
BA_ "SPN" SG_ 2566765310 FareboxEmergencyStatus 3179;
BA_ "SAEDocument" SG_ 2566765310 FareboxEmergencyStatus "J1939-71";
BA_ "SigType" SG_ 2566765566 TransferSold 1;
BA_ "SPN" SG_ 2566765566 TransferSold 3168;
BA_ "SAEDocument" SG_ 2566765566 TransferSold "J1939-71";
BA_ "SPN" SG_ 2566765566 RouteNumber 3169;
BA_ "SAEDocument" SG_ 2566765566 RouteNumber "J1939-71";
BA_ "SPN" SG_ 2566765566 TransferType 3173;
BA_ "SAEDocument" SG_ 2566765566 TransferType "J1939-71";
BA_ "SPN" SG_ 2566765566 TypeOfService 3172;
BA_ "SAEDocument" SG_ 2566765566 TypeOfService "J1939-71";
BA_ "SPN" SG_ 2566765566 InitialFareAgency 3167;
BA_ "SAEDocument" SG_ 2566765566 InitialFareAgency "J1939-71";
BA_ "SPN" SG_ 2566765566 PassCategory 3166;
BA_ "SAEDocument" SG_ 2566765566 PassCategory "J1939-71";
BA_ "SPN" SG_ 2566765566 FareValidity 3165;
BA_ "SAEDocument" SG_ 2566765566 FareValidity "J1939-71";
BA_ "SPN" SG_ 2566765566 PaymentDetails 3177;
BA_ "SAEDocument" SG_ 2566765566 PaymentDetails "J1939-71";
BA_ "SPN" SG_ 2566765566 TypeOfFare 3176;
BA_ "SAEDocument" SG_ 2566765566 TypeOfFare "J1939-71";
BA_ "SPN" SG_ 2566765566 PassengerType 3171;
BA_ "SAEDocument" SG_ 2566765566 PassengerType "J1939-71";
BA_ "SPN" SG_ 2566765566 TransactionType 3170;
BA_ "SAEDocument" SG_ 2566765566 TransactionType "J1939-71";
BA_ "SigType" SG_ 2566765822 DriversFareboxSecurityCode 1;
BA_ "SPN" SG_ 2566765822 DriversFareboxSecurityCode 3164;
BA_ "SAEDocument" SG_ 2566765822 DriversFareboxSecurityCode "J1939-71";
BA_ "SigType" SG_ 2566765822 AssignedBlock 1;
BA_ "SPN" SG_ 2566765822 AssignedBlock 3163;
BA_ "SAEDocument" SG_ 2566765822 AssignedBlock "J1939-71";
BA_ "SigType" SG_ 2566765822 AssignedRun 1;
BA_ "SPN" SG_ 2566765822 AssignedRun 3162;
BA_ "SAEDocument" SG_ 2566765822 AssignedRun "J1939-71";
BA_ "SigType" SG_ 2566765822 AssignedRoute 1;
BA_ "SPN" SG_ 2566765822 AssignedRoute 3160;
BA_ "SAEDocument" SG_ 2566765822 AssignedRoute "J1939-71";
BA_ "SigType" SG_ 2566765822 PatternNumber 1;
BA_ "SPN" SG_ 2566765822 PatternNumber 3161;
BA_ "SAEDocument" SG_ 2566765822 PatternNumber "J1939-71";
BA_ "SigType" SG_ 2566765822 TripNumber 1;
BA_ "SPN" SG_ 2566765822 TripNumber 3159;
BA_ "SAEDocument" SG_ 2566765822 TripNumber "J1939-71";
BA_ "SigType" SG_ 2566765822 FarePresets 1;
BA_ "SPN" SG_ 2566765822 FarePresets 3175;
BA_ "SAEDocument" SG_ 2566765822 FarePresets "J1939-71";
BA_ "SPN" SG_ 2566765822 TripDirection 3174;
BA_ "SAEDocument" SG_ 2566765822 TripDirection "J1939-71";
BA_ "SPN" SG_ 2566765822 TripStatus 3180;
BA_ "SAEDocument" SG_ 2566765822 TripStatus "J1939-71";
BA_ "SigType" SG_ 2566765822 FareboxServiceStatus 4;
BA_ "SPN" SG_ 2566765822 FareboxServiceStatus 3178;
BA_ "SAEDocument" SG_ 2566765822 FareboxServiceStatus "J1939-71";
BA_ "SigType" SG_ 2566766078 VehicleID 1;
BA_ "SPN" SG_ 2566766078 VehicleID 3085;
BA_ "SAEDocument" SG_ 2566766078 VehicleID "J1939-71";
BA_ "SigType" SG_ 2566766078 StrobeActivationCtrlStatus 4;
BA_ "SPN" SG_ 2566766078 StrobeActivationCtrlStatus 3082;
BA_ "SAEDocument" SG_ 2566766078 StrobeActivationCtrlStatus "J1939-71";
BA_ "SigType" SG_ 2566766078 TransitDoorEnable 4;
BA_ "SPN" SG_ 2566766078 TransitDoorEnable 3083;
BA_ "SAEDocument" SG_ 2566766078 TransitDoorEnable "J1939-71";
BA_ "SPN" SG_ 2566766078 PriorityOfRespSentByEmitter 3084;
BA_ "SAEDocument" SG_ 2566766078 PriorityOfRespSentByEmitter "J1939-71";
BA_ "SigType" SG_ 2566766078 IntrsctnPrmptionRequest_Response 4;
BA_ "SPN" SG_ 2566766078 IntrsctnPrmptionRequest_Response 3079;
BA_ "SAEDocument" SG_ 2566766078 IntrsctnPrmptionRequest_Response "J1939-71";
BA_ "SigType" SG_ 2566766078 TransitRouteIDUsage 4;
BA_ "SPN" SG_ 2566766078 TransitRouteIDUsage 3080;
BA_ "SAEDocument" SG_ 2566766078 TransitRouteIDUsage "J1939-71";
BA_ "SigType" SG_ 2566766078 RangeCodeEnable 4;
BA_ "SPN" SG_ 2566766078 RangeCodeEnable 3081;
BA_ "SAEDocument" SG_ 2566766078 RangeCodeEnable "J1939-71";
BA_ "SigType" SG_ 2566766590 NmbrOfBytsInThMlpstIdntification 1;
BA_ "SPN" SG_ 2566766590 NmbrOfBytsInThMlpstIdntification 3070;
BA_ "SAEDocument" SG_ 2566766590 NmbrOfBytsInThMlpstIdntification "J1939-71";
BA_ "SigType" SG_ 2566766334 NmbrOfBytsInThTrnstAssgndBlckIdn 1;
BA_ "SPN" SG_ 2566766334 NmbrOfBytsInThTrnstAssgndBlckIdn 3073;
BA_ "SAEDocument" SG_ 2566766334 NmbrOfBytsInThTrnstAssgndBlckIdn "J1939-71";
BA_ "SigType" SG_ 2566766334 NmbrOfBytsInThTrnstAssgndRnIdntt 1;
BA_ "SPN" SG_ 2566766334 NmbrOfBytsInThTrnstAssgndRnIdntt 3072;
BA_ "SAEDocument" SG_ 2566766334 NmbrOfBytsInThTrnstAssgndRnIdntt "J1939-71";
BA_ "SigType" SG_ 2566766334 NmbrOfBytsInThTrnstAssgndRtIdntt 1;
BA_ "SPN" SG_ 2566766334 NmbrOfBytsInThTrnstAssgndRtIdntt 3071;
BA_ "SAEDocument" SG_ 2566766334 NmbrOfBytsInThTrnstAssgndRtIdntt "J1939-71";
BA_ "SigType" SG_ 2566766334 Agency 1;
BA_ "SPN" SG_ 2566766334 Agency 3078;
BA_ "SAEDocument" SG_ 2566766334 Agency "J1939-71";
BA_ "SigType" SG_ 2561605374 ReferenceTirePressSetting_33 1;
BA_ "SPN" SG_ 2561605374 ReferenceTirePressSetting_33 521833;
BA_ "SigType" SG_ 2561605374 ReferenceTirePressSetting_32 1;
BA_ "SPN" SG_ 2561605374 ReferenceTirePressSetting_32 521832;
BA_ "SigType" SG_ 2561605374 ReferenceTirePressSetting_31 1;
BA_ "SPN" SG_ 2561605374 ReferenceTirePressSetting_31 521831;
BA_ "SigType" SG_ 2561605374 ReferenceTirePressSetting_30 1;
BA_ "SPN" SG_ 2561605374 ReferenceTirePressSetting_30 521830;
BA_ "SigType" SG_ 2561605374 ReferenceTirePressSetting_23 1;
BA_ "SPN" SG_ 2561605374 ReferenceTirePressSetting_23 521823;
BA_ "SigType" SG_ 2561605374 ReferenceTirePressSetting_22 1;
BA_ "SPN" SG_ 2561605374 ReferenceTirePressSetting_22 521822;
BA_ "SigType" SG_ 2561605374 ReferenceTirePressSetting_21 1;
BA_ "SPN" SG_ 2561605374 ReferenceTirePressSetting_21 521821;
BA_ "SigType" SG_ 2561605374 ReferenceTirePressSetting_20 1;
BA_ "SPN" SG_ 2561605374 ReferenceTirePressSetting_20 521820;
BA_ "SigType" SG_ 2561605374 ReferenceTirePressSetting_13 1;
BA_ "SPN" SG_ 2561605374 ReferenceTirePressSetting_13 521813;
BA_ "SigType" SG_ 2561605374 ReferenceTirePressSetting_12 1;
BA_ "SPN" SG_ 2561605374 ReferenceTirePressSetting_12 521812;
BA_ "SigType" SG_ 2561605374 ReferenceTirePressSetting_11 1;
BA_ "SPN" SG_ 2561605374 ReferenceTirePressSetting_11 521811;
BA_ "SigType" SG_ 2561605374 ReferenceTirePressSetting_10 1;
BA_ "SPN" SG_ 2561605374 ReferenceTirePressSetting_10 521810;
BA_ "SigType" SG_ 2561605374 ReferenceTirePressSetting_01 1;
BA_ "SPN" SG_ 2561605374 ReferenceTirePressSetting_01 521801;
BA_ "SigType" SG_ 2561605374 ReferenceTirePressSetting_00 1;
BA_ "SPN" SG_ 2561605374 ReferenceTirePressSetting_00 521800;
BA_ "SigType" SG_ 2561605374 TireLocation 1;
BA_ "SPN" SG_ 2561605374 TireLocation 3190;
BA_ "SAEDocument" SG_ 2561605374 TireLocation "J1939-71";
BA_ "SigType" SG_ 2566765054 ReferenceTirePress_33 1;
BA_ "SPN" SG_ 2566765054 ReferenceTirePress_33 521933;
BA_ "SigType" SG_ 2566765054 ReferenceTirePress_32 1;
BA_ "SPN" SG_ 2566765054 ReferenceTirePress_32 521932;
BA_ "SigType" SG_ 2566765054 ReferenceTirePress_31 1;
BA_ "SPN" SG_ 2566765054 ReferenceTirePress_31 521931;
BA_ "SigType" SG_ 2566765054 ReferenceTirePress_30 1;
BA_ "SPN" SG_ 2566765054 ReferenceTirePress_30 521930;
BA_ "SigType" SG_ 2566765054 ReferenceTirePress_23 1;
BA_ "SPN" SG_ 2566765054 ReferenceTirePress_23 521923;
BA_ "SigType" SG_ 2566765054 ReferenceTirePress_22 1;
BA_ "SPN" SG_ 2566765054 ReferenceTirePress_22 521922;
BA_ "SigType" SG_ 2566765054 ReferenceTirePress_21 1;
BA_ "SPN" SG_ 2566765054 ReferenceTirePress_21 521921;
BA_ "SigType" SG_ 2566765054 ReferenceTirePress_20 1;
BA_ "SPN" SG_ 2566765054 ReferenceTirePress_20 521920;
BA_ "SigType" SG_ 2566765054 ReferenceTirePress_13 1;
BA_ "SPN" SG_ 2566765054 ReferenceTirePress_13 521913;
BA_ "SigType" SG_ 2566765054 ReferenceTirePress_12 1;
BA_ "SPN" SG_ 2566765054 ReferenceTirePress_12 521912;
BA_ "SigType" SG_ 2566765054 ReferenceTirePress_11 1;
BA_ "SPN" SG_ 2566765054 ReferenceTirePress_11 521911;
BA_ "SigType" SG_ 2566765054 ReferenceTirePress_10 1;
BA_ "SPN" SG_ 2566765054 ReferenceTirePress_10 521910;
BA_ "SigType" SG_ 2566765054 ReferenceTirePress_01 1;
BA_ "SPN" SG_ 2566765054 ReferenceTirePress_01 521901;
BA_ "SigType" SG_ 2566765054 ReferenceTirePress_00 1;
BA_ "SPN" SG_ 2566765054 ReferenceTirePress_00 521900;
BA_ "SigType" SG_ 2566765054 TireLocation 1;
BA_ "SPN" SG_ 2566765054 TireLocation 3190;
BA_ "SAEDocument" SG_ 2566765054 TireLocation "J1939-71";
BA_ "SigType" SG_ 2633923326 SteerChannelTirePress 1;
BA_ "SPN" SG_ 2633923326 SteerChannelTirePress 146;
BA_ "SAEDocument" SG_ 2633923326 SteerChannelTirePress "J1939-71";
BA_ "SigType" SG_ 2633923326 DriveChannelTirePress 1;
BA_ "SPN" SG_ 2633923326 DriveChannelTirePress 145;
BA_ "SAEDocument" SG_ 2633923326 DriveChannelTirePress "J1939-71";
BA_ "SigType" SG_ 2633923326 TrailerTagOrPushChannelTirePress 1;
BA_ "SPN" SG_ 2633923326 TrailerTagOrPushChannelTirePress 144;
BA_ "SAEDocument" SG_ 2633923326 TrailerTagOrPushChannelTirePress "J1939-71";
BA_ "SigType" SG_ 2633923070 SteerChannelTirePressTarget 1;
BA_ "SPN" SG_ 2633923070 SteerChannelTirePressTarget 143;
BA_ "SAEDocument" SG_ 2633923070 SteerChannelTirePressTarget "J1939-71";
BA_ "SigType" SG_ 2633923070 DriveChannelTirePressTarget 1;
BA_ "SPN" SG_ 2633923070 DriveChannelTirePressTarget 142;
BA_ "SAEDocument" SG_ 2633923070 DriveChannelTirePressTarget "J1939-71";
BA_ "SigType" SG_ 2633923070 TrlrTgOrPshChnnelTirePressTarget 1;
BA_ "SPN" SG_ 2633923070 TrlrTgOrPshChnnelTirePressTarget 141;
BA_ "SAEDocument" SG_ 2633923070 TrlrTgOrPshChnnelTirePressTarget "J1939-71";
BA_ "SigType" SG_ 2633922814 PCUTrilerTagOrPushSolenoidStatus 5;
BA_ "SPN" SG_ 2633922814 PCUTrilerTagOrPushSolenoidStatus 1475;
BA_ "SAEDocument" SG_ 2633922814 PCUTrilerTagOrPushSolenoidStatus "J1939-71";
BA_ "SigType" SG_ 2633922814 PCUSupplySolenoidStatus 5;
BA_ "SPN" SG_ 2633922814 PCUSupplySolenoidStatus 1474;
BA_ "SAEDocument" SG_ 2633922814 PCUSupplySolenoidStatus "J1939-71";
BA_ "SigType" SG_ 2633922814 PCUCtrlSolenoidStatus 5;
BA_ "SPN" SG_ 2633922814 PCUCtrlSolenoidStatus 1473;
BA_ "SAEDocument" SG_ 2633922814 PCUCtrlSolenoidStatus "J1939-71";
BA_ "SigType" SG_ 2633922814 PCUDeflateSolenoidStatus 5;
BA_ "SPN" SG_ 2633922814 PCUDeflateSolenoidStatus 1472;
BA_ "SAEDocument" SG_ 2633922814 PCUDeflateSolenoidStatus "J1939-71";
BA_ "SigType" SG_ 2633922814 TirePressSupplySwitchStatus 5;
BA_ "SPN" SG_ 2633922814 TirePressSupplySwitchStatus 1471;
BA_ "SAEDocument" SG_ 2633922814 TirePressSupplySwitchStatus "J1939-71";
BA_ "SigType" SG_ 2633922814 PCUSteerSolenoidStatus 5;
BA_ "SPN" SG_ 2633922814 PCUSteerSolenoidStatus 1470;
BA_ "SAEDocument" SG_ 2633922814 PCUSteerSolenoidStatus "J1939-71";
BA_ "SigType" SG_ 2633922814 PCUDriveSolenoidStatus 5;
BA_ "SPN" SG_ 2633922814 PCUDriveSolenoidStatus 1469;
BA_ "SAEDocument" SG_ 2633922814 PCUDriveSolenoidStatus "J1939-71";
BA_ "SPN" SG_ 2633922814 DriveChannelMode 1468;
BA_ "SAEDocument" SG_ 2633922814 DriveChannelMode "J1939-71";
BA_ "SPN" SG_ 2633922814 Trailer_tagChannelMode 1467;
BA_ "SAEDocument" SG_ 2633922814 Trailer_tagChannelMode "J1939-71";
BA_ "SPN" SG_ 2633922814 SteerChannelMode 1466;
BA_ "SAEDocument" SG_ 2633922814 SteerChannelMode "J1939-71";
BA_ "SPN" SG_ 2633922814 TirePressCheckInterval 39;
BA_ "SAEDocument" SG_ 2633922814 TirePressCheckInterval "J1939-71";
BA_ "SPN" SG_ 2566845694 TirePressThresholdDetection_13 521613;
BA_ "SPN" SG_ 2566845694 TirePressThresholdDetection_12 521612;
BA_ "SPN" SG_ 2566845694 TirePressThresholdDetection_11 521611;
BA_ "SPN" SG_ 2566845694 TirePressThresholdDetection_10 521610;
BA_ "SPN" SG_ 2566845694 TirePressThresholdDetection_01 521601;
BA_ "SigType" SG_ 2566845694 TirePress_33 1;
BA_ "SPN" SG_ 2566845694 TirePress_33 521033;
BA_ "SigType" SG_ 2566845694 TirePress_32 1;
BA_ "SPN" SG_ 2566845694 TirePress_32 521032;
BA_ "SigType" SG_ 2566845694 TirePress_31 1;
BA_ "SPN" SG_ 2566845694 TirePress_31 521031;
BA_ "SigType" SG_ 2566845694 TirePress_30 1;
BA_ "SPN" SG_ 2566845694 TirePress_30 521030;
BA_ "SigType" SG_ 2566845694 TirePress_23 1;
BA_ "SPN" SG_ 2566845694 TirePress_23 521023;
BA_ "SigType" SG_ 2566845694 TirePress_22 1;
BA_ "SPN" SG_ 2566845694 TirePress_22 521022;
BA_ "SigType" SG_ 2566845694 TirePress_21 1;
BA_ "SPN" SG_ 2566845694 TirePress_21 521021;
BA_ "SigType" SG_ 2566845694 TirePress_20 1;
BA_ "SPN" SG_ 2566845694 TirePress_20 521020;
BA_ "SigType" SG_ 2566845694 TirePress_13 1;
BA_ "SPN" SG_ 2566845694 TirePress_13 521013;
BA_ "SigType" SG_ 2566845694 TirePress_12 1;
BA_ "SPN" SG_ 2566845694 TirePress_12 521012;
BA_ "SigType" SG_ 2566845694 TirePress_11 1;
BA_ "SPN" SG_ 2566845694 TirePress_11 521011;
BA_ "SigType" SG_ 2566845694 TirePress_10 1;
BA_ "SPN" SG_ 2566845694 TirePress_10 521010;
BA_ "SigType" SG_ 2566845694 TireAirLeakageRate_33 1;
BA_ "SPN" SG_ 2566845694 TireAirLeakageRate_33 521533;
BA_ "SigType" SG_ 2566845694 TireAirLeakageRate_32 1;
BA_ "SPN" SG_ 2566845694 TireAirLeakageRate_32 521532;
BA_ "SigType" SG_ 2566845694 TireAirLeakageRate_31 1;
BA_ "SPN" SG_ 2566845694 TireAirLeakageRate_31 521531;
BA_ "SigType" SG_ 2566845694 TireAirLeakageRate_30 1;
BA_ "SPN" SG_ 2566845694 TireAirLeakageRate_30 521530;
BA_ "SigType" SG_ 2566845694 TireAirLeakageRate_23 1;
BA_ "SPN" SG_ 2566845694 TireAirLeakageRate_23 521523;
BA_ "SigType" SG_ 2566845694 TireAirLeakageRate_22 1;
BA_ "SPN" SG_ 2566845694 TireAirLeakageRate_22 521522;
BA_ "SigType" SG_ 2566845694 TireAirLeakageRate_21 1;
BA_ "SPN" SG_ 2566845694 TireAirLeakageRate_21 521521;
BA_ "SigType" SG_ 2566845694 TireAirLeakageRate_20 1;
BA_ "SPN" SG_ 2566845694 TireAirLeakageRate_20 521520;
BA_ "SigType" SG_ 2566845694 TireAirLeakageRate_13 1;
BA_ "SPN" SG_ 2566845694 TireAirLeakageRate_13 521513;
BA_ "SigType" SG_ 2566845694 TireAirLeakageRate_12 1;
BA_ "SPN" SG_ 2566845694 TireAirLeakageRate_12 521512;
BA_ "SigType" SG_ 2566845694 TireAirLeakageRate_11 1;
BA_ "SPN" SG_ 2566845694 TireAirLeakageRate_11 521511;
BA_ "SigType" SG_ 2566845694 TireAirLeakageRate_10 1;
BA_ "SPN" SG_ 2566845694 TireAirLeakageRate_10 521510;
BA_ "SigType" SG_ 2566845694 TireAirLeakageRate_01 1;
BA_ "SPN" SG_ 2566845694 TireAirLeakageRate_01 521501;
BA_ "SigType" SG_ 2566845694 TireAirLeakageRate_00 1;
BA_ "SPN" SG_ 2566845694 TireAirLeakageRate_00 521500;
BA_ "SigType" SG_ 2566845694 CTIWheelSensorStatus_33 4;
BA_ "SPN" SG_ 2566845694 CTIWheelSensorStatus_33 521433;
BA_ "SigType" SG_ 2566845694 CTIWheelSensorStatus_32 4;
BA_ "SPN" SG_ 2566845694 CTIWheelSensorStatus_32 521432;
BA_ "SigType" SG_ 2566845694 CTIWheelSensorStatus_31 4;
BA_ "SPN" SG_ 2566845694 CTIWheelSensorStatus_31 521431;
BA_ "SigType" SG_ 2566845694 CTIWheelSensorStatus_30 4;
BA_ "SPN" SG_ 2566845694 CTIWheelSensorStatus_30 521430;
BA_ "SigType" SG_ 2566845694 CTIWheelSensorStatus_23 4;
BA_ "SPN" SG_ 2566845694 CTIWheelSensorStatus_23 521423;
BA_ "SigType" SG_ 2566845694 CTIWheelSensorStatus_22 4;
BA_ "SPN" SG_ 2566845694 CTIWheelSensorStatus_22 521422;
BA_ "SigType" SG_ 2566845694 CTIWheelSensorStatus_21 4;
BA_ "SPN" SG_ 2566845694 CTIWheelSensorStatus_21 521421;
BA_ "SigType" SG_ 2566845694 CTIWheelSensorStatus_20 4;
BA_ "SPN" SG_ 2566845694 CTIWheelSensorStatus_20 521420;
BA_ "SigType" SG_ 2566845694 CTIWheelSensorStatus_13 4;
BA_ "SPN" SG_ 2566845694 CTIWheelSensorStatus_13 521413;
BA_ "SigType" SG_ 2566845694 CTIWheelSensorStatus_12 4;
BA_ "SPN" SG_ 2566845694 CTIWheelSensorStatus_12 521412;
BA_ "SigType" SG_ 2566845694 CTIWheelSensorStatus_11 4;
BA_ "SPN" SG_ 2566845694 CTIWheelSensorStatus_11 521411;
BA_ "SigType" SG_ 2566845694 CTIWheelSensorStatus_10 4;
BA_ "SPN" SG_ 2566845694 CTIWheelSensorStatus_10 521410;
BA_ "SigType" SG_ 2566845694 CTIWheelSensorStatus_01 4;
BA_ "SPN" SG_ 2566845694 CTIWheelSensorStatus_01 521401;
BA_ "SigType" SG_ 2566845694 CTIWheelEndElectricalFault_33 4;
BA_ "SPN" SG_ 2566845694 CTIWheelEndElectricalFault_33 521233;
BA_ "SigType" SG_ 2566845694 CTIWheelEndElectricalFault_32 4;
BA_ "SPN" SG_ 2566845694 CTIWheelEndElectricalFault_32 521232;
BA_ "SigType" SG_ 2566845694 CTIWheelEndElectricalFault_31 4;
BA_ "SPN" SG_ 2566845694 CTIWheelEndElectricalFault_31 521231;
BA_ "SigType" SG_ 2566845694 CTIWheelEndElectricalFault_30 4;
BA_ "SPN" SG_ 2566845694 CTIWheelEndElectricalFault_30 521230;
BA_ "SigType" SG_ 2566845694 CTIWheelEndElectricalFault_23 4;
BA_ "SPN" SG_ 2566845694 CTIWheelEndElectricalFault_23 521223;
BA_ "SigType" SG_ 2566845694 CTIWheelEndElectricalFault_22 4;
BA_ "SPN" SG_ 2566845694 CTIWheelEndElectricalFault_22 521222;
BA_ "SigType" SG_ 2566845694 CTIWheelEndElectricalFault_21 4;
BA_ "SPN" SG_ 2566845694 CTIWheelEndElectricalFault_21 521221;
BA_ "SigType" SG_ 2566845694 CTIWheelEndElectricalFault_20 4;
BA_ "SPN" SG_ 2566845694 CTIWheelEndElectricalFault_20 521220;
BA_ "SigType" SG_ 2566845694 CTIWheelEndElectricalFault_13 4;
BA_ "SPN" SG_ 2566845694 CTIWheelEndElectricalFault_13 521213;
BA_ "SigType" SG_ 2566845694 CTIWheelEndElectricalFault_12 4;
BA_ "SPN" SG_ 2566845694 CTIWheelEndElectricalFault_12 521212;
BA_ "SigType" SG_ 2566845694 CTIWheelEndElectricalFault_11 4;
BA_ "SPN" SG_ 2566845694 CTIWheelEndElectricalFault_11 521211;
BA_ "SigType" SG_ 2566845694 CTIWheelEndElectricalFault_10 4;
BA_ "SPN" SG_ 2566845694 CTIWheelEndElectricalFault_10 521210;
BA_ "SigType" SG_ 2566845694 CTIWheelEndElectricalFault_01 4;
BA_ "SPN" SG_ 2566845694 CTIWheelEndElectricalFault_01 521201;
BA_ "SigType" SG_ 2566845694 CTITireStatus_33 4;
BA_ "SPN" SG_ 2566845694 CTITireStatus_33 521333;
BA_ "SigType" SG_ 2566845694 CTITireStatus_32 4;
BA_ "SPN" SG_ 2566845694 CTITireStatus_32 521332;
BA_ "SigType" SG_ 2566845694 CTITireStatus_31 4;
BA_ "SPN" SG_ 2566845694 CTITireStatus_31 521331;
BA_ "SigType" SG_ 2566845694 CTITireStatus_30 4;
BA_ "SPN" SG_ 2566845694 CTITireStatus_30 521330;
BA_ "SigType" SG_ 2566845694 CTITireStatus_23 4;
BA_ "SPN" SG_ 2566845694 CTITireStatus_23 521323;
BA_ "SigType" SG_ 2566845694 CTITireStatus_22 4;
BA_ "SPN" SG_ 2566845694 CTITireStatus_22 521322;
BA_ "SigType" SG_ 2566845694 CTITireStatus_21 4;
BA_ "SPN" SG_ 2566845694 CTITireStatus_21 521321;
BA_ "SigType" SG_ 2566845694 CTITireStatus_20 4;
BA_ "SPN" SG_ 2566845694 CTITireStatus_20 521320;
BA_ "SigType" SG_ 2566845694 CTITireStatus_13 4;
BA_ "SPN" SG_ 2566845694 CTITireStatus_13 521313;
BA_ "SigType" SG_ 2566845694 CTITireStatus_12 4;
BA_ "SPN" SG_ 2566845694 CTITireStatus_12 521312;
BA_ "SigType" SG_ 2566845694 CTITireStatus_11 4;
BA_ "SPN" SG_ 2566845694 CTITireStatus_11 521311;
BA_ "SigType" SG_ 2566845694 CTITireStatus_10 4;
BA_ "SPN" SG_ 2566845694 CTITireStatus_10 521310;
BA_ "SigType" SG_ 2566845694 CTITireStatus_01 4;
BA_ "SPN" SG_ 2566845694 CTITireStatus_01 521301;
BA_ "SigType" SG_ 2566845694 TireTemp_11 1;
BA_ "SPN" SG_ 2566845694 TireTemp_11 521111;
BA_ "SigType" SG_ 2566845694 TireTemp_33 1;
BA_ "SPN" SG_ 2566845694 TireTemp_33 521133;
BA_ "SigType" SG_ 2566845694 TireTemp_32 1;
BA_ "SPN" SG_ 2566845694 TireTemp_32 521132;
BA_ "SigType" SG_ 2566845694 TireTemp_31 1;
BA_ "SPN" SG_ 2566845694 TireTemp_31 521131;
BA_ "SigType" SG_ 2566845694 TireTemp_30 1;
BA_ "SPN" SG_ 2566845694 TireTemp_30 521130;
BA_ "SigType" SG_ 2566845694 TireTemp_23 1;
BA_ "SPN" SG_ 2566845694 TireTemp_23 521123;
BA_ "SigType" SG_ 2566845694 TireTemp_22 1;
BA_ "SPN" SG_ 2566845694 TireTemp_22 521122;
BA_ "SigType" SG_ 2566845694 TireTemp_21 1;
BA_ "SPN" SG_ 2566845694 TireTemp_21 521121;
BA_ "SigType" SG_ 2566845694 TireTemp_20 1;
BA_ "SPN" SG_ 2566845694 TireTemp_20 521120;
BA_ "SigType" SG_ 2566845694 TireTemp_13 1;
BA_ "SPN" SG_ 2566845694 TireTemp_13 521113;
BA_ "SigType" SG_ 2566845694 TireTemp_12 1;
BA_ "SPN" SG_ 2566845694 TireTemp_12 521112;
BA_ "SigType" SG_ 2566845694 TireTemp_10 1;
BA_ "SPN" SG_ 2566845694 TireTemp_10 521110;
BA_ "SigType" SG_ 2566845694 TireTemp_01 1;
BA_ "SPN" SG_ 2566845694 TireTemp_01 521101;
BA_ "SigType" SG_ 2566845694 TireTemp_00 1;
BA_ "SPN" SG_ 2566845694 TireTemp_00 521100;
BA_ "SPN" SG_ 2566845694 TirePressThresholdDetection_33 521633;
BA_ "SPN" SG_ 2566845694 TirePressThresholdDetection_32 521632;
BA_ "SPN" SG_ 2566845694 TirePressThresholdDetection_31 521631;
BA_ "SPN" SG_ 2566845694 TirePressThresholdDetection_30 521630;
BA_ "SPN" SG_ 2566845694 TirePressThresholdDetection_23 521623;
BA_ "SPN" SG_ 2566845694 TirePressThresholdDetection_22 521622;
BA_ "SPN" SG_ 2566845694 TirePressThresholdDetection_21 521621;
BA_ "SPN" SG_ 2566845694 TirePressThresholdDetection_20 521620;
BA_ "SPN" SG_ 2566845694 TirePressThresholdDetection_00 521600;
BA_ "SigType" SG_ 2566845694 TirePress_01 1;
BA_ "SPN" SG_ 2566845694 TirePress_01 521001;
BA_ "SigType" SG_ 2566845694 TirePress_00 1;
BA_ "SPN" SG_ 2566845694 TirePress_00 521000;
BA_ "SigType" SG_ 2566845694 CTIWheelSensorStatus_00 4;
BA_ "SPN" SG_ 2566845694 CTIWheelSensorStatus_00 521400;
BA_ "SigType" SG_ 2566845694 CTIWheelEndElectricalFault_00 4;
BA_ "SPN" SG_ 2566845694 CTIWheelEndElectricalFault_00 521200;
BA_ "SigType" SG_ 2566845694 CTITireStatus_00 4;
BA_ "SPN" SG_ 2566845694 CTITireStatus_00 521300;
BA_ "SigType" SG_ 2566845694 TireLocation 1;
BA_ "SPN" SG_ 2566845694 TireLocation 929;
BA_ "SAEDocument" SG_ 2566845694 TireLocation "J1939-71";
BA_ "SigType" SG_ 2633939966 TripFanOnTimeDueToAManualSwitch 1;
BA_ "SPN" SG_ 2633939966 TripFanOnTimeDueToAManualSwitch 996;
BA_ "SAEDocument" SG_ 2633939966 TripFanOnTimeDueToAManualSwitch "J1939-71";
BA_ "SigType" SG_ 2633939966 TripFanOnTime 1;
BA_ "SPN" SG_ 2633939966 TripFanOnTime 994;
BA_ "SAEDocument" SG_ 2633939966 TripFanOnTime "J1939-71";
BA_ "SigType" SG_ 2633939966 TripFanOnTimeDueToTheA_CSystem 1;
BA_ "SPN" SG_ 2633939966 TripFanOnTimeDueToTheA_CSystem 997;
BA_ "SAEDocument" SG_ 2633939966 TripFanOnTimeDueToTheA_CSystem "J1939-71";
BA_ "SigType" SG_ 2633939966 TripFanOnTimeDueToTheEngSystem 1;
BA_ "SPN" SG_ 2633939966 TripFanOnTimeDueToTheEngSystem 995;
BA_ "SAEDocument" SG_ 2633939966 TripFanOnTimeDueToTheEngSystem "J1939-71";
BA_ "SigType" SG_ 2633939710 TripDistanceInTopGear 1;
BA_ "SPN" SG_ 2633939710 TripDistanceInTopGear 1000;
BA_ "SAEDocument" SG_ 2633939710 TripDistanceInTopGear "J1939-71";
BA_ "SigType" SG_ 2633939710 TripGearDownDistance 1;
BA_ "SPN" SG_ 2633939710 TripGearDownDistance 999;
BA_ "SAEDocument" SG_ 2633939710 TripGearDownDistance "J1939-71";
BA_ "SigType" SG_ 2633939710 TripDistanceOnVSL 1;
BA_ "SPN" SG_ 2633939710 TripDistanceOnVSL 998;
BA_ "SAEDocument" SG_ 2633939710 TripDistanceOnVSL "J1939-71";
BA_ "SigType" SG_ 2564161278 AdjustLocalHourOffset 1;
BA_ "SPN" SG_ 2564161278 AdjustLocalHourOffset 1610;
BA_ "SAEDocument" SG_ 2564161278 AdjustLocalHourOffset "J1939-71";
BA_ "SigType" SG_ 2564161278 AdjustLocalMinuteOffset 1;
BA_ "SPN" SG_ 2564161278 AdjustLocalMinuteOffset 1609;
BA_ "SAEDocument" SG_ 2564161278 AdjustLocalMinuteOffset "J1939-71";
BA_ "SigType" SG_ 2564161278 AdjustYear 1;
BA_ "SPN" SG_ 2564161278 AdjustYear 1608;
BA_ "SAEDocument" SG_ 2564161278 AdjustYear "J1939-71";
BA_ "SigType" SG_ 2564161278 AdjustDay 1;
BA_ "SPN" SG_ 2564161278 AdjustDay 1607;
BA_ "SAEDocument" SG_ 2564161278 AdjustDay "J1939-71";
BA_ "SigType" SG_ 2564161278 AdjustMonth 1;
BA_ "SPN" SG_ 2564161278 AdjustMonth 1606;
BA_ "SAEDocument" SG_ 2564161278 AdjustMonth "J1939-71";
BA_ "SigType" SG_ 2564161278 AdjustHours 1;
BA_ "SPN" SG_ 2564161278 AdjustHours 1605;
BA_ "SAEDocument" SG_ 2564161278 AdjustHours "J1939-71";
BA_ "SigType" SG_ 2564161278 AdjustMinutes 1;
BA_ "SPN" SG_ 2564161278 AdjustMinutes 1604;
BA_ "SAEDocument" SG_ 2564161278 AdjustMinutes "J1939-71";
BA_ "SigType" SG_ 2564161278 AdjustSeconds 1;
BA_ "SPN" SG_ 2564161278 AdjustSeconds 1603;
BA_ "SAEDocument" SG_ 2564161278 AdjustSeconds "J1939-71";
BA_ "SigType" SG_ 2566842110 LocalHourOffset 1;
BA_ "SPN" SG_ 2566842110 LocalHourOffset 1602;
BA_ "SAEDocument" SG_ 2566842110 LocalHourOffset "J1939-71";
BA_ "SigType" SG_ 2566842110 LocalMinuteOffset 1;
BA_ "SPN" SG_ 2566842110 LocalMinuteOffset 1601;
BA_ "SAEDocument" SG_ 2566842110 LocalMinuteOffset "J1939-71";
BA_ "SigType" SG_ 2566842110 Year 1;
BA_ "SPN" SG_ 2566842110 Year 964;
BA_ "SAEDocument" SG_ 2566842110 Year "J1939-71";
BA_ "SigType" SG_ 2566842110 Day 1;
BA_ "SPN" SG_ 2566842110 Day 962;
BA_ "SAEDocument" SG_ 2566842110 Day "J1939-71";
BA_ "SigType" SG_ 2566842110 Month 1;
BA_ "SPN" SG_ 2566842110 Month 963;
BA_ "SAEDocument" SG_ 2566842110 Month "J1939-71";
BA_ "SigType" SG_ 2566842110 Hours 1;
BA_ "SPN" SG_ 2566842110 Hours 961;
BA_ "SAEDocument" SG_ 2566842110 Hours "J1939-71";
BA_ "SigType" SG_ 2566842110 Minutes 1;
BA_ "SPN" SG_ 2566842110 Minutes 960;
BA_ "SAEDocument" SG_ 2566842110 Minutes "J1939-71";
BA_ "SigType" SG_ 2566842110 Seconds 1;
BA_ "SPN" SG_ 2566842110 Seconds 959;
BA_ "SAEDocument" SG_ 2566842110 Seconds "J1939-71";
BA_ "SPN" SG_ 2566821630 EngDsrdTrboWastegateActuator2Pos 5373;
BA_ "SAEDocument" SG_ 2566821630 EngDsrdTrboWastegateActuator2Pos "J1939-71";
BA_ "SPN" SG_ 2566821630 EngTrbWstgateActuator1TempStatus 5372;
BA_ "SAEDocument" SG_ 2566821630 EngTrbWstgateActuator1TempStatus "J1939-71";
BA_ "SPN" SG_ 2566821630 EngTrbWstgtActtor1PreliminaryFMI 5371;
BA_ "SAEDocument" SG_ 2566821630 EngTrbWstgtActtor1PreliminaryFMI "J1939-71";
BA_ "SPN" SG_ 2566821630 EngDsrdTrboWastegateActuator1Pos 5370;
BA_ "SAEDocument" SG_ 2566821630 EngDsrdTrboWastegateActuator1Pos "J1939-71";
BA_ "SigType" SG_ 2566821630 EngTrbWstgteActuatorCtrlAirPress 1;
BA_ "SPN" SG_ 2566821630 EngTrbWstgteActuatorCtrlAirPress 1192;
BA_ "SAEDocument" SG_ 2566821630 EngTrbWstgteActuatorCtrlAirPress "J1939-71";
BA_ "SigType" SG_ 2566821630 EngTurboWastegateActuator4Pos 1;
BA_ "SPN" SG_ 2566821630 EngTurboWastegateActuator4Pos 1191;
BA_ "SAEDocument" SG_ 2566821630 EngTurboWastegateActuator4Pos "J1939-71";
BA_ "SigType" SG_ 2566821630 EngTurboWastegateActuator3Pos 1;
BA_ "SPN" SG_ 2566821630 EngTurboWastegateActuator3Pos 1190;
BA_ "SAEDocument" SG_ 2566821630 EngTurboWastegateActuator3Pos "J1939-71";
BA_ "SigType" SG_ 2566821630 EngTurboWastegateActuator2Pos 1;
BA_ "SPN" SG_ 2566821630 EngTurboWastegateActuator2Pos 1189;
BA_ "SAEDocument" SG_ 2566821630 EngTurboWastegateActuator2Pos "J1939-71";
BA_ "SigType" SG_ 2566821630 EngTurboWastegateActuator1Pos 1;
BA_ "SPN" SG_ 2566821630 EngTurboWastegateActuator1Pos 1188;
BA_ "SAEDocument" SG_ 2566821630 EngTurboWastegateActuator1Pos "J1939-71";
BA_ "SigType" SG_ 2365484286 VehicleOverspeed 4;
BA_ "SPN" SG_ 2365484286 VehicleOverspeed 1614;
BA_ "SAEDocument" SG_ 2365484286 VehicleOverspeed "J1939-71";
BA_ "SigType" SG_ 2365484286 VehicleMotion 4;
BA_ "SPN" SG_ 2365484286 VehicleMotion 1611;
BA_ "SAEDocument" SG_ 2365484286 VehicleMotion "J1939-71";
BA_ "SigType" SG_ 2365484286 TachographVehicleSpeed 1;
BA_ "SPN" SG_ 2365484286 TachographVehicleSpeed 1624;
BA_ "SAEDocument" SG_ 2365484286 TachographVehicleSpeed "J1939-71";
BA_ "SigType" SG_ 2365484286 TachographOutputShaftSpeed 1;
BA_ "SPN" SG_ 2365484286 TachographOutputShaftSpeed 1623;
BA_ "SAEDocument" SG_ 2365484286 TachographOutputShaftSpeed "J1939-71";
BA_ "SigType" SG_ 2365484286 DirectionIndicator 4;
BA_ "SPN" SG_ 2365484286 DirectionIndicator 1619;
BA_ "SAEDocument" SG_ 2365484286 DirectionIndicator "J1939-71";
BA_ "SigType" SG_ 2365484286 TachographPerformance 5;
BA_ "SPN" SG_ 2365484286 TachographPerformance 1620;
BA_ "SAEDocument" SG_ 2365484286 TachographPerformance "J1939-71";
BA_ "SigType" SG_ 2365484286 HandlingInformation 5;
BA_ "SPN" SG_ 2365484286 HandlingInformation 1621;
BA_ "SAEDocument" SG_ 2365484286 HandlingInformation "J1939-71";
BA_ "SigType" SG_ 2365484286 SystemEvent 5;
BA_ "SPN" SG_ 2365484286 SystemEvent 1622;
BA_ "SAEDocument" SG_ 2365484286 SystemEvent "J1939-71";
BA_ "SigType" SG_ 2365484286 DriverCardDriver2 4;
BA_ "SPN" SG_ 2365484286 DriverCardDriver2 1616;
BA_ "SAEDocument" SG_ 2365484286 DriverCardDriver2 "J1939-71";
BA_ "SPN" SG_ 2365484286 Driver2TimeRelatedStates 1618;
BA_ "SAEDocument" SG_ 2365484286 Driver2TimeRelatedStates "J1939-71";
BA_ "SigType" SG_ 2365484286 DriverCardDriver1 4;
BA_ "SPN" SG_ 2365484286 DriverCardDriver1 1615;
BA_ "SAEDocument" SG_ 2365484286 DriverCardDriver1 "J1939-71";
BA_ "SPN" SG_ 2365484286 Driver1TimeRelatedStates 1617;
BA_ "SAEDocument" SG_ 2365484286 Driver1TimeRelatedStates "J1939-71";
BA_ "SPN" SG_ 2365484286 Driver2WorkingState 1613;
BA_ "SAEDocument" SG_ 2365484286 Driver2WorkingState "J1939-71";
BA_ "SPN" SG_ 2365484286 Driver1WorkingState 1612;
BA_ "SAEDocument" SG_ 2365484286 Driver1WorkingState "J1939-71";
BA_ "SigType" SG_ 2566771710 EngTurbo4CompressorOutletTemp 1;
BA_ "SPN" SG_ 2566771710 EngTurbo4CompressorOutletTemp 2801;
BA_ "SAEDocument" SG_ 2566771710 EngTurbo4CompressorOutletTemp "J1939-71";
BA_ "SigType" SG_ 2566771710 EngTurbo3CompressorOutletTemp 1;
BA_ "SPN" SG_ 2566771710 EngTurbo3CompressorOutletTemp 2800;
BA_ "SAEDocument" SG_ 2566771710 EngTurbo3CompressorOutletTemp "J1939-71";
BA_ "SigType" SG_ 2566771710 EngTurbo2CompressorOutletTemp 1;
BA_ "SPN" SG_ 2566771710 EngTurbo2CompressorOutletTemp 2799;
BA_ "SAEDocument" SG_ 2566771710 EngTurbo2CompressorOutletTemp "J1939-71";
BA_ "SigType" SG_ 2566771710 EngTurbo1CompressorOutletTemp 1;
BA_ "SPN" SG_ 2566771710 EngTurbo1CompressorOutletTemp 2629;
BA_ "SAEDocument" SG_ 2566771710 EngTurbo1CompressorOutletTemp "J1939-71";
BA_ "SigType" SG_ 2566821886 EngTurbo4TurbineOutletTemp 1;
BA_ "SPN" SG_ 2566821886 EngTurbo4TurbineOutletTemp 1187;
BA_ "SAEDocument" SG_ 2566821886 EngTurbo4TurbineOutletTemp "J1939-71";
BA_ "SigType" SG_ 2566821886 EngTurbo3TurbineOutletTemp 1;
BA_ "SPN" SG_ 2566821886 EngTurbo3TurbineOutletTemp 1186;
BA_ "SAEDocument" SG_ 2566821886 EngTurbo3TurbineOutletTemp "J1939-71";
BA_ "SigType" SG_ 2566821886 EngTurbo2TurbineOutletTemp 1;
BA_ "SPN" SG_ 2566821886 EngTurbo2TurbineOutletTemp 1185;
BA_ "SAEDocument" SG_ 2566821886 EngTurbo2TurbineOutletTemp "J1939-71";
BA_ "SigType" SG_ 2566821886 EngTurbo1TurbineOutletTemp 1;
BA_ "SPN" SG_ 2566821886 EngTurbo1TurbineOutletTemp 1184;
BA_ "SAEDocument" SG_ 2566821886 EngTurbo1TurbineOutletTemp "J1939-71";
BA_ "SigType" SG_ 2566822142 EngTurbo4TurbineIntakeTemp 1;
BA_ "SPN" SG_ 2566822142 EngTurbo4TurbineIntakeTemp 1183;
BA_ "SAEDocument" SG_ 2566822142 EngTurbo4TurbineIntakeTemp "J1939-71";
BA_ "SigType" SG_ 2566822142 EngTurbo3TurbineIntakeTemp 1;
BA_ "SPN" SG_ 2566822142 EngTurbo3TurbineIntakeTemp 1182;
BA_ "SAEDocument" SG_ 2566822142 EngTurbo3TurbineIntakeTemp "J1939-71";
BA_ "SigType" SG_ 2566822142 EngTurbo2TurbineIntakeTemp 1;
BA_ "SPN" SG_ 2566822142 EngTurbo2TurbineIntakeTemp 1181;
BA_ "SAEDocument" SG_ 2566822142 EngTurbo2TurbineIntakeTemp "J1939-71";
BA_ "SigType" SG_ 2566822142 EngTurbo1TurbineIntakeTemp 1;
BA_ "SPN" SG_ 2566822142 EngTurbo1TurbineIntakeTemp 1180;
BA_ "SAEDocument" SG_ 2566822142 EngTurbo1TurbineIntakeTemp "J1939-71";
BA_ "SigType" SG_ 2566822398 EngTurbo4CompressorIntakePress 1;
BA_ "SPN" SG_ 2566822398 EngTurbo4CompressorIntakePress 1179;
BA_ "SAEDocument" SG_ 2566822398 EngTurbo4CompressorIntakePress "J1939-71";
BA_ "SigType" SG_ 2566822398 EngTurbo3CompressorIntakePress 1;
BA_ "SPN" SG_ 2566822398 EngTurbo3CompressorIntakePress 1178;
BA_ "SAEDocument" SG_ 2566822398 EngTurbo3CompressorIntakePress "J1939-71";
BA_ "SigType" SG_ 2566822398 EngTurbo2CompressorIntakePress 1;
BA_ "SPN" SG_ 2566822398 EngTurbo2CompressorIntakePress 1177;
BA_ "SAEDocument" SG_ 2566822398 EngTurbo2CompressorIntakePress "J1939-71";
BA_ "SigType" SG_ 2566822398 EngTurbo1CompressorIntakePress 1;
BA_ "SPN" SG_ 2566822398 EngTurbo1CompressorIntakePress 1176;
BA_ "SAEDocument" SG_ 2566822398 EngTurbo1CompressorIntakePress "J1939-71";
BA_ "SigType" SG_ 2566822654 EngTurbo4CompressorIntakeTemp 1;
BA_ "SPN" SG_ 2566822654 EngTurbo4CompressorIntakeTemp 1175;
BA_ "SAEDocument" SG_ 2566822654 EngTurbo4CompressorIntakeTemp "J1939-71";
BA_ "SigType" SG_ 2566822654 EngTurbo3CompressorIntakeTemp 1;
BA_ "SPN" SG_ 2566822654 EngTurbo3CompressorIntakeTemp 1174;
BA_ "SAEDocument" SG_ 2566822654 EngTurbo3CompressorIntakeTemp "J1939-71";
BA_ "SigType" SG_ 2566822654 EngTurbo2CompressorIntakeTemp 1;
BA_ "SPN" SG_ 2566822654 EngTurbo2CompressorIntakeTemp 1173;
BA_ "SAEDocument" SG_ 2566822654 EngTurbo2CompressorIntakeTemp "J1939-71";
BA_ "SigType" SG_ 2566822654 EngTurbo1CompressorIntakeTemp 1;
BA_ "SPN" SG_ 2566822654 EngTurbo1CompressorIntakeTemp 1172;
BA_ "SAEDocument" SG_ 2566822654 EngTurbo1CompressorIntakeTemp "J1939-71";
BA_ "SigType" SG_ 2633931774 EngTurbo4Speed 1;
BA_ "SPN" SG_ 2633931774 EngTurbo4Speed 1171;
BA_ "SAEDocument" SG_ 2633931774 EngTurbo4Speed "J1939-71";
BA_ "SigType" SG_ 2633931774 EngTurbo3Speed 1;
BA_ "SPN" SG_ 2633931774 EngTurbo3Speed 1170;
BA_ "SAEDocument" SG_ 2633931774 EngTurbo3Speed "J1939-71";
BA_ "SigType" SG_ 2633931774 EngTurbo2Speed 1;
BA_ "SPN" SG_ 2633931774 EngTurbo2Speed 1169;
BA_ "SAEDocument" SG_ 2633931774 EngTurbo2Speed "J1939-71";
BA_ "SigType" SG_ 2633931774 EngTurboLubeOilPress2 1;
BA_ "SPN" SG_ 2633931774 EngTurboLubeOilPress2 1168;
BA_ "SAEDocument" SG_ 2633931774 EngTurboLubeOilPress2 "J1939-71";
BA_ "SigType" SG_ 2566802430 TransTorqueLimit 1;
BA_ "SPN" SG_ 2566802430 TransTorqueLimit 1845;
BA_ "SAEDocument" SG_ 2566802430 TransTorqueLimit "J1939-71";
BA_ "SigType" SG_ 2566841086 TransGearRatio 1;
BA_ "SPN" SG_ 2566841086 TransGearRatio 581;
BA_ "SAEDocument" SG_ 2566841086 TransGearRatio "J1939-71";
BA_ "SigType" SG_ 2566841086 NumberOfForwardGearRatios 1;
BA_ "SPN" SG_ 2566841086 NumberOfForwardGearRatios 957;
BA_ "SAEDocument" SG_ 2566841086 NumberOfForwardGearRatios "J1939-71";
BA_ "SigType" SG_ 2566841086 NumberOfReverseGearRatios 1;
BA_ "SPN" SG_ 2566841086 NumberOfReverseGearRatios 958;
BA_ "SAEDocument" SG_ 2566841086 NumberOfReverseGearRatios "J1939-71";
BA_ "SigType" SG_ 2348941054 TransMode8 5;
BA_ "SPN" SG_ 2348941054 TransMode8 4249;
BA_ "SAEDocument" SG_ 2348941054 TransMode8 "J1939-71";
BA_ "SigType" SG_ 2348941054 TransMode7 5;
BA_ "SPN" SG_ 2348941054 TransMode7 4248;
BA_ "SAEDocument" SG_ 2348941054 TransMode7 "J1939-71";
BA_ "SigType" SG_ 2348941054 TransMode6 5;
BA_ "SPN" SG_ 2348941054 TransMode6 4247;
BA_ "SAEDocument" SG_ 2348941054 TransMode6 "J1939-71";
BA_ "SigType" SG_ 2348941054 TransMode5 5;
BA_ "SPN" SG_ 2348941054 TransMode5 4246;
BA_ "SAEDocument" SG_ 2348941054 TransMode5 "J1939-71";
BA_ "SigType" SG_ 2348941054 TrnsShftSlectorDisplayModeSwitch 4;
BA_ "SPN" SG_ 2348941054 TrnsShftSlectorDisplayModeSwitch 2985;
BA_ "SAEDocument" SG_ 2348941054 TrnsShftSlectorDisplayModeSwitch "J1939-71";
BA_ "SPN" SG_ 2348941054 TransRequestedLaunchGear 4255;
BA_ "SAEDocument" SG_ 2348941054 TransRequestedLaunchGear "J1939-71";
BA_ "SigType" SG_ 2348941054 TransMode4 5;
BA_ "SPN" SG_ 2348941054 TransMode4 1855;
BA_ "SAEDocument" SG_ 2348941054 TransMode4 "J1939-71";
BA_ "SigType" SG_ 2348941054 TransMode3 5;
BA_ "SPN" SG_ 2348941054 TransMode3 1854;
BA_ "SAEDocument" SG_ 2348941054 TransMode3 "J1939-71";
BA_ "SigType" SG_ 2348941054 TransMode2 5;
BA_ "SPN" SG_ 2348941054 TransMode2 1853;
BA_ "SAEDocument" SG_ 2348941054 TransMode2 "J1939-71";
BA_ "SigType" SG_ 2348941054 TransMode1 5;
BA_ "SPN" SG_ 2348941054 TransMode1 1852;
BA_ "SAEDocument" SG_ 2348941054 TransMode1 "J1939-71";
BA_ "SigType" SG_ 2348941054 DisengageDiffLockRqCentralRear 5;
BA_ "SPN" SG_ 2348941054 DisengageDiffLockRqCentralRear 691;
BA_ "SAEDocument" SG_ 2348941054 DisengageDiffLockRqCentralRear "J1939-71";
BA_ "SigType" SG_ 2348941054 DisengageDiffLockRqCentralFront 5;
BA_ "SPN" SG_ 2348941054 DisengageDiffLockRqCentralFront 690;
BA_ "SAEDocument" SG_ 2348941054 DisengageDiffLockRqCentralFront "J1939-71";
BA_ "SigType" SG_ 2348941054 DisengageDiffLockRqCentral 5;
BA_ "SPN" SG_ 2348941054 DisengageDiffLockRqCentral 689;
BA_ "SAEDocument" SG_ 2348941054 DisengageDiffLockRqCentral "J1939-71";
BA_ "SigType" SG_ 2348941054 DisengageDiffLockRqRearAxle2 5;
BA_ "SPN" SG_ 2348941054 DisengageDiffLockRqRearAxle2 688;
BA_ "SAEDocument" SG_ 2348941054 DisengageDiffLockRqRearAxle2 "J1939-71";
BA_ "SigType" SG_ 2348941054 DisengageDiffLockRqRearAxle1 5;
BA_ "SPN" SG_ 2348941054 DisengageDiffLockRqRearAxle1 687;
BA_ "SAEDocument" SG_ 2348941054 DisengageDiffLockRqRearAxle1 "J1939-71";
BA_ "SigType" SG_ 2348941054 DisengageDiffLockRqFrontAxle2 5;
BA_ "SPN" SG_ 2348941054 DisengageDiffLockRqFrontAxle2 686;
BA_ "SAEDocument" SG_ 2348941054 DisengageDiffLockRqFrontAxle2 "J1939-71";
BA_ "SigType" SG_ 2348941054 DisengageDiffLockRqFrontAxle1 5;
BA_ "SPN" SG_ 2348941054 DisengageDiffLockRqFrontAxle1 685;
BA_ "SAEDocument" SG_ 2348941054 DisengageDiffLockRqFrontAxle1 "J1939-71";
BA_ "SPN" SG_ 2348941054 TransRequestedGear 525;
BA_ "SAEDocument" SG_ 2348941054 TransRequestedGear "J1939-71";
BA_ "SPN" SG_ 2348941054 RequestedPercentClutchSlip 684;
BA_ "SAEDocument" SG_ 2348941054 RequestedPercentClutchSlip "J1939-71";
BA_ "SigType" SG_ 2348941054 TransReverseGearShiftInhibitRq 5;
BA_ "SPN" SG_ 2348941054 TransReverseGearShiftInhibitRq 4242;
BA_ "SAEDocument" SG_ 2348941054 TransReverseGearShiftInhibitRq "J1939-71";
BA_ "SigType" SG_ 2348941054 DisengageDrivelineRq 5;
BA_ "SPN" SG_ 2348941054 DisengageDrivelineRq 683;
BA_ "SAEDocument" SG_ 2348941054 DisengageDrivelineRq "J1939-71";
BA_ "SigType" SG_ 2348941054 TrnsTrqeConverterLockupDisableRq 5;
BA_ "SPN" SG_ 2348941054 TrnsTrqeConverterLockupDisableRq 682;
BA_ "SAEDocument" SG_ 2348941054 TrnsTrqeConverterLockupDisableRq "J1939-71";
BA_ "SigType" SG_ 2348941054 TransGearShiftInhibitRq 5;
BA_ "SPN" SG_ 2348941054 TransGearShiftInhibitRq 681;
BA_ "SAEDocument" SG_ 2348941054 TransGearShiftInhibitRq "J1939-71";
BA_ "SigType" SG_ 2566839806 EngTurboOilLevelSwitch 4;
BA_ "SPN" SG_ 2566839806 EngTurboOilLevelSwitch 1665;
BA_ "SAEDocument" SG_ 2566839806 EngTurboOilLevelSwitch "J1939-71";
BA_ "SigType" SG_ 2566839806 EngTurbo1Speed 1;
BA_ "SPN" SG_ 2566839806 EngTurbo1Speed 103;
BA_ "SAEDocument" SG_ 2566839806 EngTurbo1Speed "J1939-71";
BA_ "SigType" SG_ 2566839806 EngTurboLubeOilPress1 1;
BA_ "SPN" SG_ 2566839806 EngTurboLubeOilPress1 104;
BA_ "SAEDocument" SG_ 2566839806 EngTurboLubeOilPress1 "J1939-71";
BA_ "SigType" SG_ 2633911806 EngTotalAverageFuelEconomy 1;
BA_ "SPN" SG_ 2633911806 EngTotalAverageFuelEconomy 1835;
BA_ "SAEDocument" SG_ 2633911806 EngTotalAverageFuelEconomy "J1939-71";
BA_ "SigType" SG_ 2633911806 EngTotalAverageFuelRate 1;
BA_ "SPN" SG_ 2633911806 EngTotalAverageFuelRate 1834;
BA_ "SAEDocument" SG_ 2633911806 EngTotalAverageFuelRate "J1939-71";
BA_ "SPN" SG_ 2566775550 AirSuspensionSupplyPressRq 2608;
BA_ "SAEDocument" SG_ 2566775550 AirSuspensionSupplyPressRq "J1939-71";
BA_ "SPN" SG_ 2566775550 AuxEquipmentSupplyPressRq 2607;
BA_ "SAEDocument" SG_ 2566775550 AuxEquipmentSupplyPressRq "J1939-71";
BA_ "SPN" SG_ 2566775550 ServiceBrakeAirPressRqCircuit2 2606;
BA_ "SAEDocument" SG_ 2566775550 ServiceBrakeAirPressRqCircuit2 "J1939-71";
BA_ "SPN" SG_ 2566775550 ServiceBrakeAirPressRqCircuit1 2605;
BA_ "SAEDocument" SG_ 2566775550 ServiceBrakeAirPressRqCircuit1 "J1939-71";
BA_ "SPN" SG_ 2566775550 ParkingAnd_orTrailerAirPressRq 2604;
BA_ "SAEDocument" SG_ 2566775550 ParkingAnd_orTrailerAirPressRq "J1939-71";
BA_ "SPN" SG_ 2566775550 PneumaticSupplyPressRq 2603;
BA_ "SAEDocument" SG_ 2566775550 PneumaticSupplyPressRq "J1939-71";
BA_ "SigType" SG_ 2566819838 EngExtlShutdownAirSupplyPress 1;
BA_ "SPN" SG_ 2566819838 EngExtlShutdownAirSupplyPress 1320;
BA_ "SAEDocument" SG_ 2566819838 EngExtlShutdownAirSupplyPress "J1939-71";
BA_ "SigType" SG_ 2566839038 NmbrOfSftwreIdentificationFields 1;
BA_ "SPN" SG_ 2566839038 NmbrOfSftwreIdentificationFields 965;
BA_ "SAEDocument" SG_ 2566839038 NmbrOfSftwreIdentificationFields "J1939-71";
BA_ "SigType" SG_ 2566839038 SoftwareIdentification 1;
BA_ "SPN" SG_ 2566839038 SoftwareIdentification 234;
BA_ "SAEDocument" SG_ 2566839038 SoftwareIdentification "J1939-71";
BA_ "SigType" SG_ 2566841598 PTOShutdownHasShutdownEng 5;
BA_ "SPN" SG_ 2566841598 PTOShutdownHasShutdownEng 5404;
BA_ "SAEDocument" SG_ 2566841598 PTOShutdownHasShutdownEng "J1939-71";
BA_ "SigType" SG_ 2566841598 EngAirShutoffStatus 5;
BA_ "SPN" SG_ 2566841598 EngAirShutoffStatus 3667;
BA_ "SAEDocument" SG_ 2566841598 EngAirShutoffStatus "J1939-71";
BA_ "SigType" SG_ 2566841598 EngOverspeedTest 4;
BA_ "SPN" SG_ 2566841598 EngOverspeedTest 2812;
BA_ "SAEDocument" SG_ 2566841598 EngOverspeedTest "J1939-71";
BA_ "SigType" SG_ 2566841598 EngAirShutoffCmdStatus 5;
BA_ "SPN" SG_ 2566841598 EngAirShutoffCmdStatus 2813;
BA_ "SAEDocument" SG_ 2566841598 EngAirShutoffCmdStatus "J1939-71";
BA_ "SigType" SG_ 2566841598 EngAlarmOutputCmdStatus 5;
BA_ "SPN" SG_ 2566841598 EngAlarmOutputCmdStatus 2814;
BA_ "SAEDocument" SG_ 2566841598 EngAlarmOutputCmdStatus "J1939-71";
BA_ "SigType" SG_ 2566841598 EngAlarmAcknowledge 4;
BA_ "SPN" SG_ 2566841598 EngAlarmAcknowledge 2815;
BA_ "SAEDocument" SG_ 2566841598 EngAlarmAcknowledge "J1939-71";
BA_ "SigType" SG_ 2566841598 EngProtectionSystemConfig 5;
BA_ "SPN" SG_ 2566841598 EngProtectionSystemConfig 1111;
BA_ "SAEDocument" SG_ 2566841598 EngProtectionSystemConfig "J1939-71";
BA_ "SigType" SG_ 2566841598 EngProtectionSystemTimerState 5;
BA_ "SPN" SG_ 2566841598 EngProtectionSystemTimerState 1107;
BA_ "SAEDocument" SG_ 2566841598 EngProtectionSystemTimerState "J1939-71";
BA_ "SigType" SG_ 2566841598 EngProtectionSystemTimerOverride 5;
BA_ "SPN" SG_ 2566841598 EngProtectionSystemTimerOverride 1108;
BA_ "SAEDocument" SG_ 2566841598 EngProtectionSystemTimerOverride "J1939-71";
BA_ "SigType" SG_ 2566841598 EngPrtctnSystmApprachingShutdown 5;
BA_ "SPN" SG_ 2566841598 EngPrtctnSystmApprachingShutdown 1109;
BA_ "SAEDocument" SG_ 2566841598 EngPrtctnSystmApprachingShutdown "J1939-71";
BA_ "SigType" SG_ 2566841598 EngPrtectionSystemHasShutdownEng 5;
BA_ "SPN" SG_ 2566841598 EngPrtectionSystemHasShutdownEng 1110;
BA_ "SAEDocument" SG_ 2566841598 EngPrtectionSystemHasShutdownEng "J1939-71";
BA_ "SigType" SG_ 2566841598 EngWaitToStartLamp 5;
BA_ "SPN" SG_ 2566841598 EngWaitToStartLamp 1081;
BA_ "SAEDocument" SG_ 2566841598 EngWaitToStartLamp "J1939-71";
BA_ "SigType" SG_ 2566841598 RefrigerantHighPressSwitch 4;
BA_ "SPN" SG_ 2566841598 RefrigerantHighPressSwitch 605;
BA_ "SAEDocument" SG_ 2566841598 RefrigerantHighPressSwitch "J1939-71";
BA_ "SigType" SG_ 2566841598 RefrigerantLowPressSwitch 4;
BA_ "SPN" SG_ 2566841598 RefrigerantLowPressSwitch 875;
BA_ "SAEDocument" SG_ 2566841598 RefrigerantLowPressSwitch "J1939-71";
BA_ "SigType" SG_ 2566841598 A_CHighPressFanSwitch 4;
BA_ "SPN" SG_ 2566841598 A_CHighPressFanSwitch 985;
BA_ "SAEDocument" SG_ 2566841598 A_CHighPressFanSwitch "J1939-71";
BA_ "SigType" SG_ 2566841598 EngIdleShutdownTimerFunction 4;
BA_ "SPN" SG_ 2566841598 EngIdleShutdownTimerFunction 591;
BA_ "SAEDocument" SG_ 2566841598 EngIdleShutdownTimerFunction "J1939-71";
BA_ "SigType" SG_ 2566841598 EngIdleShutdownTimerState 5;
BA_ "SPN" SG_ 2566841598 EngIdleShutdownTimerState 590;
BA_ "SAEDocument" SG_ 2566841598 EngIdleShutdownTimerState "J1939-71";
BA_ "SigType" SG_ 2566841598 EngIdleShutdownTimerOverride 5;
BA_ "SPN" SG_ 2566841598 EngIdleShutdownTimerOverride 592;
BA_ "SAEDocument" SG_ 2566841598 EngIdleShutdownTimerOverride "J1939-71";
BA_ "SigType" SG_ 2566841598 EngIdleShutdownDriverAlertMode 5;
BA_ "SPN" SG_ 2566841598 EngIdleShutdownDriverAlertMode 594;
BA_ "SAEDocument" SG_ 2566841598 EngIdleShutdownDriverAlertMode "J1939-71";
BA_ "SigType" SG_ 2566841598 EngIdleShutdownHasShutdownEng 5;
BA_ "SPN" SG_ 2566841598 EngIdleShutdownHasShutdownEng 593;
BA_ "SAEDocument" SG_ 2566841598 EngIdleShutdownHasShutdownEng "J1939-71";
VAL_ 2565734142 ControlByte 6 "MFDB_CreateEntry" 5 "MFDB_SetMode" 4 "MFDB_Clear" 3 "MFDB_Delete" 2 "MFDB_Add" 1 "MFDB_Response" 0 "MFDB_Request" ;
VAL_ 2565734142 FilterMode 1 "PassSpecificPGNs" 0 "BlockSpecificPGNs" ;
VAL_ 2565144318 StopLevelChangeReq 3 "Take no action" 1 "Stop request" 0 "No stop request" ;
VAL_ 2565144318 RampLevelStorageReq 3 "Take no action" 1 "Store ramp level 2" 0 "Store ramp level 1" ;
VAL_ 2565144318 LevelControlReq 3 "Take no action" 1 "Enable level control" 0 "Disable level control" ;
VAL_ 2565144318 RampLevelReq 3 "Take no action" 1 "Ramp level 2" 0 "Ramp level 1" ;
VAL_ 2565144318 SteeringAxleLockingReq 3 "Take no action" 1 "Lock steering axle" 0 "Unlock steering axle" ;
VAL_ 2565144318 LiftAxle2PositionReq 3 "Take no action" 1 "Position up / tag axle unladen" 0 "Position down / tag axle laden" ;
VAL_ 2565144318 LiftAxle1PositionReq 3 "Don't care/take no action" 2 "Reserved" 1 "Position up / tag axle unladen" 0 "Position down / tag axle laden" ;
VAL_ 2565144318 TractionHelpReq 3 "Take no action" 1 "Traction help request" 0 "No traction help request" ;
VAL_ 2565144318 LevelChangeReqRearAxle 2 "Take no action" 1 "Vehicle body down (lowering)" 0 "Vehicle body up (lifting)" ;
VAL_ 2565144318 LevelChangeReqFrontAxle 2 "Take no action" 1 "Vehicle body down (lowering)" 0 "Vehicle body up (lifting)" ;
VAL_ 2565144318 RideHeightRequest 2 "Take no action" 1 "Normal level 2" 0 "Normal level 1" ;
VAL_ 2565209854 LevelControl 1 "Level control enabled" 0 "Level control disabled" ;
VAL_ 2565209854 RampLevel 1 "Body at requested ramp level" 0 "Body not at requested ramp level" ;
VAL_ 2565209854 NormalLevel 3 "Not available" 1 "Normal level 2" 0 "Normal level 1" ;
VAL_ 2565209854 StopLevelChangeAcknowledge 1 "Level change stopped" 0 "No stop request" ;
VAL_ 2565209854 LevelChangeRearAxle 1 "Body lifting/lowering active" 0 "Body lifting/lowering not active" ;
VAL_ 2565209854 LevelChangeFrontAxle 1 "Body lifting/lowering active" 0 "Body lifting/lowering not active" ;
VAL_ 2565209854 RampLevelStorage 1 "New ramp level stored" 0 "No new storage request" ;
VAL_ 2565209854 SteeringAxleLocking 1 "Steering axle locked" 0 "Steering axle unlocked" ;
VAL_ 2565209854 LiftAxle2Pos 3 "Not available" 2 "Error" 1 "Lift axle position up / tag axle unladen" 0 "Lift axle position down / tag axle laden" ;
VAL_ 2565209854 LiftAxle1Pos 3 "Not available" 2 "Error" 1 "Lift axle position up / tag axle unladen" 0 "Lift axle position down / tag axle laden" ;
VAL_ 2565209854 RampLevelPosition 3 "Not available" 1 "Ramp level 2" 0 "Ramp level 1" ;
VAL_ 2565209854 TractionHelp 1 "Traction help active" 0 "Traction help inactive" ;
VAL_ 2565209854 LevelCtrlSysRideHeightLevel 1 "Vehicle body at requested level" 0 "Vehicle body not at req. level" ;
VAL_ 2566807294 TyrePressThresholdDetect 7 "Not available" 6 "Error indicator" 5 "Not defined" 4 "Extreme under pressure" 3 "Under pressure" 2 "No warning pressure" 1 "Over pressure" 0 "Extreme over pressure" ;
VAL_ 2566807294 TyreModulePowerSupply 1 "Sufficient power supply" 0 "Insufficient power supply" ;
VAL_ 2566807294 TyreWheelIdentification2 15 "Axle position 15" 14 "Axle position 14" 13 "Axle position 13" 12 "Axle position 12" 11 "Axle position 11" 10 "Axle position 10" 9 "Axle position 9" 8 "Axle position 8" 7 "Axle position 7" 6 "Axle position 6" 5 "Axle position 5" 4 "Axle position 4" 3 "Axle position 3" 2 "Axle position 2" 1 "Axle position 1" 0 "Axle position not identified" ;
VAL_ 2566807294 TyreWheelIdentification1 15 "Wheel position 15" 14 "Wheel position 14" 13 "Wheel position 13" 12 "Wheel position 12" 11 "Wheel position 11" 10 "Wheel position 10" 9 "Wheel position 9" 8 "Wheel position 8" 7 "Wheel position 7" 6 "Wheel position 6" 5 "Wheel position 5" 4 "Wheel position 4" 3 "Wheel position 3" 2 "Wheel position 2" 1 "Wheel position 1" 0 "Wheel position not identified" ;
VAL_ 2566764798 MisfireMonitoringComplete 1 "EnabledForCycle" 0 "DisabledForRestOfCycle" ;
VAL_ 2566764798 MisfireMonitoringEnabled 1 "EnabledForCycle" 0 "DisabledForRestOfCycle" ;
VAL_ 2566764798 FuelSystemMonitoringEnabled 1 "NotCompleteCycle" 0 "CompleteCycleOrNotSupported" ;
VAL_ 2566764798 ComprehensiveComptMonComplete 1 "NotCompleteCycle" 0 "CompleteCycleOrNotSupported" ;
VAL_ 2566764798 ComprehensiveCompMonEnabled 1 "NotCompleteCycle" 0 "CompleteCycleOrNotSupported" ;
VAL_ 2566764798 SecondAirSystemMonComplete 1 "EnabledForCycle" 0 "DisabledForRestOfCycle" ;
VAL_ 2566764798 SecondAirSystemMonEnabled 1 "EnabledForCycle" 0 "DisabledForRestOfCycle" ;
VAL_ 2566764798 OxygenSensorMonComplete 1 "EnabledForCycle" 0 "DisabledForRestOfCycle" ;
VAL_ 2566764798 OxygenSensorMonEnabled 1 "NotCompleteCycle" 0 "CompleteCycleOrNotSupported" ;
VAL_ 2566764798 OxygenSensorHeaterMonComplete 1 "EnabledForCycle" 0 "DisabledForRestOfCycle" ;
VAL_ 2566764798 OxygenSensorHeaterMonEnabled 1 "NotCompleteCycle" 0 "CompleteCycleOrNotSupported" ;
VAL_ 2566764798 HeatedCatalystMonComplete 1 "EnabledForCycle" 0 "DisabledForRestOfCycle" ;
VAL_ 2566764798 HeatedCatalystMonEnabled 1 "EnabledForCycle" 0 "DisabledForRestOfCycle" ;
VAL_ 2566764798 EvaporativeSystemMonComplete 1 "NotCompleteCycle" 0 "CompleteCycleOrNotSupported" ;
VAL_ 2566764798 EvaporativeSystemMonEnabled 1 "NotCompleteCycle" 0 "CompleteCycleOrNotSupported" ;
VAL_ 2566764798 EGRSystemMonitoringComplete 1 "NotCompleteCycle" 0 "CompleteCycleOrNotSupported" ;
VAL_ 2566764798 EGRSystemMonitoringEnabled 1 "EnabledForCycle" 0 "DisabledForRestOfCycle" ;
VAL_ 2566764798 ColdStartAidSystemMonComplete 1 "EnabledForCycle" 0 "DisabledForRestOfCycle" ;
VAL_ 2566764798 ColdStartAidSystemMonEnabled 1 "EnabledForCycle" 0 "DisabledForRestOfCycle" ;
VAL_ 2566764798 CatalystMonComplete 1 "NotCompleteCycle" 0 "CompleteCycleOrNotSupported" ;
VAL_ 2566764798 CatalystMonEnabled 1 "NotCompleteCycle" 0 "CompleteCycleOrNotSupported" ;
VAL_ 2566764798 ACSystemRefrigerantMonComplete 1 "NotCompleteCycle" 0 "CompleteCycleOrNotSupported" ;
VAL_ 2566764798 ACSystemRefrigerantMonEnabled 1 "NotCompleteCycle" 0 "CompleteCycleOrNotSupported" ;
VAL_ 2566764798 FuelSystemMonitoringComplete 1 "NotCompleteCycle" 0 "CompleteCycleOrNotSupported" ;
VAL_ 2564095742 SecurityEntityType 3 "Data is Certificate" 2 "Data is Session Key" 1 "Data is Long Key" 0 "Data is Long Seed" ;
VAL_ 2349137662 XBRCtrlMode 3 "Not defined" 2 "Acceleration control with maximum mode  Execute the XBR acceleration demand if it is higher than the drivers" 1 "Acceleration control with addition mode  Add the XBR acceleration demand to the drivers acceleration demand" 0 "Override disabled  Disable any existing control commanded by the source of this command" ;
VAL_ 2349137662 XBRPriority 3 "Low priority  used in override disabled XBR Control Mode" 2 "Medium priority  used for ACCSystems This mode does not override brake protection measures of the brake" 1 "High priority  not defined" 0 "Highest priority  used for emergency situations eg for future Collision Avoidance System This mode overrides" ;
VAL_ 2349137662 XBREBIMode 3 "Not defined" 2 "Endurance Brake Integration allowed" 1 "Only Endurance Brakes allowed" 0 "No Endurance Brake Integration allowed" ;
VAL_ 2566848510 WaterInFuelIndicator 3 "Not available" 2 "Error" 1 "Yes" 0 "No" ;
VAL_ 2566843134 AxleLocation 48 "Axle3_Position0" 32 "Axle2_Position0" 16 "Axle1_Position0" 0 "Axle0_Position0" ;
VAL_ 2566809854 WinchOilPressSwitch 3 "Not Available" 2 "Error  Switch state cannot be determined" 1 "OK  Oil pressure is above minimum" 0 "NOT OK Oil pressure is too low" ;
VAL_ 2566809854 HydOilFilterRestrictionSwitch 3 "Not Available" 2 "Error" 1 "Restriction exists on oil filter" 0 "No restriction" ;
VAL_ 2565868030 SteerWheelAngleSensorType 3 "Not Available" 2 "Reserved" 1 "Absolute measuring principle" 0 "Relative measuring principle" ;
VAL_ 2566803454 YCBrakeCtrlActive 3 "Dont care/Take no action" 2 "Reserved" 1 "YC brake control active" 0 "YC brake control passive but installed" ;
VAL_ 2566803454 YCEngCtrlActive 3 "Dont care/Take no action" 2 "Reserved" 1 "YC engine control active" 0 "YC engine control passive but installed" ;
VAL_ 2566803454 ROPBrakeCtrlActive 3 "Dont care/Take no action" 2 "Reserved" 1 "ROP brake control active" 0 "ROP brake control passive but installed" ;
VAL_ 2566803454 ROPEngCtrlActive 3 "Dont care/Take no action" 2 "Reserved" 1 "ROP engine control active" 0 "ROP engine control passive but installed" ;
VAL_ 2566803454 VDCBrakeLightRq 3 "Dont care/Take no action" 2 "Reserved" 1 "Turn brake light on" 0 "Turn brake light not on" ;
VAL_ 2566803454 VDCFullyOperational 3 "Dont care/Take no action" 2 "Reserved" 1 "Fully operational" 0 "Not fully operational" ;
VAL_ 2566803454 VDCInformationSignal 3 "Dont care/Take no action" 2 "Reserved" 1 "On" 0 "Off" ;
VAL_ 2348875518 EngRequestedTorqueHighResolution 7 "0875" 1 "0125" 0 "0000" 8 "1111  not available" ;
VAL_ 2348875518 TSC1CtrlPurpose 31 "P32  Temporary Power Train Control Original use of TSC1 Command" 5 "11110  P6P31  Reserved for SAE Assignment" 4 "P5  Engine Protection" 3 "P4  Road Speed Governor" 2 "P3  PTO Governor" 1 "P2  Cruise Control" 0 "P1  Accelerator Pedal/Operator Selection" ;
VAL_ 2348875518 TSC1TransRate 7 "Use standard TSC1 transmission rates of 10 ms to engine" 6 "20 ms transmission rate" 5 "50 ms transmission rate" 4 "100 ms transmission rate" 3 "250 ms transmission rate" 2 "500 ms transmission rate" 1 "750 ms transmission rate" 0 "1000 ms transmission rate" ;
VAL_ 2348875518 OverrideCtrlModePriority 3 "Low priority" 2 "Medium priority" 1 "High priority" 0 "Highest priority" ;
VAL_ 2348875518 EngRequestedSpeedCtrlConditions 2 "Stability Optimized for driveline engaged and/or in lockup condition 1 eg vehicle driveline" 3 "Stability Optimized for driveline engaged and/or in lockup condition 2 eg PTO driveline" 1 "Stability Optimized for driveline disengaged and nonlockup conditions" 0 "Transient Optimized for driveline disengaged and nonlockup conditions" ;
VAL_ 2348875518 EngOverrideCtrlMode 3 "Speed/torque limit control  Limit speed and/or torque based on the included limit values The speed limit governor is" 2 "Torque control  Control torque to the included desired torque value" 1 "Speed control  Govern speed to the included desired speed value" 0 "Override disabled  Disable any existing control commanded by the source of this command" ;
VAL_ 2566766846 TransitRunStatus 3 "Not available" 2 "Error condition" 0 "Off" ;
VAL_ 2566766846 VehicleUseStatus 3 "Not available" 2 "Error condition" 1 "Unauthorized use" 0 "Normal use" ;
VAL_ 2566766846 SilentAlarmStatus 3 "Not available" 2 "Error condition" 1 "On" 0 "Off" ;
VAL_ 2566765310 FareboxAlarmIdentifier 25 "Maintenance access out of service" 24 "Maintenance access in service considered an alarm condition" 23 "Paper currency jam cleared" 22 "Paper currency jam" 21 "Pass/transfer jam cleared" 20 "Pass/transfer jam" 19 "Farebox reset to automatic mode" 18 "Farebox set in manual bypass" 17 "Coin dejam operated" 16 "Card/pass box full" 15 "Card/pass box less than 75 full" 14 "Card/pass box 75 full" 13 "Currency box full" 12 "Currency box less than 75 full" 11 "Currency box 75 full" 10 "Coinbox full" 9 "Coinbox 75 full" 8 "Insufficient fare accepted" 7 "Cashbox opened in service considered an alarm condition" 6 "Cashbox door timeout" 5 "Cashbox restored" 4 "Cashbox removed" 3 "Probe completed" 2 "Probe started" 1 "Voltage restored" 0 "Voltage dropout" ;
VAL_ 2566765310 FareboxEmergencyStatus 3 "Not available" 2 "Error Condition" 1 "Emergency condition" 0 "Nonemergency condition" ;
VAL_ 2566765566 TransferType 5 "Out" 4 "In" 3 "West" 2 "East" 1 "South" 0 "North" ;
VAL_ 2566765566 TypeOfService 1 "Express service" 0 "Local service" ;
VAL_ 2566765566 PaymentDetails 5 "Card" 4 "Pass" 3 "Ticket" 2 "Token" 1 "Cash" 0 "Not an upgrade" ;
VAL_ 2566765566 TypeOfFare 6 "Pass B" 5 "Pass A" 4 "Ticket B" 3 "Ticket A" 2 "Token B" 1 "Token A" 0 "Cash/No detail" ;
VAL_ 2566765566 TransactionType 7 "Free" 6 "Transfer" 5 "Permit" 4 "Card" 3 "Pass" 2 "Ticket" 1 "Token" 0 "Cash" ;
VAL_ 2566765822 FarePresets 16 "to 11111111  Reserved for assignment" 0 "to 00001111  Agency defined" ;
VAL_ 2566765822 TripDirection 5 "Out" 4 "In" 3 "West" 2 "East" 1 "South" 0 "North" ;
VAL_ 2566765822 TripStatus 4 "Undefined" 3 "Undefined" 0 "Undefined" 6 "Layover end" 5 "Layover start" 2 "Trip end" 1 "Trip start" 7 "Undefined" ;
VAL_ 2566765822 FareboxServiceStatus 3 "Not available" 2 "Error Condition" 1 "Farebox in service" 0 "Farebox out of service" ;
VAL_ 2566766078 StrobeActivationCtrlStatus 3 "Not available" 2 "Error condition" 1 "Activate strobe" 0 "Deactivate strobe" ;
VAL_ 2566766078 TransitDoorEnable 3 "Not available" 2 "Error condition" 1 "Transit door status will override strobe activation" 0 "Ignore transit door status" ;
VAL_ 2566766078 PriorityOfRespSentByEmitter 15 "Not available" 14 "Error condition" 12 "to 1101  Reserved" 11 "Priority set by hardware to high priority" 10 "Priority set by hardware to probe priority" 9 "Priority set by hardware to low priority" 4 "to 1000  Reserved" 3 "High priority" 2 "Probe priority" 1 "Low priority" 0 "Reserved" ;
VAL_ 2566766078 IntrsctnPrmptionRequest_Response 3 "Not available" 2 "Error condition" 1 "Message is a response from the emitter" 0 "Message is a request directed to the emitter" ;
VAL_ 2566766078 TransitRouteIDUsage 3 "Not available" 2 "Error condition" 1 "Transit route ID used for interleaved data if range code not enabled" 0 "Transit route ID not used for interleaved data" ;
VAL_ 2566766078 RangeCodeEnable 3 "Not available" 2 "Error condition" 1 "Range code used for interleaved data" 0 "Range code not used for interleaved data" ;
VAL_ 2561605374 TireLocation 51 "Axle3_Position3" 50 "Axle3_Position2" 49 "Axle3_Position1" 35 "Axle2_Position3" 34 "Axle2_Position2" 33 "Axle2_Position1" 19 "Axle1_Position3" 18 "Axle1_Position2" 17 "Axle1_Position1" 1 "Axle0_Position1" 48 "Axle3_Position0" 32 "Axle2_Position0" 16 "Axle1_Position0" 0 "Axle0_Position0" ;
VAL_ 2566765054 TireLocation 51 "Axle3_Position3" 50 "Axle3_Position2" 49 "Axle3_Position1" 35 "Axle2_Position3" 34 "Axle2_Position2" 33 "Axle2_Position1" 19 "Axle1_Position3" 18 "Axle1_Position2" 17 "Axle1_Position1" 1 "Axle0_Position1" 48 "Axle3_Position0" 32 "Axle2_Position0" 16 "Axle1_Position0" 0 "Axle0_Position0" ;
VAL_ 2633922814 PCUTrilerTagOrPushSolenoidStatus 3 "Not available" 2 "Error" 1 "On" 0 "Off" ;
VAL_ 2633922814 PCUSupplySolenoidStatus 3 "Not available" 2 "Error" 1 "On" 0 "Off" ;
VAL_ 2633922814 PCUCtrlSolenoidStatus 3 "Not available" 2 "Error" 1 "On" 0 "Off" ;
VAL_ 2633922814 PCUDeflateSolenoidStatus 3 "Not available" 2 "Error" 1 "On" 0 "Off" ;
VAL_ 2633922814 TirePressSupplySwitchStatus 3 "Not available" 2 "Error" 1 "On" 0 "Off" ;
VAL_ 2633922814 PCUSteerSolenoidStatus 3 "Not available" 2 "Error" 1 "On" 0 "Off" ;
VAL_ 2633922814 PCUDriveSolenoidStatus 3 "Not available" 2 "Error" 1 "On" 0 "Off" ;
VAL_ 2633922814 DriveChannelMode 15 "Not available" 14 "Error Condition" 6 "Pressure Check" 5 "Deflate Wait  System will deflate when conditions allow" 4 "Inflate Wait  System will inflate when conditions allow" 3 "Confirm" 2 "Deflate" 1 "Inflate" 0 "Maintain" ;
VAL_ 2633922814 Trailer_tagChannelMode 15 "Not available" 14 "Error Condition" 6 "Pressure Check" 5 "Deflate Wait  System will deflate when conditions allow" 4 "Inflate Wait  System will inflate when conditions allow" 3 "Confirm" 2 "Deflate" 1 "Inflate" 0 "Maintain" ;
VAL_ 2633922814 SteerChannelMode 15 "Not available" 14 "Error Condition" 6 "Pressure Check" 5 "Deflate Wait  System will deflate when conditions allow" 4 "Inflate Wait  System will inflate when conditions allow" 3 "Confirm" 2 "Deflate" 1 "Inflate" 0 "Maintain" ;
VAL_ 2566845694 TirePressThresholdDetection_13 7 "NotAvailable" 6 "ErrorIndicator" 5 "NotDefined" 4 "ExtrmUndrPrssTrPrssrIsAtALvlWhr" 3 "UndrPrssTrPrssrIsLwrThnThPrssrD" 2 "NWrnngPrssTrPrssrIsWthnThThrshl" 1 "OvrPrssTrPrssrIsHghrThnThPrssrD" 0 "ExtrmOvrPrssTrPrssrIsAtALvlWhrT" ;
VAL_ 2566845694 TirePressThresholdDetection_12 7 "NotAvailable" 6 "ErrorIndicator" 5 "NotDefined" 4 "ExtrmUndrPrssTrPrssrIsAtALvlWhr" 3 "UndrPrssTrPrssrIsLwrThnThPrssrD" 2 "NWrnngPrssTrPrssrIsWthnThThrshl" 1 "OvrPrssTrPrssrIsHghrThnThPrssrD" 0 "ExtrmOvrPrssTrPrssrIsAtALvlWhrT" ;
VAL_ 2566845694 TirePressThresholdDetection_11 7 "NotAvailable" 6 "ErrorIndicator" 5 "NotDefined" 4 "ExtrmUndrPrssTrPrssrIsAtALvlWhr" 3 "UndrPrssTrPrssrIsLwrThnThPrssrD" 2 "NWrnngPrssTrPrssrIsWthnThThrshl" 1 "OvrPrssTrPrssrIsHghrThnThPrssrD" 0 "ExtrmOvrPrssTrPrssrIsAtALvlWhrT" ;
VAL_ 2566845694 TirePressThresholdDetection_10 7 "NotAvailable" 6 "ErrorIndicator" 5 "NotDefined" 4 "ExtrmUndrPrssTrPrssrIsAtALvlWhr" 3 "UndrPrssTrPrssrIsLwrThnThPrssrD" 2 "NWrnngPrssTrPrssrIsWthnThThrshl" 1 "OvrPrssTrPrssrIsHghrThnThPrssrD" 0 "ExtrmOvrPrssTrPrssrIsAtALvlWhrT" ;
VAL_ 2566845694 TirePressThresholdDetection_01 7 "NotAvailable" 6 "ErrorIndicator" 5 "NotDefined" 4 "ExtrmUndrPrssTrPrssrIsAtALvlWhr" 3 "UndrPrssTrPrssrIsLwrThnThPrssrD" 2 "NWrnngPrssTrPrssrIsWthnThThrshl" 1 "OvrPrssTrPrssrIsHghrThnThPrssrD" 0 "ExtrmOvrPrssTrPrssrIsAtALvlWhrT" ;
VAL_ 2566845694 CTIWheelSensorStatus_33 3 "NotSupported" 2 "NotDefined" 1 "On" 0 "Off_IsolatedFromCTIPressCtrl" ;
VAL_ 2566845694 CTIWheelSensorStatus_32 3 "NotSupported" 2 "NotDefined" 1 "On" 0 "Off_IsolatedFromCTIPressCtrl" ;
VAL_ 2566845694 CTIWheelSensorStatus_31 3 "NotSupported" 2 "NotDefined" 1 "On" 0 "Off_IsolatedFromCTIPressCtrl" ;
VAL_ 2566845694 CTIWheelSensorStatus_30 3 "NotSupported" 2 "NotDefined" 1 "On" 0 "Off_IsolatedFromCTIPressCtrl" ;
VAL_ 2566845694 CTIWheelSensorStatus_23 3 "NotSupported" 2 "NotDefined" 1 "On" 0 "Off_IsolatedFromCTIPressCtrl" ;
VAL_ 2566845694 CTIWheelSensorStatus_22 3 "NotSupported" 2 "NotDefined" 1 "On" 0 "Off_IsolatedFromCTIPressCtrl" ;
VAL_ 2566845694 CTIWheelSensorStatus_21 3 "NotSupported" 2 "NotDefined" 1 "On" 0 "Off_IsolatedFromCTIPressCtrl" ;
VAL_ 2566845694 CTIWheelSensorStatus_20 3 "NotSupported" 2 "NotDefined" 1 "On" 0 "Off_IsolatedFromCTIPressCtrl" ;
VAL_ 2566845694 CTIWheelSensorStatus_13 3 "NotSupported" 2 "NotDefined" 1 "On" 0 "Off_IsolatedFromCTIPressCtrl" ;
VAL_ 2566845694 CTIWheelSensorStatus_12 3 "NotSupported" 2 "NotDefined" 1 "On" 0 "Off_IsolatedFromCTIPressCtrl" ;
VAL_ 2566845694 CTIWheelSensorStatus_11 3 "NotSupported" 2 "NotDefined" 1 "On" 0 "Off_IsolatedFromCTIPressCtrl" ;
VAL_ 2566845694 CTIWheelSensorStatus_10 3 "NotSupported" 2 "NotDefined" 1 "On" 0 "Off_IsolatedFromCTIPressCtrl" ;
VAL_ 2566845694 CTIWheelSensorStatus_01 3 "NotSupported" 2 "NotDefined" 1 "On" 0 "Off_IsolatedFromCTIPressCtrl" ;
VAL_ 2566845694 CTIWheelEndElectricalFault_33 3 "NotSupported" 2 "Error" 1 "NotDefined" 0 "Ok" ;
VAL_ 2566845694 CTIWheelEndElectricalFault_32 3 "NotSupported" 2 "Error" 1 "NotDefined" 0 "Ok" ;
VAL_ 2566845694 CTIWheelEndElectricalFault_31 3 "NotSupported" 2 "Error" 1 "NotDefined" 0 "Ok" ;
VAL_ 2566845694 CTIWheelEndElectricalFault_30 3 "NotSupported" 2 "Error" 1 "NotDefined" 0 "Ok" ;
VAL_ 2566845694 CTIWheelEndElectricalFault_23 3 "NotSupported" 2 "Error" 1 "NotDefined" 0 "Ok" ;
VAL_ 2566845694 CTIWheelEndElectricalFault_22 3 "NotSupported" 2 "Error" 1 "NotDefined" 0 "Ok" ;
VAL_ 2566845694 CTIWheelEndElectricalFault_21 3 "NotSupported" 2 "Error" 1 "NotDefined" 0 "Ok" ;
VAL_ 2566845694 CTIWheelEndElectricalFault_20 3 "NotSupported" 2 "Error" 1 "NotDefined" 0 "Ok" ;
VAL_ 2566845694 CTIWheelEndElectricalFault_13 3 "NotSupported" 2 "Error" 1 "NotDefined" 0 "Ok" ;
VAL_ 2566845694 CTIWheelEndElectricalFault_12 3 "NotSupported" 2 "Error" 1 "NotDefined" 0 "Ok" ;
VAL_ 2566845694 CTIWheelEndElectricalFault_11 3 "NotSupported" 2 "Error" 1 "NotDefined" 0 "Ok" ;
VAL_ 2566845694 CTIWheelEndElectricalFault_10 3 "NotSupported" 2 "Error" 1 "NotDefined" 0 "Ok" ;
VAL_ 2566845694 CTIWheelEndElectricalFault_01 3 "NotSupported" 2 "Error" 1 "NotDefined" 0 "Ok" ;
VAL_ 2566845694 CTITireStatus_33 3 "NotSupported" 2 "Error" 1 "TireLeakDetected" 0 "Ok" ;
VAL_ 2566845694 CTITireStatus_32 3 "NotSupported" 2 "Error" 1 "TireLeakDetected" 0 "Ok" ;
VAL_ 2566845694 CTITireStatus_31 3 "NotSupported" 2 "Error" 1 "TireLeakDetected" 0 "Ok" ;
VAL_ 2566845694 CTITireStatus_30 3 "NotSupported" 2 "Error" 1 "TireLeakDetected" 0 "Ok" ;
VAL_ 2566845694 CTITireStatus_23 3 "NotSupported" 2 "Error" 1 "TireLeakDetected" 0 "Ok" ;
VAL_ 2566845694 CTITireStatus_22 3 "NotSupported" 2 "Error" 1 "TireLeakDetected" 0 "Ok" ;
VAL_ 2566845694 CTITireStatus_21 3 "NotSupported" 2 "Error" 1 "TireLeakDetected" 0 "Ok" ;
VAL_ 2566845694 CTITireStatus_20 3 "NotSupported" 2 "Error" 1 "TireLeakDetected" 0 "Ok" ;
VAL_ 2566845694 CTITireStatus_13 3 "NotSupported" 2 "Error" 1 "TireLeakDetected" 0 "Ok" ;
VAL_ 2566845694 CTITireStatus_12 3 "NotSupported" 2 "Error" 1 "TireLeakDetected" 0 "Ok" ;
VAL_ 2566845694 CTITireStatus_11 3 "NotSupported" 2 "Error" 1 "TireLeakDetected" 0 "Ok" ;
VAL_ 2566845694 CTITireStatus_10 3 "NotSupported" 2 "Error" 1 "TireLeakDetected" 0 "Ok" ;
VAL_ 2566845694 CTITireStatus_01 3 "NotSupported" 2 "Error" 1 "TireLeakDetected" 0 "Ok" ;
VAL_ 2566845694 TirePressThresholdDetection_33 7 "NotAvailable" 6 "ErrorIndicator" 5 "NotDefined" 4 "ExtrmUndrPrssTrPrssrIsAtALvlWhr" 3 "UndrPrssTrPrssrIsLwrThnThPrssrD" 2 "NWrnngPrssTrPrssrIsWthnThThrshl" 1 "OvrPrssTrPrssrIsHghrThnThPrssrD" 0 "ExtrmOvrPrssTrPrssrIsAtALvlWhrT" ;
VAL_ 2566845694 TirePressThresholdDetection_32 7 "NotAvailable" 6 "ErrorIndicator" 5 "NotDefined" 4 "ExtrmUndrPrssTrPrssrIsAtALvlWhr" 3 "UndrPrssTrPrssrIsLwrThnThPrssrD" 2 "NWrnngPrssTrPrssrIsWthnThThrshl" 1 "OvrPrssTrPrssrIsHghrThnThPrssrD" 0 "ExtrmOvrPrssTrPrssrIsAtALvlWhrT" ;
VAL_ 2566845694 TirePressThresholdDetection_31 7 "NotAvailable" 6 "ErrorIndicator" 5 "NotDefined" 4 "ExtrmUndrPrssTrPrssrIsAtALvlWhr" 3 "UndrPrssTrPrssrIsLwrThnThPrssrD" 2 "NWrnngPrssTrPrssrIsWthnThThrshl" 1 "OvrPrssTrPrssrIsHghrThnThPrssrD" 0 "ExtrmOvrPrssTrPrssrIsAtALvlWhrT" ;
VAL_ 2566845694 TirePressThresholdDetection_30 7 "NotAvailable" 6 "ErrorIndicator" 5 "NotDefined" 4 "ExtrmUndrPrssTrPrssrIsAtALvlWhr" 3 "UndrPrssTrPrssrIsLwrThnThPrssrD" 2 "NWrnngPrssTrPrssrIsWthnThThrshl" 1 "OvrPrssTrPrssrIsHghrThnThPrssrD" 0 "ExtrmOvrPrssTrPrssrIsAtALvlWhrT" ;
VAL_ 2566845694 TirePressThresholdDetection_23 7 "NotAvailable" 6 "ErrorIndicator" 5 "NotDefined" 4 "ExtrmUndrPrssTrPrssrIsAtALvlWhr" 3 "UndrPrssTrPrssrIsLwrThnThPrssrD" 2 "NWrnngPrssTrPrssrIsWthnThThrshl" 1 "OvrPrssTrPrssrIsHghrThnThPrssrD" 0 "ExtrmOvrPrssTrPrssrIsAtALvlWhrT" ;
VAL_ 2566845694 TirePressThresholdDetection_22 7 "NotAvailable" 6 "ErrorIndicator" 5 "NotDefined" 4 "ExtrmUndrPrssTrPrssrIsAtALvlWhr" 3 "UndrPrssTrPrssrIsLwrThnThPrssrD" 2 "NWrnngPrssTrPrssrIsWthnThThrshl" 1 "OvrPrssTrPrssrIsHghrThnThPrssrD" 0 "ExtrmOvrPrssTrPrssrIsAtALvlWhrT" ;
VAL_ 2566845694 TirePressThresholdDetection_21 7 "NotAvailable" 6 "ErrorIndicator" 5 "NotDefined" 4 "ExtrmUndrPrssTrPrssrIsAtALvlWhr" 3 "UndrPrssTrPrssrIsLwrThnThPrssrD" 2 "NWrnngPrssTrPrssrIsWthnThThrshl" 1 "OvrPrssTrPrssrIsHghrThnThPrssrD" 0 "ExtrmOvrPrssTrPrssrIsAtALvlWhrT" ;
VAL_ 2566845694 TirePressThresholdDetection_20 7 "NotAvailable" 6 "ErrorIndicator" 5 "NotDefined" 4 "ExtrmUndrPrssTrPrssrIsAtALvlWhr" 3 "UndrPrssTrPrssrIsLwrThnThPrssrD" 2 "NWrnngPrssTrPrssrIsWthnThThrshl" 1 "OvrPrssTrPrssrIsHghrThnThPrssrD" 0 "ExtrmOvrPrssTrPrssrIsAtALvlWhrT" ;
VAL_ 2566845694 TirePressThresholdDetection_00 7 "NotAvailable" 6 "ErrorIndicator" 5 "NotDefined" 4 "ExtrmUndrPrssTrPrssrIsAtALvlWhr" 3 "UndrPrssTrPrssrIsLwrThnThPrssrD" 2 "NWrnngPrssTrPrssrIsWthnThThrshl" 1 "OvrPrssTrPrssrIsHghrThnThPrssrD" 0 "ExtrmOvrPrssTrPrssrIsAtALvlWhrT" ;
VAL_ 2566845694 CTIWheelSensorStatus_00 3 "NotSupported" 2 "NotDefined" 1 "On" 0 "Off_IsolatedFromCTIPressCtrl" ;
VAL_ 2566845694 CTIWheelEndElectricalFault_00 3 "NotSupported" 2 "Error" 1 "NotDefined" 0 "Ok" ;
VAL_ 2566845694 CTITireStatus_00 3 "NotSupported" 2 "Error" 1 "TireLeakDetected" 0 "Ok" ;
VAL_ 2566821630 EngTrbWstgateActuator1TempStatus 7 "Not available" 6 "Error" 5 "Not Defined" 4 "Low Most severe" 3 "Low Least severe" 2 "In Range" 1 "High Least severe" 0 "High Most severe" ;
VAL_ 2365484286 VehicleOverspeed 3 "Not available" 2 "Error" 1 "Overspeed" 0 "No overspeed" ;
VAL_ 2365484286 VehicleMotion 3 "Not available" 2 "Error" 1 "Vehicle motion detected" 0 "Vehicle motion not detected" ;
VAL_ 2365484286 DirectionIndicator 3 "Not available" 2 "Error" 1 "Reverse" 0 "Forward" ;
VAL_ 2365484286 TachographPerformance 3 "Not available" 2 "Error" 1 "Performance analysis" 0 "Normal performance" ;
VAL_ 2365484286 HandlingInformation 3 "Not available" 2 "Error" 1 "Handling information" 0 "No handling information" ;
VAL_ 2365484286 SystemEvent 3 "Not available" 2 "Error" 1 "Tachograph event" 0 "No tachograph event" ;
VAL_ 2365484286 DriverCardDriver2 3 "Not available" 2 "Error" 1 "Driver card present" 0 "Driver card not present" ;
VAL_ 2365484286 Driver2TimeRelatedStates 15 "Not available" 14 "Error" 13 "Other" 6 "Limit 6  16 h reached" 5 "Limit 5  15 min before 16 h not having 8h rest during the last 24h" 4 "Limit 4  9 h reached" 3 "Limit 3  15 min before 9 h" 2 "Limit 2  4  h reached" 1 "Limit 1  15 min before 4  h" 0 "Normal/No limits reached" ;
VAL_ 2365484286 DriverCardDriver1 3 "Not available" 2 "Error" 1 "Driver card present" 0 "Driver card not present" ;
VAL_ 2365484286 Driver1TimeRelatedStates 15 "Not available" 14 "Error" 13 "Other" 6 "Limit 6  16 h reached" 5 "Limit 5  15 min before 16 h not having 8h rest during the last 24h" 4 "Limit 4  9 h reached" 3 "Limit 3  15 min before 9 h" 2 "Limit 2  4  h reached" 1 "Limit 1  15 min before 4  h" 0 "Normal/No limits reached" ;
VAL_ 2365484286 Driver2WorkingState 7 "Not available" 6 "Error" 3 "Drive  behind wheel" 2 "Work  loading unloading working in an office" 1 "Driver available  short break" 0 "Rest  sleeping" ;
VAL_ 2365484286 Driver1WorkingState 7 "Not available" 6 "Error" 3 "Drive  behind wheel" 2 "Work  loading unloading working in an office" 1 "Driver available  short break" 0 "Rest  sleeping" ;
VAL_ 2348941054 TransMode8 3 "Take no action" 2 "Reserved" 1 "Enable" 0 "Disable" ;
VAL_ 2348941054 TransMode7 3 "Take no action" 2 "Reserved" 1 "Enable" 0 "Disable" ;
VAL_ 2348941054 TransMode6 3 "Take no action" 2 "Reserved" 1 "Enable" 0 "Disable" ;
VAL_ 2348941054 TransMode5 3 "Take no action" 2 "Reserved" 1 "Enable" 0 "Disable" ;
VAL_ 2348941054 TrnsShftSlectorDisplayModeSwitch 3 "Not available" 2 "Error" 1 "On" 0 "Off" ;
VAL_ 2348941054 TransRequestedLaunchGear 15 "Not Available" 14 "Error" 13 "Reserved" 12 "Launch the vehicle in Reverse 4" 11 "Launch the vehicle in Reverse 3" 10 "Launch the vehicle in Reverse 2" 9 "Launch the vehicle in Reverse 1" 8 "Launch the vehicle in 8th gear" 7 "Launch the vehicle in 7th gear" 6 "Launch the vehicle in 6th gear" 5 "Launch the vehicle in 5th gear" 4 "Launch the vehicle in 4th gear" 3 "Launch the vehicle in 3rd gear" 2 "Launch the vehicle in 2nd gear" 1 "Launch the vehicle in 1st gear" 0 "No specific launch gear requested use default launch gear" ;
VAL_ 2348941054 TransMode4 3 "Take no action" 2 "Reserved" 1 "Enable" 0 "Disable" ;
VAL_ 2348941054 TransMode3 3 "Take no action" 2 "Reserved" 1 "Enable" 0 "Disable" ;
VAL_ 2348941054 TransMode2 3 "Take no action" 2 "Reserved" 1 "Enable" 0 "Disable" ;
VAL_ 2348941054 TransMode1 3 "Take no action" 2 "Reserved" 1 "Enable" 0 "Disable" ;
VAL_ 2348941054 DisengageDiffLockRqCentralRear 3 "Take no action" 2 "Reserved" 1 "Disengage differential lock" 0 "Engage differential lock" ;
VAL_ 2348941054 DisengageDiffLockRqCentralFront 3 "Take no action" 2 "Reserved" 1 "Disengage differential lock" 0 "Engage differential lock" ;
VAL_ 2348941054 DisengageDiffLockRqCentral 3 "Take no action" 2 "Reserved" 1 "Disengage differential lock" 0 "Engage differential lock" ;
VAL_ 2348941054 DisengageDiffLockRqRearAxle2 3 "Take no action" 2 "Reserved" 1 "Disengage differential lock" 0 "Engage differential lock" ;
VAL_ 2348941054 DisengageDiffLockRqRearAxle1 3 "Take no action" 2 "Reserved" 1 "Disengage differential lock" 0 "Engage differential lock" ;
VAL_ 2348941054 DisengageDiffLockRqFrontAxle2 3 "Take no action" 2 "Reserved" 1 "Disengage differential lock" 0 "Engage differential lock" ;
VAL_ 2348941054 DisengageDiffLockRqFrontAxle1 3 "Take no action" 2 "Reserved" 1 "Disengage differential lock" 0 "Engage differential lock" ;
VAL_ 2348941054 TransReverseGearShiftInhibitRq 3 "Take no action" 2 "Reserved" 1 "Inhibit shifts into Reverse gear and shift transmission to Neutral if already in Reverse or attempting to shift to" 0 "Allow shifts into Reverse gear" ;
VAL_ 2348941054 DisengageDrivelineRq 2 "Reserved" 3 "Take no action" 1 "Disengage driveline" 0 "Allow driveline engagement" ;
VAL_ 2348941054 TrnsTrqeConverterLockupDisableRq 3 "Take no action" 2 "Reserved" 1 "Disable torque converter lockup" 0 "Allow torque converter lockup" ;
VAL_ 2348941054 TransGearShiftInhibitRq 2 "Reserved" 3 "Take no action leave function as is" 1 "Gear shifts are inhibited enable function" 0 "Gear shifts are allowed disable function" ;
VAL_ 2566839806 EngTurboOilLevelSwitch 3 "Not available" 2 "Error" 1 "Oil present at turbocharger" 0 "No oil present at turbocharger" ;
VAL_ 2566841598 PTOShutdownHasShutdownEng 3 "Not available" 2 "Error" 1 "Yes" 0 "No" ;
VAL_ 2566841598 EngAirShutoffStatus 3 "Not Available" 2 "Error" 1 "Air flow restricted" 0 "Air flow allowed to engine" ;
VAL_ 2566841598 EngOverspeedTest 3 "Not Available" 2 "Reserved" 1 "Engine Overspeed Test Active" 0 "Engine Overspeed Test Not Active" ;
VAL_ 2566841598 EngAirShutoffCmdStatus 0 "Air Shutoff Disabled not attempting to shutoff engine air supply" 3 "Not Available" 2 "Reserved" 1 "Air Shutoff Enabled attempting to shutoff engine air supply" ;
VAL_ 2566841598 EngAlarmOutputCmdStatus 3 "Not Available" 2 "Reserved" 1 "Engine Alarm Output Command Active" 0 "Engine Alarm Output Command Not Active" ;
VAL_ 2566841598 EngAlarmAcknowledge 3 "Not Available" 2 "Error" 1 "Engine Alarm Acknowledge Active" 0 "Engine Alarm Acknowledge Not Active" ;
VAL_ 2566841598 EngProtectionSystemConfig 3 "Not available" 2 "Error" 1 "Enabled in calibration" 0 "Disabled in calibration" ;
VAL_ 2566841598 EngProtectionSystemTimerState 3 "Not available" 2 "Error" 1 "Active" 0 "Inactive" ;
VAL_ 2566841598 EngProtectionSystemTimerOverride 3 "Not available" 2 "Error" 1 "Active" 0 "Inactive" ;
VAL_ 2566841598 EngPrtctnSystmApprachingShutdown 3 "Not available" 2 "Error" 1 "Approaching" 0 "Not approaching" ;
VAL_ 2566841598 EngPrtectionSystemHasShutdownEng 3 "Not available" 2 "Error" 1 "Yes" 0 "No" ;
VAL_ 2566841598 EngWaitToStartLamp 3 "Not available" 2 "Error" 1 "On" 0 "Off" ;
VAL_ 2566841598 RefrigerantHighPressSwitch 3 "Not available" 2 "Error" 1 "Pressure too high compressor clutch may be disengaged" 0 "Pressure normal" ;
VAL_ 2566841598 RefrigerantLowPressSwitch 3 "Not available" 2 "Error" 1 "Pressure too low compressor clutch may be disengaged" 0 "Pressure normal" ;
VAL_ 2566841598 A_CHighPressFanSwitch 3 "Not available" 2 "Error" 1 "Pressure high fan may be engaged" 0 "Pressure normal" ;
VAL_ 2566841598 EngIdleShutdownTimerFunction 3 "Not available" 2 "Error" 1 "Enabled in calibration" 0 "Disabled in calibration" ;
VAL_ 2566841598 EngIdleShutdownTimerState 3 "Not available" 2 "Error" 1 "Active" 0 "Inactive" ;
VAL_ 2566841598 EngIdleShutdownTimerOverride 3 "Not available" 2 "Error" 1 "Active" 0 "Inactive" ;
VAL_ 2566841598 EngIdleShutdownDriverAlertMode 3 "Not available" 2 "Error" 1 "Active" 0 "Inactive" ;
VAL_ 2566841598 EngIdleShutdownHasShutdownEng 3 "Not available" 2 "Error" 1 "Yes" 0 "No" ;
